VERSION "created by canmatrix"

NS_ :

BS_:

BU_: HEP IMU_MMP2 MAP DMS VIC GWS MGW ADAS FVC CR_RL CR_RR CR_FL CR_FR FR_FC AVAP

BO_ 603 MRR_0x25B: 2 ADAS
 SG_ ADAS_Fwd_Safety_Func : 7|16@0+ (1,0) [0|65535] ""  GWS

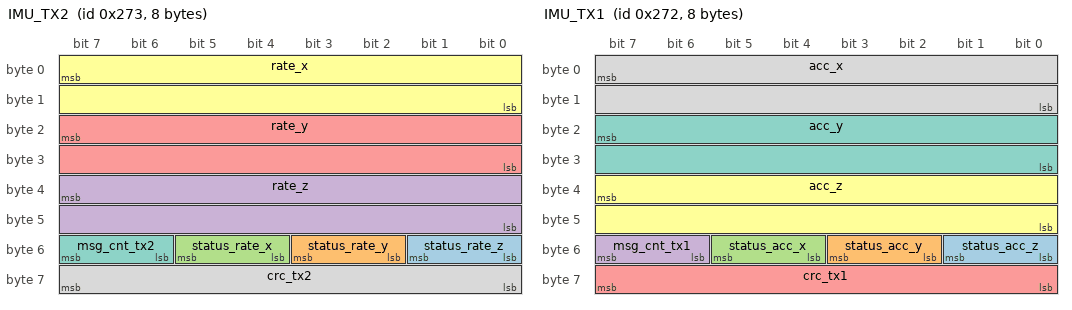
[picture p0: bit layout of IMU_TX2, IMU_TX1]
BO_ 627 IMU_TX2: 8 IMU_MMP2
 SG_ status_rate_z : 49|2@0+ (1,0) [0|3] ""  ADAS
 SG_ status_rate_y : 51|2@0+ (1,0) [0|3] ""  ADAS
 SG_ status_rate_x : 53|2@0+ (1,0) [0|3] ""  ADAS
 SG_ rate_z : 39|16@0- (0.01,0) [-327.68|327.68] "°/s"  ADAS
 SG_ rate_y : 23|16@0- (0.01,0) [-327.68|327.68] "°/s"  ADAS
 SG_ rate_x : 7|16@0- (0.01,0) [-327.68|327.68] "°/s"  ADAS
 SG_ msg_cnt_tx2 : 55|2@0+ (1,0) [0|3] ""  ADAS
 SG_ crc_tx2 : 63|8@0+ (1,0) [0|255] ""  ADAS

BO_ 626 IMU_TX1: 8 IMU_MMP2
 SG_ status_acc_z : 49|2@0+ (1,0) [0|3] ""  ADAS
 SG_ status_acc_y : 51|2@0+ (1,0) [0|3] ""  ADAS
 SG_ status_acc_x : 53|2@0+ (1,0) [0|3] ""  ADAS
 SG_ msg_cnt_tx1 : 55|2@0+ (1,0) [0|3] ""  ADAS
 SG_ crc_tx1 : 63|8@0+ (1,0) [0|255] ""  ADAS
 SG_ acc_z : 39|16@0- (0.0002,0) [-6.5536|6.5536] "g"  ADAS
 SG_ acc_y : 23|16@0- (0.0002,0) [-6.5536|6.5536] "g"  ADAS
 SG_ acc_x : 7|16@0- (0.0002,0) [-6.5536|6.5534] "g"  ADAS

BO_ 272 ADASLong_Mux: 8 HEP
 SG_ ADASLONG_Mux_MsgTyp : 7|3@0+ (1,0) [0|7] ""  ADAS

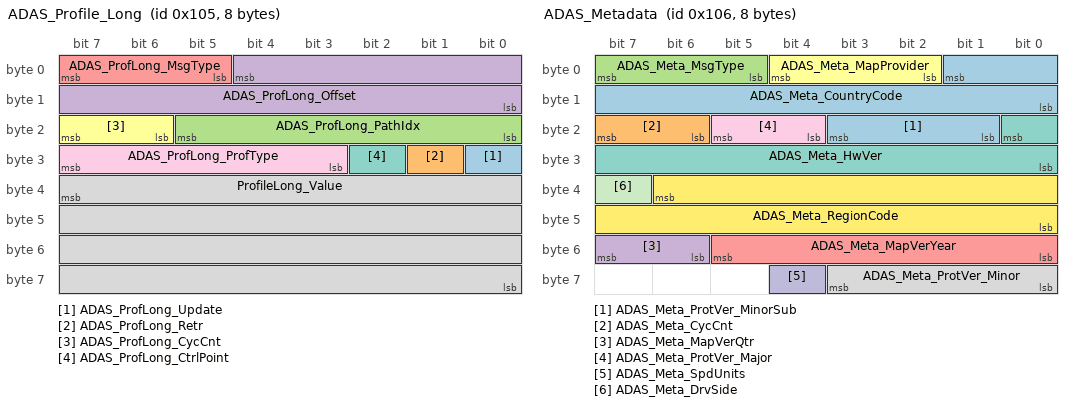
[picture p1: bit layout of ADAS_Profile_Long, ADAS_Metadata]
BO_ 261 ADAS_Profile_Long: 8 HEP
 SG_ ADAS_ProfLong_Update : 24|1@0+ (1,0) [0|0] ""  ADAS
 SG_ ADAS_ProfLong_Retr : 25|1@0+ (1,0) [0|1] ""  ADAS
 SG_ ADAS_ProfLong_PathIdx : 21|6@0+ (1,0) [8|63] ""  ADAS
 SG_ ADAS_ProfLong_Offset : 4|13@0+ (1,0) [0|8190] "m"  ADAS
 SG_ ADAS_ProfLong_MsgType : 7|3@0+ (1,0) [0|7] ""  ADAS
 SG_ ADAS_ProfLong_CycCnt : 23|2@0+ (1,0) [0|3] ""  ADAS
 SG_ ADAS_ProfLong_CtrlPoint : 26|1@0+ (1,0) [0|1] ""  ADAS
 SG_ ProfileLong_Value : 39|32@0+ (1,0) [0|0] ""  ADAS
 SG_ ADAS_ProfLong_ProfType : 31|5@0+ (1,0) [0|31] ""  ADAS

BO_ 262 ADAS_Metadata: 8 HEP
 SG_ ADAS_Meta_ProtVer_MinorSub : 19|3@0+ (1,0) [0|7] ""  ADAS
 SG_ ADAS_Meta_CycCnt : 23|2@0+ (1,0) [0|3] ""  ADAS
 SG_ ADAS_Meta_MsgType : 7|3@0+ (1,0) [0|7] ""  ADAS
 SG_ ADAS_Meta_MapVerQtr : 55|2@0+ (1,1) [1|4] "Qtr"  ADAS
 SG_ ADAS_Meta_MapVerYear : 53|6@0+ (1,2000) [2000|2063] "Year"  ADAS
 SG_ ADAS_Meta_MapProvider : 4|3@0+ (1,0) [0|7] ""  ADAS
 SG_ ADAS_Meta_HwVer : 16|9@0+ (1,0) [0|511] ""  ADAS
 SG_ ADAS_Meta_ProtVer_Minor : 59|4@0+ (1,0) [0|15] ""  ADAS
 SG_ ADAS_Meta_ProtVer_Major : 21|2@0+ (1,0) [0|3] ""  ADAS
 SG_ ADAS_Meta_SpdUnits : 60|1@0+ (1,0) [0|1] ""  ADAS
 SG_ ADAS_Meta_DrvSide : 39|1@0+ (1,0) [0|1] ""  ADAS
 SG_ ADAS_Meta_RegionCode : 38|15@0+ (1,0) [0|32767] ""  ADAS
 SG_ ADAS_Meta_CountryCode : 1|10@0+ (1,0) [0|1023] ""  ADAS

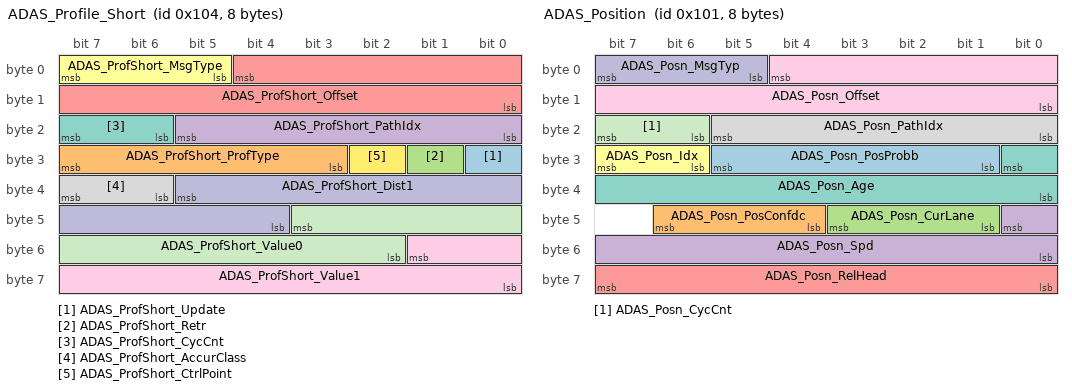
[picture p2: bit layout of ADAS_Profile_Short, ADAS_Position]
BO_ 260 ADAS_Profile_Short: 8 HEP
 SG_ ADAS_ProfShort_Update : 24|1@0+ (1,0) [0|0] ""  ADAS
 SG_ ADAS_ProfShort_ProfType : 31|5@0+ (1,0) [0|31] ""  ADAS
 SG_ ADAS_ProfShort_Retr : 25|1@0+ (1,0) [0|1] ""  ADAS
 SG_ ADAS_ProfShort_PathIdx : 21|6@0+ (1,0) [8|63] ""  ADAS
 SG_ ADAS_ProfShort_Offset : 4|13@0+ (1,0) [0|8190] "m"  ADAS
 SG_ ADAS_ProfShort_MsgType : 7|3@0+ (1,0) [0|7] ""  ADAS
 SG_ ADAS_ProfShort_CycCnt : 23|2@0+ (1,0) [0|3] ""  ADAS
 SG_ ADAS_ProfShort_AccurClass : 39|2@0+ (1,0) [0|3] ""  ADAS
 SG_ ADAS_ProfShort_Value1 : 49|10@0+ (1,0) [0|1023] ""  ADAS
 SG_ ADAS_ProfShort_Dist1 : 37|10@0+ (1,0) [0|1022] "m"  ADAS
 SG_ ADAS_ProfShort_Value0 : 43|10@0+ (1,0) [0|1023] ""  ADAS
 SG_ ADAS_ProfShort_CtrlPoint : 26|1@0+ (1,0) [0|1] ""  ADAS

BO_ 259 ADAS_Stub: 8 HEP
 SG_ ADAS_Stub_PartOfCalcRoute : 47|2@0+ (1,0) [0|3] ""  ADAS
 SG_ ADAS_Stub_FuncRoadClass : 34|3@0+ (1,0) [0|6] ""  ADAS
 SG_ ADAS_Stub_LastStub : 63|1@0+ (1,0) [0|1] ""  ADAS
 SG_ ADAS_Stub_Update : 24|1@0+ (1,0) [0|1] ""  ADAS
 SG_ ADAS_Stub_SubPathIdx : 31|6@0+ (1,0) [8|63] ""  ADAS
 SG_ ADAS_Stub_Retr : 25|1@0+ (1,0) [0|1] ""  ADAS
 SG_ ADAS_Stub_PathIdx : 21|6@0+ (1,0) [8|63] ""  ADAS
 SG_ ADAS_Stub_Offset : 4|13@0+ (1,0) [0|8190] "m"  ADAS
 SG_ ADAS_Stub_NumOfLaneOppDir : 60|2@0+ (1,0) [0|3] ""  ADAS
 SG_ ADAS_Stub_NumOfLaneDrvDir : 58|3@0+ (1,0) [0|7] ""  ADAS
 SG_ ADAS_Stub_MsgType : 7|3@0+ (1,0) [0|7] ""  ADAS
 SG_ ADAS_Stub_FormOfWay : 43|4@0+ (1,0) [0|14] ""  ADAS
 SG_ ADAS_Stub_CycCnt : 23|2@0+ (1,0) [0|3] ""  ADAS
 SG_ ADAS_Stub_RtOfWay : 62|2@0+ (1,0) [0|3] ""  ADAS
 SG_ ADAS_Stub_CmplxInsct : 45|2@0+ (1,0) [0|3] ""  ADAS
 SG_ ADAS_Stub_RelProbb : 39|5@0+ (3.333,0) [0|100] "%"  ADAS
 SG_ ADAS_Stub_TurnAngl : 55|8@0+ (1.417,0) [0|358] "deg"  ADAS

BO_ 258 ADAS_Segment: 8 HEP
 SG_ ADAS_Seg_PartOfCalcRoute : 47|2@0+ (1,0) [0|3] ""  ADAS
 SG_ ADAS_Seg_RelProbb : 39|5@0+ (3.333,0) [0|100] "%"  ADAS
 SG_ ADAS_Seg_Offset : 4|13@0+ (1,0) [0|8190] "m"  ADAS
 SG_ ADAS_Seg_Retr : 25|1@0+ (1,0) [0|1] ""  ADAS
 SG_ ADAS_Seg_PathIdx : 21|6@0+ (1,0) [8|63] ""  ADAS
 SG_ ADAS_Seg_MsgType : 7|3@0+ (1,0) [0|7] ""  ADAS
 SG_ ADAS_Seg_FormOfWay : 43|4@0+ (1,0) [0|14] ""  ADAS
 SG_ ADAS_Seg_CycCnt : 23|2@0+ (1,0) [0|3] ""  ADAS
 SG_ ADAS_Seg_CmplxInsct : 45|2@0+ (1,0) [0|3] ""  ADAS
 SG_ ADAS_Seg_BuildUpArea : 27|2@0+ (1,0) [0|3] ""  ADAS
 SG_ ADAS_Seg_DividedRoad : 62|2@0+ (1,0) [0|3] ""  ADAS
 SG_ ADAS_Seg_Bridge : 29|2@0+ (1,0) [0|3] ""  ADAS
 SG_ ADAS_Seg_Tunnel : 31|2@0+ (1,0) [0|3] ""  ADAS
 SG_ ADAS_Seg_NumOfLaneOppDir : 60|2@0+ (1,0) [0|3] ""  ADAS
 SG_ ADAS_Seg_NumOfLaneDrvDir : 58|3@0+ (1,0) [0|7] ""  ADAS
 SG_ ADAS_Seg_EffSpdLmtType : 50|3@0+ (1,0) [0|7] ""  ADAS
 SG_ ADAS_Seg_EffSpdLmt : 55|5@0+ (1,0) [0|0] "(k)mp/h"  ADAS
 SG_ ADAS_Seg_FuncRoadClass : 34|3@0+ (1,0) [0|6] ""  ADAS
 SG_ ADAS_Seg_Update : 24|1@0+ (1,0) [0|1] ""  ADAS

BO_ 257 ADAS_Position: 8 HEP
 SG_ ADAS_Posn_PosProbb : 29|5@0+ (3.333,0) [0|100] "%"  ADAS
 SG_ ADAS_Posn_PosConfdc : 46|3@0+ (1,0) [0|7] ""  ADAS
 SG_ ADAS_Posn_CurLane : 43|3@0+ (1,0) [0|7] ""  ADAS
 SG_ ADAS_Posn_Spd : 40|9@0+ (0.2,-12.8) [-12.8|89.2] "m/s"  ADAS
 SG_ ADAS_Posn_RelHead : 63|8@0+ (1.417,0) [0|358] "deg"  ADAS
 SG_ ADAS_Posn_Idx : 31|2@0+ (1,0) [0|3] ""  ADAS
 SG_ ADAS_Posn_Age : 24|9@0+ (5,0) [0|2545] "ms"  ADAS
 SG_ ADAS_Posn_PathIdx : 21|6@0+ (1,0) [8|63] ""  ADAS
 SG_ ADAS_Posn_Offset : 4|13@0+ (1,0) [0|8190] "m"  ADAS
 SG_ ADAS_Posn_MsgTyp : 7|3@0+ (1,0) [0|7] ""  ADAS
 SG_ ADAS_Posn_CycCnt : 23|2@0+ (1,0) [0|3] ""  ADAS

BO_ 1283 HIL_VP_TCC: 8 HEP
 SG_ HIL_Latitude_Cval_TCC : 0|32@1+ (1E-007,-210) [-210|211.1081215] "?"  ADAS
 SG_ HIL_Longitude_Cval_TCC : 32|32@1+ (1E-007,-210) [-210|211.1081215] "?"  ADAS

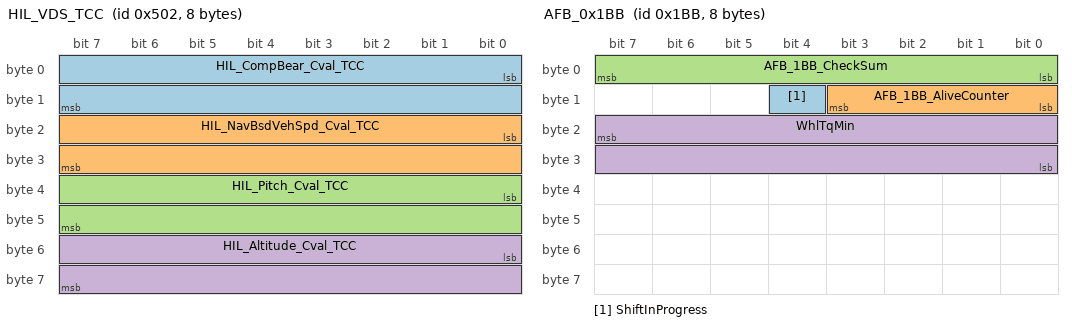
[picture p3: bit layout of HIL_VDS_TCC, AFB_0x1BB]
BO_ 1282 HIL_VDS_TCC: 8 HEP
 SG_ HIL_CompBear_Cval_TCC : 0|16@1+ (0.0078125,0) [0|501.9921875] "?"  ADAS
 SG_ HIL_NavBsdVehSpd_Cval_TCC : 16|16@1+ (0.00390625,0) [0|250.99609375] "km/h"  ADAS
 SG_ HIL_Pitch_Cval_TCC : 32|16@1+ (0.0078125,-200) [-200|301.9921875] "?"  ADAS
 SG_ HIL_Altitude_Cval_TCC : 48|16@1+ (0.125,-2500) [-2500|5531.875] "m"  ADAS

BO_ 443 AFB_0x1BB: 8 MGW
 SG_ ShiftInProgress : 12|1@0+ (1,0) [0|1] ""  ADAS
 SG_ AFB_1BB_AliveCounter : 11|4@0+ (1,0) [0|14] ""  ADAS
 SG_ AFB_1BB_CheckSum : 7|8@0+ (1,0) [0|255] ""  ADAS
 SG_ WhlTqMin : 23|16@0+ (1,-32768) [-32768|32767] "Nm"  ADAS

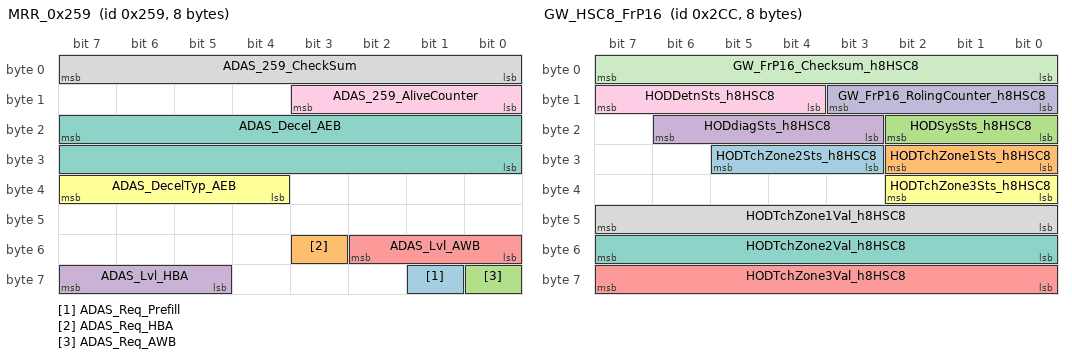
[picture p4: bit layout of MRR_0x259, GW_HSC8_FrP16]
BO_ 601 MRR_0x259: 8 ADAS
 SG_ ADAS_Req_Prefill : 57|1@0+ (1,0) [0|1] ""  MGW
 SG_ ADAS_Req_HBA : 51|1@0+ (1,0) [0|1] ""  MGW
 SG_ ADAS_Req_AWB : 56|1@0+ (1,0) [0|1] ""  MGW
 SG_ ADAS_Lvl_HBA : 63|3@0+ (1,0) [0|7] ""  MGW
 SG_ ADAS_Lvl_AWB : 50|3@0+ (1,0) [0|7] ""  MGW
 SG_ ADAS_DecelTyp_AEB : 39|4@0+ (1,0) [0|15] ""  MGW
 SG_ ADAS_Decel_AEB : 23|16@0+ (0.0004882,-16) [-16|15.994187] "m/s²"  MGW
 SG_ ADAS_259_CheckSum : 7|8@0+ (1,0) [0|255] ""  MGW
 SG_ ADAS_259_AliveCounter : 11|4@0+ (1,0) [0|15] ""  MGW

BO_ 716 GW_HSC8_FrP16: 8 MGW
 SG_ HODTchZone2Sts_h8HSC8 : 27|3@1+ (1,0) [0|7] ""  ADAS
 SG_ HODTchZone1Sts_h8HSC8 : 24|3@1+ (1,0) [0|7] ""  ADAS
 SG_ HODSysSts_h8HSC8 : 16|3@1+ (1,0) [0|7] ""  ADAS
 SG_ HODdiagSts_h8HSC8 : 19|4@1+ (1,0) [0|15] ""  ADAS
 SG_ HODTchZone3Val_h8HSC8 : 56|8@1+ (1,0) [0|255] ""  ADAS
 SG_ HODTchZone3Sts_h8HSC8 : 32|3@1+ (1,0) [0|7] ""  ADAS
 SG_ HODTchZone2Val_h8HSC8 : 48|8@1+ (1,0) [0|255] ""  ADAS
 SG_ HODTchZone1Val_h8HSC8 : 40|8@1+ (1,0) [0|255] ""  ADAS
 SG_ HODDetnSts_h8HSC8 : 12|4@1+ (1,0) [0|15] ""  ADAS
 SG_ GW_FrP16_RolingCounter_h8HSC8 : 8|4@1+ (1,0) [0|15] ""  ADAS
 SG_ GW_FrP16_Checksum_h8HSC8 : 0|8@1+ (1,0) [0|255] ""  ADAS

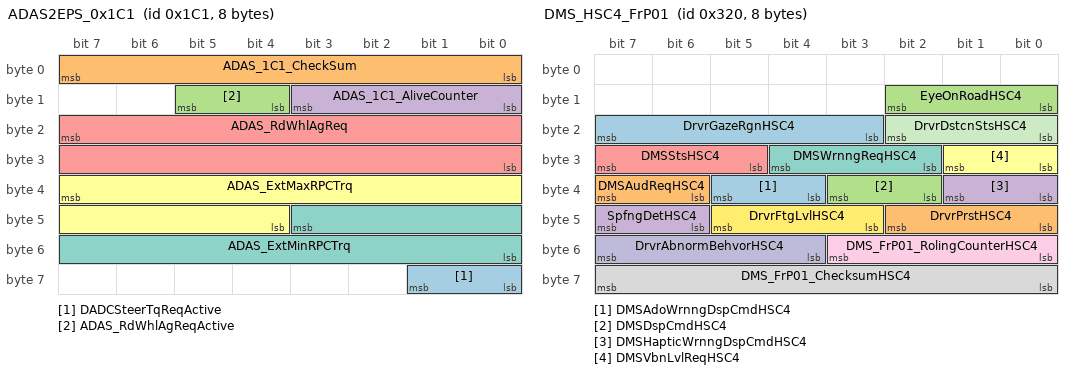
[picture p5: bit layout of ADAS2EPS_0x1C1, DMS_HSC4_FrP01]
BO_ 449 ADAS2EPS_0x1C1: 8 ADAS
 SG_ DADCSteerTqReqActive : 57|2@0+ (1,0) [0|3] ""  MGW
 SG_ ADAS_1C1_CheckSum : 7|8@0+ (1,0) [0|255] ""  MGW
 SG_ ADAS_RdWhlAgReqActive : 13|2@0+ (1,0) [0|3] ""  MGW
 SG_ ADAS_1C1_AliveCounter : 11|4@0+ (1,0) [0|15] ""  MGW
 SG_ ADAS_RdWhlAgReq : 23|16@0+ (0.005,-45) [-45|45] "degree"  MGW
 SG_ ADAS_ExtMaxRPCTrq : 39|12@0+ (0.02,-20.48) [-20.48|20.46] "Nm"  MGW
 SG_ ADAS_ExtMinRPCTrq : 43|12@0+ (0.02,-20.48) [-20.48|20.46] "Nm"  MGW

BO_ 1216 HDM_GF: 32 MAP
 SG_ GF_map_position_accuracy : 200|12@1+ (1,0) [0|4095] "cm"  ADAS
 SG_ GF_map_position_deviation : 188|12@1+ (1,0) [0|4095] "cm"  ADAS
 SG_ GF_CRC : 0|16@1+ (1,0) [0|65535] ""  ADAS
 SG_ GF_AliveCtr : 16|8@1+ (1,0) [0|255] ""  ADAS
 SG_ GF_Currentlane_Index : 176|8@1+ (1,0) [0|255] ""  ADAS
 SG_ GF_NumberOfLanes : 184|4@1+ (1,0) [0|15] ""  ADAS
 SG_ GF_Region_outOfODD_offset : 24|10@1+ (1,0) [0|1023] "m"  ADAS
 SG_ GF_Country_outOfODD_offset : 34|10@1+ (1,0) [0|1023] "m"  ADAS
 SG_ GF_LaneTrans_outOfODD_offset : 44|10@1+ (1,0) [0|1023] "m"  ADAS
 SG_ GF_Curvature_outOfODD_offset : 54|10@1+ (1,0) [0|1023] "m"  ADAS
 SG_ GF_LaneType_outOfODD_offset : 64|10@1+ (1,0) [0|1023] "m"  ADAS
 SG_ GF_RoadSlope_outOfODD_offset : 74|10@1+ (1,0) [0|1023] "m"  ADAS
 SG_ GF_LaneWidth_outOfODD_offset : 84|10@1+ (1,0) [0|1023] "m"  ADAS
 SG_ GF_FormOfWay_outOfODD_offset : 94|10@1+ (1,0) [0|1023] "m"  ADAS
 SG_ GF_MapExpired : 224|1@1+ (1,0) [0|1] "boolean"  ADAS
 SG_ GF_BlackListedSegment_offset : 114|10@1+ (1,0) [0|1023] "m"  ADAS
 SG_ GF_Intersection_offset : 104|10@1+ (1,0) [0|1023] "m"  ADAS
 SG_ GF_SideWind_offset : 124|10@1+ (1,0) [0|1023] "m"  ADAS
 SG_ GF_ActiveSpeedLimit : 168|8@1+ (1,0) [0|255] "km/h"  ADAS
 SG_ GF_TollGate_offset : 134|10@1+ (1,0) [0|1023] "m"  ADAS
 SG_ GF_TrafficLight_offset : 144|10@1+ (1,0) [0|1023] "m"  ADAS
 SG_ GF_Tunnel_Offset : 154|10@1+ (1,0) [0|1023] "m"  ADAS
 SG_ GF_MapStatus : 212|10@1+ (1,0) [0|1023] ""  ADAS

BO_ 1217 HDM_Curv: 64 MAP
 SG_ Cv_CRC : 0|16@1+ (1,0) [0|65535] ""  ADAS
 SG_ Cv_AliveCtr : 16|8@1+ (1,0) [0|255] ""  ADAS
 SG_ Cv_Value_Seg00 : 32|10@1+ (0.0001,0) [0|0.1] "1/m"  ADAS
 SG_ Cv_Value_Seg01 : 42|10@1+ (0.0001,0) [0|0.1] "1/m"  ADAS
 SG_ Cv_Value_Seg02 : 52|10@1+ (0.0001,0) [0|0.1] "1/m"  ADAS
 SG_ Cv_Value_Seg03 : 62|10@1+ (0.0001,0) [0|0.1] "1/m"  ADAS
 SG_ Cv_Value_Seg04 : 72|10@1+ (0.0001,0) [0|0.1] "1/m"  ADAS
 SG_ Cv_Value_Seg05 : 82|10@1+ (0.0001,0) [0|0.1] "1/m"  ADAS
 SG_ Cv_Value_Seg06 : 92|10@1+ (0.0001,0) [0|0.1] "1/m"  ADAS
 SG_ Cv_Value_Seg07 : 102|10@1+ (0.0001,0) [0|0.1] "1/m"  ADAS
 SG_ Cv_Value_Seg08 : 112|10@1+ (0.0001,0) [0|0.1] "1/m"  ADAS
 SG_ Cv_Value_Seg09 : 122|10@1+ (0.0001,0) [0|0.1] "1/m"  ADAS
 SG_ Cv_Value_Seg10 : 132|10@1+ (0.0001,0) [0|0.1] "1/m"  ADAS
 SG_ Cv_Value_Seg11 : 142|10@1+ (0.0001,0) [0|0.1] "1/m"  ADAS
 SG_ Cv_Value_Seg12 : 152|10@1+ (0.0001,0) [0|0.1] "1/m"  ADAS
 SG_ Cv_Value_Seg13 : 162|10@1+ (0.0001,0) [0|0.1] "1/m"  ADAS
 SG_ Cv_Value_Seg14 : 172|10@1+ (0.0001,0) [0|0.1] "1/m"  ADAS
 SG_ Cv_Value_Seg15 : 182|10@1+ (0.0001,0) [0|0.1] "1/m"  ADAS
 SG_ Cv_Value_Seg16 : 192|10@1+ (0.0001,0) [0|0.1] "1/m"  ADAS
 SG_ Cv_Value_Seg17 : 202|10@1+ (0.0001,0) [0|0.1] "1/m"  ADAS
 SG_ Cv_Value_Seg18 : 212|10@1+ (0.0001,0) [0|0.1] "1/m"  ADAS
 SG_ Cv_Value_Seg19 : 222|10@1+ (0.0001,0) [0|0.1] "1/m"  ADAS
 SG_ Cv_Offset_Seg00 : 232|10@1+ (1,0) [0|1023] "m"  ADAS
 SG_ Cv_Offset_Seg01 : 242|10@1+ (1,0) [0|1023] "m"  ADAS
 SG_ Cv_Offset_Seg02 : 252|10@1+ (1,0) [0|1023] "m"  ADAS
 SG_ Cv_Offset_Seg03 : 262|10@1+ (1,0) [0|1023] "m"  ADAS
 SG_ Cv_Offset_Seg04 : 272|10@1+ (1,0) [0|1023] "m"  ADAS
 SG_ Cv_Offset_Seg05 : 282|10@1+ (1,0) [0|1023] "m"  ADAS
 SG_ Cv_Offset_Seg06 : 292|10@1+ (1,0) [0|1023] "m"  ADAS
 SG_ Cv_Offset_Seg07 : 302|10@1+ (1,0) [0|1023] "m"  ADAS
 SG_ Cv_Offset_Seg08 : 312|10@1+ (1,0) [0|1023] "m"  ADAS
 SG_ Cv_Offset_Seg09 : 322|10@1+ (1,0) [0|1023] "m"  ADAS
 SG_ Cv_Offset_Seg10 : 332|10@1+ (1,0) [0|1023] "m"  ADAS
 SG_ Cv_Offset_Seg11 : 342|10@1+ (1,0) [0|1023] "m"  ADAS
 SG_ Cv_Offset_Seg12 : 352|10@1+ (1,0) [0|1023] "m"  ADAS
 SG_ Cv_Offset_Seg13 : 362|10@1+ (1,0) [0|1023] "m"  ADAS
 SG_ Cv_Offset_Seg14 : 372|10@1+ (1,0) [0|1023] "m"  ADAS
 SG_ Cv_Offset_Seg15 : 382|10@1+ (1,0) [0|1023] "m"  ADAS
 SG_ Cv_Offset_Seg16 : 392|10@1+ (1,0) [0|1023] "m"  ADAS
 SG_ Cv_Offset_Seg17 : 402|10@1+ (1,0) [0|1023] "m"  ADAS
 SG_ Cv_Offset_Seg18 : 412|10@1+ (1,0) [0|1023] "m"  ADAS
 SG_ Cv_Offset_Seg19 : 422|10@1+ (1,0) [0|1023] "m"  ADAS

BO_ 1220 HDM_Central_Line_M: 24 MAP
 SG_ centerline_m_CRC : 0|16@1+ (1,0) [0|65535] ""  ADAS
 SG_ centerline_m_AliveCtr : 16|8@1+ (1,0) [0|255] ""  ADAS
 SG_ centerline_m_BlockCtr : 24|4@1+ (1,0) [0|15] ""  ADAS
 SG_ CenterPoint_dx_m01 : 28|10@1+ (0.05,-50) [-50|0] "m"  ADAS
 SG_ CenterPoint_dy_m01 : 38|12@1+ (0.05,-102.4) [-102.4|102.35] "m"  ADAS
 SG_ CenterPoint_dx_m02 : 50|10@1+ (0.05,-50) [-50|0] "m"  ADAS
 SG_ CenterPoint_dy_m02 : 60|12@1+ (0.05,-102.4) [-102.4|102.35] "m"  ADAS
 SG_ CenterPoint_dx_m03 : 72|10@1+ (0.05,-50) [-50|0] "m"  ADAS
 SG_ CenterPoint_dy_m03 : 82|12@1+ (0.05,-102.4) [-102.4|102.35] "m"  ADAS
 SG_ CenterPoint_dx_m04 : 94|10@1+ (0.05,-50) [-50|0] "m"  ADAS
 SG_ CenterPoint_dy_m04 : 104|12@1+ (0.05,-102.4) [-102.4|102.35] "m"  ADAS
 SG_ MAP_TimeSync : 116|48@1+ (1,0) [0|39636172800000] "ms"  ADAS

BO_ 1218 HDM_Centerline_1: 64 MAP
 SG_ centerline_1_CRC : 0|16@1+ (1,0) [0|65535] ""  ADAS
 SG_ centerline_1_AliveCtr : 16|8@1+ (1,0) [0|255] ""  ADAS
 SG_ CenterPoint_dx_00 : 24|12@1+ (0.05,0) [0|204.75] "m"  ADAS
 SG_ CenterPoint_dy_00 : 36|12@1+ (0.05,-102.4) [-102.4|102.35] "m"  ADAS
 SG_ CenterPoint_dx_01 : 48|12@1+ (0.05,0) [0|204.75] "m"  ADAS
 SG_ CenterPoint_dy_01 : 60|12@1+ (0.05,-102.4) [-102.4|102.35] "m"  ADAS
 SG_ CenterPoint_dx_02 : 72|12@1+ (0.05,0) [0|204.75] "m"  ADAS
 SG_ CenterPoint_dy_02 : 84|12@1+ (0.05,-102.4) [-102.4|102.35] "m"  ADAS
 SG_ CenterPoint_dx_03 : 96|12@1+ (0.05,0) [0|204.75] "m"  ADAS
 SG_ CenterPoint_dy_03 : 108|12@1+ (0.05,-102.4) [-102.4|102.35] "m"  ADAS
 SG_ CenterPoint_dx_04 : 120|12@1+ (0.05,0) [0|204.75] "m"  ADAS
 SG_ CenterPoint_dy_04 : 132|12@1+ (0.05,-102.4) [-102.4|102.35] "m"  ADAS
 SG_ CenterPoint_dx_05 : 144|12@1+ (0.05,0) [0|204.75] "m"  ADAS
 SG_ CenterPoint_dy_05 : 156|12@1+ (0.05,-102.4) [-102.4|102.35] "m"  ADAS
 SG_ CenterPoint_dx_06 : 168|12@1+ (0.05,0) [0|204.75] "m"  ADAS
 SG_ CenterPoint_dy_06 : 180|12@1+ (0.05,-102.4) [-102.4|102.35] "m"  ADAS
 SG_ CenterPoint_dx_07 : 192|12@1+ (0.05,0) [0|204.75] "m"  ADAS
 SG_ CenterPoint_dy_07 : 204|12@1+ (0.05,-102.4) [-102.4|102.35] "m"  ADAS
 SG_ CenterPoint_dx_08 : 216|12@1+ (0.05,0) [0|204.75] "m"  ADAS
 SG_ CenterPoint_dy_08 : 228|12@1+ (0.05,-102.4) [-102.4|102.35] "m"  ADAS
 SG_ CenterPoint_dx_09 : 240|12@1+ (0.05,0) [0|204.75] "m"  ADAS
 SG_ CenterPoint_dy_09 : 252|12@1+ (0.05,-102.4) [-102.4|102.35] "m"  ADAS
 SG_ CenterPoint_dx_10 : 264|12@1+ (0.05,0) [0|204.75] "m"  ADAS
 SG_ CenterPoint_dy_10 : 276|12@1+ (0.05,-102.4) [-102.4|102.35] "m"  ADAS
 SG_ CenterPoint_dx_11 : 288|12@1+ (0.05,0) [0|204.75] "m"  ADAS
 SG_ CenterPoint_dy_11 : 300|12@1+ (0.05,-102.4) [-102.4|102.35] "m"  ADAS
 SG_ CenterPoint_dx_12 : 312|12@1+ (0.05,0) [0|204.75] "m"  ADAS
 SG_ CenterPoint_dy_12 : 324|12@1+ (0.05,-102.4) [-102.4|102.35] "m"  ADAS
 SG_ CenterPoint_dx_13 : 336|12@1+ (0.05,0) [0|204.75] "m"  ADAS
 SG_ CenterPoint_dy_13 : 348|12@1+ (0.05,-102.4) [-102.4|102.35] "m"  ADAS
 SG_ CenterPoint_dx_14 : 360|12@1+ (0.05,0) [0|204.75] "m"  ADAS
 SG_ CenterPoint_dy_14 : 372|12@1+ (0.05,-102.4) [-102.4|102.35] "m"  ADAS
 SG_ CenterPoint_dx_15 : 384|12@1+ (0.05,0) [0|204.75] "m"  ADAS
 SG_ CenterPoint_dy_15 : 396|12@1+ (0.05,-102.4) [-102.4|102.35] "m"  ADAS
 SG_ CenterPoint_dx_16 : 408|12@1+ (0.05,0) [0|204.75] "m"  ADAS
 SG_ CenterPoint_dy_16 : 420|12@1+ (0.05,-102.4) [-102.4|102.35] "m"  ADAS
 SG_ CenterPoint_dx_17 : 432|12@1+ (0.05,0) [0|204.75] "m"  ADAS
 SG_ CenterPoint_dy_17 : 444|12@1+ (0.05,-102.4) [-102.4|102.35] "m"  ADAS
 SG_ CenterPoint_dx_18 : 456|12@1+ (0.05,0) [0|204.75] "m"  ADAS
 SG_ CenterPoint_dy_18 : 468|12@1+ (0.05,-102.4) [-102.4|102.35] "m"  ADAS
 SG_ CenterPoint_dx_19 : 480|12@1+ (0.05,0) [0|204.75] "m"  ADAS
 SG_ CenterPoint_dy_19 : 492|12@1+ (0.05,-102.4) [-102.4|102.35] "m"  ADAS
 SG_ centerline_1_BlockCtr : 504|4@1+ (1,0) [0|15] ""  ADAS

BO_ 1219 HDM_Centerline_2: 64 MAP
 SG_ centerline_2_CRC : 0|16@1+ (1,0) [0|65535] ""  ADAS
 SG_ centerline_2_AliveCtr : 16|8@1+ (1,0) [0|255] ""  ADAS
 SG_ CenterPoint_dx_20 : 24|12@1+ (0.05,0) [0|204.75] "m"  ADAS
 SG_ CenterPoint_dy_20 : 36|12@1+ (0.05,-102.4) [-102.4|102.35] "m"  ADAS
 SG_ CenterPoint_dx_21 : 48|12@1+ (0.05,0) [0|204.75] "m"  ADAS
 SG_ CenterPoint_dy_21 : 60|12@1+ (0.05,-102.4) [-102.4|102.35] "m"  ADAS
 SG_ CenterPoint_dx_22 : 72|12@1+ (0.05,0) [0|204.75] "m"  ADAS
 SG_ CenterPoint_dy_22 : 84|12@1+ (0.05,-102.4) [-102.4|102.35] "m"  ADAS
 SG_ CenterPoint_dx_23 : 96|12@1+ (0.05,0) [0|204.75] "m"  ADAS
 SG_ CenterPoint_dy_23 : 108|12@1+ (0.05,-102.4) [-102.4|102.35] "m"  ADAS
 SG_ CenterPoint_dx_24 : 120|12@1+ (0.05,0) [0|204.75] "m"  ADAS
 SG_ CenterPoint_dy_24 : 132|12@1+ (0.05,-102.4) [-102.4|102.35] "m"  ADAS
 SG_ CenterPoint_dx_25 : 144|12@1+ (0.05,0) [0|204.75] "m"  ADAS
 SG_ CenterPoint_dy_25 : 156|12@1+ (0.05,-102.4) [-102.4|102.35] "m"  ADAS
 SG_ CenterPoint_dx_26 : 168|12@1+ (0.05,0) [0|204.75] "m"  ADAS
 SG_ CenterPoint_dy_26 : 180|12@1+ (0.05,-102.4) [-102.4|102.35] "m"  ADAS
 SG_ CenterPoint_dx_27 : 192|12@1+ (0.05,0) [0|204.75] "m"  ADAS
 SG_ CenterPoint_dy_27 : 204|12@1+ (0.05,-102.4) [-102.4|102.35] "m"  ADAS
 SG_ CenterPoint_dx_28 : 216|12@1+ (0.05,0) [0|204.75] "m"  ADAS
 SG_ CenterPoint_dy_28 : 228|12@1+ (0.05,-102.4) [-102.4|102.35] "m"  ADAS
 SG_ CenterPoint_dx_29 : 240|12@1+ (0.05,0) [0|204.75] "m"  ADAS
 SG_ CenterPoint_dy_29 : 252|12@1+ (0.05,-102.4) [-102.4|102.35] "m"  ADAS
 SG_ CenterPoint_dx_30 : 264|12@1+ (0.05,0) [0|204.75] "m"  ADAS
 SG_ CenterPoint_dy_30 : 276|12@1+ (0.05,-102.4) [-102.4|102.35] "m"  ADAS
 SG_ CenterPoint_dx_31 : 288|12@1+ (0.05,0) [0|204.75] "m"  ADAS
 SG_ CenterPoint_dy_31 : 300|12@1+ (0.05,-102.4) [-102.4|102.35] "m"  ADAS
 SG_ CenterPoint_dx_32 : 312|12@1+ (0.05,0) [0|204.75] "m"  ADAS
 SG_ CenterPoint_dy_32 : 324|12@1+ (0.05,-102.4) [-102.4|102.35] "m"  ADAS
 SG_ CenterPoint_dx_33 : 336|12@1+ (0.05,0) [0|204.75] "m"  ADAS
 SG_ CenterPoint_dy_33 : 348|12@1+ (0.05,-102.4) [-102.4|102.35] "m"  ADAS
 SG_ CenterPoint_dx_34 : 360|12@1+ (0.05,0) [0|204.75] "m"  ADAS
 SG_ CenterPoint_dy_34 : 372|12@1+ (0.05,-102.4) [-102.4|102.35] "m"  ADAS
 SG_ centerline_LaneWidth : 384|9@1+ (1,0) [0|511] "cm"  ADAS
 SG_ localization_lat_StdDev : 393|12@1+ (0.01,0) [0|40.95] "m"  ADAS
 SG_ localization_long_StdDev : 405|12@1+ (0.01,0) [0|40.95] "m"  ADAS
 SG_ localization_heading_StdDev : 417|11@1+ (0.1,0) [0|204.7] "degree"  ADAS
 SG_ map_position_deviation : 428|12@1+ (1,0) [0|4095] "cm"  ADAS
 SG_ map_position_accuracy : 440|12@1+ (1,0) [0|4095] "cm"  ADAS
 SG_ Timestamp : 452|20@1+ (0.00065536,0) [0|687.194112] "s"  ADAS
 SG_ centerline_2_BlockCtr : 472|4@1+ (1,0) [0|15] ""  ADAS

BO_ 1221 HDM_Central_Line_HighR: 64 MAP
 SG_ centerline_HR_CRC : 0|16@1+ (1,0) [0|65535] ""  ADAS
 SG_ centerline_HR_AliveCtr : 16|8@1+ (1,0) [0|255] ""  ADAS
 SG_ centerline_HR_BlockCtr : 24|4@1+ (1,0) [0|15] ""  ADAS
 SG_ CenterPoint_dx_m01_HighR : 28|6@1+ (0.001,0) [0|0.049] "m"  ADAS
 SG_ CenterPoint_dy_m01_HighR : 34|6@1+ (0.001,0) [0|0.049] "m"  ADAS
 SG_ CenterPoint_dy_m02_HighR : 40|6@1+ (0.001,0) [0|0.049] "m"  ADAS
 SG_ CenterPoint_dx_m02_HighR : 46|6@1+ (0.001,0) [0|0.049] "m"  ADAS
 SG_ CenterPoint_dy_m03_HighR : 52|6@1+ (0.001,0) [0|0.049] "m"  ADAS
 SG_ CenterPoint_dx_m03_HighR : 58|6@1+ (0.001,0) [0|0.049] "m"  ADAS
 SG_ CenterPoint_dy_m04_HighR : 64|6@1+ (0.001,0) [0|0.049] "m"  ADAS
 SG_ CenterPoint_dx_m04_HighR : 70|6@1+ (0.001,0) [0|0.049] "m"  ADAS
 SG_ CenterPoint_dy_00_HighR : 76|6@1+ (0.001,0) [0|0.049] "m"  ADAS
 SG_ CenterPoint_dx_00_HighR : 82|6@1+ (0.001,0) [0|0.049] "m"  ADAS
 SG_ CenterPoint_dy_01_HighR : 88|6@1+ (0.001,0) [0|0.049] "m"  ADAS
 SG_ CenterPoint_dx_01_HighR : 94|6@1+ (0.001,0) [0|0.049] "m"  ADAS
 SG_ CenterPoint_dy_02_HighR : 100|6@1+ (0.001,0) [0|0.049] "m"  ADAS
 SG_ CenterPoint_dx_02_HighR : 106|6@1+ (0.001,0) [0|0.049] "m"  ADAS
 SG_ CenterPoint_dy_03_HighR : 112|6@1+ (0.001,0) [0|0.049] "m"  ADAS
 SG_ CenterPoint_dx_03_HighR : 118|6@1+ (0.001,0) [0|0.049] "m"  ADAS
 SG_ CenterPoint_dy_04_HighR : 124|6@1+ (0.001,0) [0|0.049] "m"  ADAS
 SG_ CenterPoint_dx_04_HighR : 130|6@1+ (0.001,0) [0|0.049] "m"  ADAS
 SG_ CenterPoint_dy_05_HighR : 136|6@1+ (0.001,0) [0|0.049] "m"  ADAS
 SG_ CenterPoint_dx_05_HighR : 142|6@1+ (0.001,0) [0|0.049] "m"  ADAS
 SG_ CenterPoint_dy_06_HighR : 148|6@1+ (0.001,0) [0|0.049] "m"  ADAS
 SG_ CenterPoint_dx_06_HighR : 154|6@1+ (0.001,0) [0|0.049] "m"  ADAS
 SG_ CenterPoint_dy_07_HighR : 160|6@1+ (0.001,0) [0|0.049] "m"  ADAS
 SG_ CenterPoint_dx_07_HighR : 166|6@1+ (0.001,0) [0|0.049] "m"  ADAS
 SG_ CenterPoint_dy_08_HighR : 172|6@1+ (0.001,0) [0|0.049] "m"  ADAS
 SG_ CenterPoint_dx_08_HighR : 178|6@1+ (0.001,0) [0|0.049] "m"  ADAS
 SG_ CenterPoint_dy_09_HighR : 184|6@1+ (0.001,0) [0|0.049] "m"  ADAS
 SG_ CenterPoint_dx_09_HighR : 190|6@1+ (0.001,0) [0|0.049] "m"  ADAS
 SG_ CenterPoint_dy_10_HighR : 196|6@1+ (0.001,0) [0|0.049] "m"  ADAS
 SG_ CenterPoint_dx_10_HighR : 202|6@1+ (0.001,0) [0|0.049] "m"  ADAS
 SG_ CenterPoint_dy_11_HighR : 208|6@1+ (0.001,0) [0|0.049] "m"  ADAS
 SG_ CenterPoint_dx_11_HighR : 214|6@1+ (0.001,0) [0|0.049] "m"  ADAS
 SG_ CenterPoint_dy_12_HighR : 220|6@1+ (0.001,0) [0|0.049] "m"  ADAS
 SG_ CenterPoint_dx_12_HighR : 226|6@1+ (0.001,0) [0|0.049] "m"  ADAS
 SG_ CenterPoint_dy_13_HighR : 232|6@1+ (0.001,0) [0|0.049] "m"  ADAS
 SG_ CenterPoint_dx_13_HighR : 238|6@1+ (0.001,0) [0|0.049] "m"  ADAS
 SG_ CenterPoint_dy_14_HighR : 244|6@1+ (0.001,0) [0|0.049] "m"  ADAS
 SG_ CenterPoint_dx_14_HighR : 250|6@1+ (0.001,0) [0|0.049] "m"  ADAS
 SG_ CenterPoint_dy_15_HighR : 256|6@1+ (0.001,0) [0|0.049] "m"  ADAS
 SG_ CenterPoint_dx_15_HighR : 262|6@1+ (0.001,0) [0|0.049] "m"  ADAS
 SG_ CenterPoint_dy_16_HighR : 268|6@1+ (0.001,0) [0|0.049] "m"  ADAS
 SG_ CenterPoint_dx_16_HighR : 274|6@1+ (0.001,0) [0|0.049] "m"  ADAS
 SG_ CenterPoint_dy_17_HighR : 280|6@1+ (0.001,0) [0|0.049] "m"  ADAS
 SG_ CenterPoint_dx_17_HighR : 286|6@1+ (0.001,0) [0|0.049] "m"  ADAS
 SG_ CenterPoint_dy_18_HighR : 292|6@1+ (0.001,0) [0|0.049] "m"  ADAS
 SG_ CenterPoint_dx_18_HighR : 298|6@1+ (0.001,0) [0|0.049] "m"  ADAS
 SG_ CenterPoint_dy_19_HighR : 304|6@1+ (0.001,0) [0|0.049] "m"  ADAS
 SG_ CenterPoint_dx_19_HighR : 310|6@1+ (0.001,0) [0|0.049] "m"  ADAS
 SG_ CenterPoint_dy_20_HighR : 316|6@1+ (0.001,0) [0|0.049] "m"  ADAS
 SG_ CenterPoint_dx_20_HighR : 322|6@1+ (0.001,0) [0|0.049] "m"  ADAS
 SG_ CenterPoint_dy_21_HighR : 328|6@1+ (0.001,0) [0|0.049] "m"  ADAS
 SG_ CenterPoint_dx_21_HighR : 334|6@1+ (0.001,0) [0|0.049] "m"  ADAS
 SG_ CenterPoint_dy_22_HighR : 340|6@1+ (0.001,0) [0|0.049] "m"  ADAS
 SG_ CenterPoint_dx_22_HighR : 346|6@1+ (0.001,0) [0|0.049] "m"  ADAS
 SG_ CenterPoint_dy_23_HighR : 352|6@1+ (0.001,0) [0|0.049] "m"  ADAS
 SG_ CenterPoint_dx_23_HighR : 358|6@1+ (0.001,0) [0|0.049] "m"  ADAS
 SG_ CenterPoint_dy_24_HighR : 364|6@1+ (0.001,0) [0|0.049] "m"  ADAS
 SG_ CenterPoint_dx_24_HighR : 370|6@1+ (0.001,0) [0|0.049] "m"  ADAS
 SG_ CenterPoint_dy_25_HighR : 376|6@1+ (0.001,0) [0|0.049] "m"  ADAS
 SG_ CenterPoint_dx_25_HighR : 382|6@1+ (0.001,0) [0|0.049] "m"  ADAS
 SG_ CenterPoint_dy_26_HighR : 388|6@1+ (0.001,0) [0|0.049] "m"  ADAS
 SG_ CenterPoint_dx_26_HighR : 394|6@1+ (0.001,0) [0|0.049] "m"  ADAS
 SG_ CenterPoint_dy_27_HighR : 400|6@1+ (0.001,0) [0|0.049] "m"  ADAS
 SG_ CenterPoint_dx_27_HighR : 406|6@1+ (0.001,0) [0|0.049] "m"  ADAS
 SG_ CenterPoint_dy_28_HighR : 412|6@1+ (0.001,0) [0|0.049] "m"  ADAS
 SG_ CenterPoint_dx_28_HighR : 418|6@1+ (0.001,0) [0|0.049] "m"  ADAS
 SG_ CenterPoint_dy_29_HighR : 424|6@1+ (0.001,0) [0|0.049] "m"  ADAS
 SG_ CenterPoint_dx_29_HighR : 430|6@1+ (0.001,0) [0|0.049] "m"  ADAS
 SG_ CenterPoint_dy_30_HighR : 436|6@1+ (0.001,0) [0|0.049] "m"  ADAS
 SG_ CenterPoint_dx_30_HighR : 442|6@1+ (0.001,0) [0|0.049] "m"  ADAS
 SG_ CenterPoint_dy_31_HighR : 448|6@1+ (0.001,0) [0|0.049] "m"  ADAS
 SG_ CenterPoint_dx_31_HighR : 454|6@1+ (0.001,0) [0|0.049] "m"  ADAS
 SG_ CenterPoint_dy_32_HighR : 460|6@1+ (0.001,0) [0|0.049] "m"  ADAS
 SG_ CenterPoint_dx_32_HighR : 466|6@1+ (0.001,0) [0|0.049] "m"  ADAS
 SG_ CenterPoint_dy_33_HighR : 472|6@1+ (0.001,0) [0|0.049] "m"  ADAS
 SG_ CenterPoint_dx_33_HighR : 478|6@1+ (0.001,0) [0|0.049] "m"  ADAS
 SG_ CenterPoint_dy_34_HighR : 484|6@1+ (0.001,0) [0|0.049] "m"  ADAS
 SG_ CenterPoint_dx_34_HighR : 490|6@1+ (0.001,0) [0|0.049] "m"  ADAS

BO_ 1226 EHR_ReferenceLine1_0x4CA: 64 MAP
 SG_ ReferenceLine1_CRC : 0|16@1+ (1,0) [0|65535] ""  ADAS
 SG_ ReferenceLine1_AliveCtr : 16|8@1+ (1,0) [0|255] ""  ADAS
 SG_ ReferenceLine1_TimeStamp : 24|20@1+ (0.00065536,0) [0|687.194] "s"  ADAS
 SG_ ReferenceLine_point_N : 44|6@1+ (1,0) [0|63] ""  ADAS
 SG_ ReferenceLine_dx_00 : 50|12@1+ (0.05,0) [0|204.75] "m"  ADAS
 SG_ ReferenceLine_dy_00 : 62|12@1+ (0.05,-102.4) [-102.4|102.35] "m"  ADAS
 SG_ ReferenceLine_dx_01 : 74|12@1+ (0.05,0) [0|204.75] "m"  ADAS
 SG_ ReferenceLine_dy_01 : 86|12@1+ (0.05,-102.4) [-102.4|102.35] "m"  ADAS
 SG_ ReferenceLine_dx_02 : 98|12@1+ (0.05,0) [0|204.75] "m"  ADAS
 SG_ ReferenceLine_dy_02 : 110|12@1+ (0.05,-102.4) [-102.4|102.35] "m"  ADAS
 SG_ ReferenceLine_dx_03 : 122|12@1+ (0.05,0) [0|204.75] "m"  ADAS
 SG_ ReferenceLine_dy_03 : 134|12@1+ (0.05,-102.4) [-102.4|102.35] "m"  ADAS
 SG_ ReferenceLine_dx_04 : 146|12@1+ (0.05,0) [0|204.75] "m"  ADAS
 SG_ ReferenceLine_dy_04 : 158|12@1+ (0.05,-102.4) [-102.4|102.35] "m"  ADAS
 SG_ ReferenceLine_dx_05 : 170|12@1+ (0.05,0) [0|204.75] "m"  ADAS
 SG_ ReferenceLine_dy_05 : 182|12@1+ (0.05,-102.4) [-102.4|102.35] "m"  ADAS
 SG_ ReferenceLine_dx_06 : 194|12@1+ (0.05,0) [0|204.75] "m"  ADAS
 SG_ ReferenceLine_dy_06 : 206|12@1+ (0.05,-102.4) [-102.4|102.35] "m"  ADAS
 SG_ ReferenceLine_dx_07 : 218|12@1+ (0.05,0) [0|204.75] "m"  ADAS
 SG_ ReferenceLine_dy_07 : 230|12@1+ (0.05,-102.4) [-102.4|102.35] "m"  ADAS
 SG_ ReferenceLine_dx_08 : 242|12@1+ (0.05,0) [0|204.75] "m"  ADAS
 SG_ ReferenceLine_dy_08 : 254|12@1+ (0.05,-102.4) [-102.4|102.35] "m"  ADAS
 SG_ ReferenceLine_dx_09 : 266|12@1+ (0.05,0) [0|204.75] "m"  ADAS
 SG_ ReferenceLine_dy_09 : 278|12@1+ (0.05,-102.4) [-102.4|102.35] "m"  ADAS
 SG_ ReferenceLine_dx_10 : 290|12@1+ (0.05,0) [0|204.75] "m"  ADAS
 SG_ ReferenceLine_dy_10 : 302|12@1+ (0.05,-102.4) [-102.4|102.35] "m"  ADAS
 SG_ ReferenceLine_dx_11 : 314|12@1+ (0.05,0) [0|204.75] "m"  ADAS
 SG_ ReferenceLine_dy_11 : 326|12@1+ (0.05,-102.4) [-102.4|102.35] "m"  ADAS
 SG_ ReferenceLine_dx_12 : 338|12@1+ (0.05,0) [0|204.75] "m"  ADAS
 SG_ ReferenceLine_dy_12 : 350|12@1+ (0.05,-102.4) [-102.4|102.35] "m"  ADAS
 SG_ ReferenceLine_dx_13 : 362|12@1+ (0.05,0) [0|204.75] "m"  ADAS
 SG_ ReferenceLine_dy_13 : 374|12@1+ (0.05,-102.4) [-102.4|102.35] "m"  ADAS
 SG_ ReferenceLine_dx_14 : 386|12@1+ (0.05,0) [0|204.75] "m"  ADAS
 SG_ ReferenceLine_dy_14 : 398|12@1+ (0.05,-102.4) [-102.4|102.35] "m"  ADAS
 SG_ ReferenceLine_dx_15 : 410|12@1+ (0.05,0) [0|204.75] "m"  ADAS
 SG_ ReferenceLine_dy_15 : 422|12@1+ (0.05,-102.4) [-102.4|102.35] "m"  ADAS
 SG_ ReferenceLine_dx_16 : 434|12@1+ (0.05,0) [0|204.75] "m"  ADAS
 SG_ ReferenceLine_dy_16 : 446|12@1+ (0.05,-102.4) [-102.4|102.35] "m"  ADAS
 SG_ ReferenceLine_dx_17 : 458|12@1+ (0.05,0) [0|204.75] "m"  ADAS
 SG_ ReferenceLine_dy_17 : 470|12@1+ (0.05,-102.4) [-102.4|102.35] "m"  ADAS
 SG_ ReferenceLine_dx_18 : 482|12@1+ (0.05,0) [0|204.75] "m"  ADAS
 SG_ ReferenceLine_dy_18 : 494|12@1+ (0.05,-102.4) [-102.4|102.35] "m"  ADAS

BO_ 1227 EHR_ReferenceLine2_0x4CB: 64 MAP
 SG_ ReferenceLine2_CRC : 0|16@1+ (1,0) [0|65535] ""  ADAS
 SG_ ReferenceLine2_AliveCtr : 16|8@1+ (1,0) [0|255] ""  ADAS
 SG_ ReferenceLine2_TimeStamp : 24|20@1+ (0.00065536,0) [0|687.194] "s"  ADAS
 SG_ ReferenceLine_dx_19 : 44|12@1+ (0.05,0) [0|204.75] "m"  ADAS
 SG_ ReferenceLine_dy_19 : 56|12@1+ (0.05,-102.4) [-102.4|102.35] "m"  ADAS
 SG_ ReferenceLine_dx_20 : 68|12@1+ (0.05,0) [0|204.75] "m"  ADAS
 SG_ ReferenceLine_dy_20 : 80|12@1+ (0.05,-102.4) [-102.4|102.35] "m"  ADAS
 SG_ ReferenceLine_dx_21 : 92|12@1+ (0.05,0) [0|204.75] "m"  ADAS
 SG_ ReferenceLine_dy_21 : 104|12@1+ (0.05,-102.4) [-102.4|102.35] "m"  ADAS
 SG_ ReferenceLine_dx_22 : 116|12@1+ (0.05,0) [0|204.75] "m"  ADAS
 SG_ ReferenceLine_dy_22 : 128|12@1+ (0.05,-102.4) [-102.4|102.35] "m"  ADAS
 SG_ ReferenceLine_dx_23 : 140|12@1+ (0.05,0) [0|204.75] "m"  ADAS
 SG_ ReferenceLine_dy_23 : 152|12@1+ (0.05,-102.4) [-102.4|102.35] "m"  ADAS
 SG_ ReferenceLine_dx_24 : 164|12@1+ (0.05,0) [0|204.75] "m"  ADAS
 SG_ ReferenceLine_dy_24 : 176|12@1+ (0.05,-102.4) [-102.4|102.35] "m"  ADAS
 SG_ ReferenceLine_dx_25 : 188|12@1+ (0.05,0) [0|204.75] "m"  ADAS
 SG_ ReferenceLine_dy_25 : 200|12@1+ (0.05,-102.4) [-102.4|102.35] "m"  ADAS
 SG_ ReferenceLine_dx_26 : 212|12@1+ (0.05,0) [0|204.75] "m"  ADAS
 SG_ ReferenceLine_dy_26 : 224|12@1+ (0.05,-102.4) [-102.4|102.35] "m"  ADAS
 SG_ ReferenceLine_dx_27 : 236|12@1+ (0.05,0) [0|204.75] "m"  ADAS
 SG_ ReferenceLine_dy_27 : 248|12@1+ (0.05,-102.4) [-102.4|102.35] "m"  ADAS
 SG_ ReferenceLine_dx_28 : 260|12@1+ (0.05,0) [0|204.75] "m"  ADAS
 SG_ ReferenceLine_dy_28 : 272|12@1+ (0.05,-102.4) [-102.4|102.35] "m"  ADAS
 SG_ ReferenceLine_dx_29 : 284|12@1+ (0.05,0) [0|204.75] "m"  ADAS
 SG_ ReferenceLine_dy_29 : 296|12@1+ (0.05,-102.4) [-102.4|102.35] "m"  ADAS
 SG_ ReferenceLine_dx_30 : 308|12@1+ (0.05,0) [0|204.75] "m"  ADAS
 SG_ ReferenceLine_dy_30 : 320|12@1+ (0.05,-102.4) [-102.4|102.35] "m"  ADAS
 SG_ ReferenceLine_dx_31 : 332|12@1+ (0.05,0) [0|204.75] "m"  ADAS
 SG_ ReferenceLine_dy_31 : 344|12@1+ (0.05,-102.4) [-102.4|102.35] "m"  ADAS
 SG_ ReferenceLine_dx_32 : 356|12@1+ (0.05,0) [0|204.75] "m"  ADAS
 SG_ ReferenceLine_dy_32 : 368|12@1+ (0.05,-102.4) [-102.4|102.35] "m"  ADAS
 SG_ ReferenceLine_dx_33 : 380|12@1+ (0.05,0) [0|204.75] "m"  ADAS
 SG_ ReferenceLine_dy_33 : 392|12@1+ (0.05,-102.4) [-102.4|102.35] "m"  ADAS
 SG_ ReferenceLine_dx_34 : 404|12@1+ (0.05,0) [0|204.75] "m"  ADAS
 SG_ ReferenceLine_dy_34 : 416|12@1+ (0.05,-102.4) [-102.4|102.35] "m"  ADAS

BO_ 1228 EHR_Ego_Lane_Info1_0x4CC: 48 MAP
 SG_ Ego_Lane_Info1_CRC : 0|16@1+ (1,0) [0|65535] ""  ADAS
 SG_ Ego_Lane_Info1_AliveCtr : 16|8@1+ (1,0) [0|255] ""  ADAS
 SG_ Ego_Lane_Info1_TimeStamp : 24|20@1+ (0.00065536,0) [0|687.194112] "s"  ADAS
 SG_ Ego_Lane_Map_Status : 44|2@1+ (1,0) [0|1] ""  ADAS
 SG_ Ego_Lane_CurrentSpeedLimit : 46|5@1+ (5,0) [0|130] "km/h"  ADAS
 SG_ Ego_Lane_CurrentSpeedLimit_Type : 51|2@1+ (1,0) [0|3] ""  ADAS
 SG_ Ego_Lane_NextSpeedLimit_Value_1 : 53|5@1+ (5,0) [0|130] "km/h"  ADAS
 SG_ Ego_Lane_NextSpeedLimit_Loc_1 : 58|12@1+ (1,0) [0|4000] "m"  ADAS
 SG_ Ego_Lane_NextSpeedLimit_Type_1 : 70|2@1+ (1,0) [0|3] ""  ADAS
 SG_ Ego_Lane_NextSpeedLimit_Value_2 : 72|5@1+ (5,0) [0|130] "km/h"  ADAS
 SG_ Ego_Lane_NextSpeedLimit_Loc_2 : 77|12@1+ (1,0) [0|4000] "m"  ADAS
 SG_ Ego_Lane_NextSpeedLimit_Type_2 : 89|2@1+ (1,0) [0|3] ""  ADAS
 SG_ Ego_Lane_NextSpeedLimit_Value_3 : 91|5@1+ (5,0) [0|130] "km/h"  ADAS
 SG_ Ego_Lane_NextSpeedLimit_Loc_3 : 96|12@1+ (1,0) [0|4000] "m"  ADAS
 SG_ Ego_Lane_NextSpeedLimit_Type_3 : 108|2@1+ (1,0) [0|3] ""  ADAS
 SG_ Ego_Lane_NextSpeedLimit_Value_4 : 110|5@1+ (5,0) [0|130] "km/h"  ADAS
 SG_ Ego_Lane_NextSpeedLimit_Loc_4 : 115|12@1+ (1,0) [0|4000] "m"  ADAS
 SG_ Ego_Lane_NextSpeedLimit_Type_4 : 127|2@1+ (1,0) [0|3] ""  ADAS
 SG_ Ego_Lane_NextTopoLocation_1 : 129|11@1+ (1,0) [0|2000] "m"  ADAS
 SG_ Ego_Lane_NextTopoType_1 : 140|3@1+ (1,0) [0|6] ""  ADAS
 SG_ Ego_Lane_NextTopoSide_1 : 143|1@1+ (1,0) [0|1] ""  ADAS
 SG_ Ego_Lane_NextTopoLocation_2 : 144|11@1+ (1,0) [0|2000] "m"  ADAS
 SG_ Ego_Lane_NextTopoType_2 : 155|3@1+ (1,0) [0|6] ""  ADAS
 SG_ Ego_Lane_NextTopoSide_2 : 158|1@1+ (1,0) [0|1] ""  ADAS
 SG_ Ego_Lane_NextTopoLocation_3 : 159|11@1+ (1,0) [0|2000] "m"  ADAS
 SG_ Ego_Lane_NextTopoType_3 : 170|3@1+ (1,0) [0|6] ""  ADAS
 SG_ Ego_Lane_NextTopoSide_3 : 173|1@1+ (1,0) [0|1] ""  ADAS
 SG_ Ego_Lane_NextTopoLocation_4 : 174|11@1+ (1,0) [0|2000] "m"  ADAS
 SG_ Ego_Lane_NextTopoType_4 : 185|3@1+ (1,0) [0|6] ""  ADAS
 SG_ Ego_Lane_NextTopoSide_4 : 188|1@1+ (1,0) [0|1] ""  ADAS
 SG_ Ego_Lane_CurrBoundary_Type_R : 189|5@1+ (1,0) [0|19] ""  ADAS
 SG_ Ego_Lane_NextBoundary_Loc_R_1 : 194|11@1+ (1,0) [0|2000] "m"  ADAS
 SG_ Ego_Lane_NextBoundary_Type_R_1 : 205|5@1+ (1,0) [0|19] ""  ADAS
 SG_ Ego_Lane_NextBoundary_Loc_R_2 : 210|11@1+ (1,0) [0|2000] "m"  ADAS
 SG_ Ego_Lane_NextBoundary_Type_R_2 : 221|5@1+ (1,0) [0|19] ""  ADAS
 SG_ Ego_Lane_NextBoundary_Loc_R_3 : 226|11@1+ (1,0) [0|2000] "m"  ADAS
 SG_ Ego_Lane_NextBoundary_Type_R_3 : 237|5@1+ (1,0) [0|19] ""  ADAS
 SG_ Ego_Lane_NextBoundary_Loc_R_4 : 242|11@1+ (1,0) [0|2000] "m"  ADAS
 SG_ Ego_Lane_NextBoundary_Type_R_4 : 253|5@1+ (1,0) [0|19] ""  ADAS
 SG_ Ego_Lane_CurrBoundary_Type_L : 258|5@1+ (1,0) [0|19] ""  ADAS
 SG_ Ego_Lane_NextBoundary_Loc_L_1 : 263|11@1+ (1,0) [0|2000] "m"  ADAS
 SG_ Ego_Lane_NextBoundary_Type_L_1 : 274|5@1+ (1,0) [0|19] ""  ADAS
 SG_ Ego_Lane_NextBoundary_Loc_L_2 : 279|11@1+ (1,0) [0|2000] "m"  ADAS
 SG_ Ego_Lane_NextBoundary_Type_L_2 : 290|5@1+ (1,0) [0|19] ""  ADAS
 SG_ Ego_Lane_NextBoundary_Loc_L_3 : 295|11@1+ (1,0) [0|2000] "m"  ADAS
 SG_ Ego_Lane_NextBoundary_Type_L_3 : 306|5@1+ (1,0) [0|19] ""  ADAS
 SG_ Ego_Lane_NextBoundary_Loc_L_4 : 311|11@1+ (1,0) [0|2000] "m"  ADAS
 SG_ Ego_Lane_NextBoundary_Type_L_4 : 322|5@1+ (1,0) [0|19] ""  ADAS

BO_ 1229 EHR_Ego_Lane_Info2_0x4CD: 64 MAP
 SG_ Ego_Lane_Info2_CRC : 0|16@1+ (1,0) [0|65535] ""  ADAS
 SG_ Ego_Lane_Info2_AliveCtr : 16|8@1+ (1,0) [0|255] ""  ADAS
 SG_ Ego_Lane_Info2_TimeStamp : 24|20@1+ (0.00065536,0) [0|687.194112] "s"  ADAS
 SG_ Ego_Lane_SpeedProfile_Near_N : 44|5@1+ (1,0) [0|31] ""  ADAS
 SG_ Ego_Lane_SpeedProfile_Near_00 : 49|7@1+ (2,0) [0|200] "km/h"  ADAS
 SG_ Ego_Lane_SpeedProfile_Near_01 : 56|7@1+ (2,0) [0|200] "km/h"  ADAS
 SG_ Ego_Lane_SpeedProfile_Near_02 : 63|7@1+ (2,0) [0|200] "km/h"  ADAS
 SG_ Ego_Lane_SpeedProfile_Near_03 : 70|7@1+ (2,0) [0|200] "km/h"  ADAS
 SG_ Ego_Lane_SpeedProfile_Near_04 : 77|7@1+ (2,0) [0|200] "km/h"  ADAS
 SG_ Ego_Lane_SpeedProfile_Near_05 : 84|7@1+ (2,0) [0|200] "km/h"  ADAS
 SG_ Ego_Lane_SpeedProfile_Near_06 : 91|7@1+ (2,0) [0|200] "km/h"  ADAS
 SG_ Ego_Lane_SpeedProfile_Near_07 : 98|7@1+ (2,0) [0|200] "km/h"  ADAS
 SG_ Ego_Lane_SpeedProfile_Near_08 : 105|7@1+ (2,0) [0|200] "km/h"  ADAS
 SG_ Ego_Lane_SpeedProfile_Near_09 : 112|7@1+ (2,0) [0|200] "km/h"  ADAS
 SG_ Ego_Lane_SpeedProfile_Near_10 : 119|7@1+ (2,0) [0|200] "km/h"  ADAS
 SG_ Ego_Lane_SpeedProfile_Near_11 : 126|7@1+ (2,0) [0|200] "km/h"  ADAS
 SG_ Ego_Lane_SpeedProfile_Near_12 : 133|7@1+ (2,0) [0|200] "km/h"  ADAS
 SG_ Ego_Lane_SpeedProfile_Near_13 : 140|7@1+ (2,0) [0|200] "km/h"  ADAS
 SG_ Ego_Lane_SpeedProfile_Near_14 : 147|7@1+ (2,0) [0|200] "km/h"  ADAS
 SG_ Ego_Lane_SpeedProfile_Near_15 : 154|7@1+ (2,0) [0|200] "km/h"  ADAS
 SG_ Ego_Lane_SpeedProfile_Near_16 : 161|7@1+ (2,0) [0|200] "km/h"  ADAS
 SG_ Ego_Lane_SpeedProfile_Near_17 : 168|7@1+ (2,0) [0|200] "km/h"  ADAS
 SG_ Ego_Lane_SpeedProfile_Near_18 : 175|7@1+ (2,0) [0|200] "km/h"  ADAS
 SG_ Ego_Lane_SpeedProfile_Near_19 : 182|7@1+ (2,0) [0|200] "km/h"  ADAS
 SG_ Ego_Lane_SpeedProfile_Near_20 : 189|7@1+ (2,0) [0|200] "km/h"  ADAS
 SG_ Ego_Lane_SpeedProfile_Near_21 : 196|7@1+ (2,0) [0|200] "km/h"  ADAS
 SG_ Ego_Lane_SpeedProfile_Near_22 : 203|7@1+ (2,0) [0|200] "km/h"  ADAS
 SG_ Ego_Lane_SpeedProfile_Far_N : 210|5@1+ (1,0) [0|31] ""  ADAS
 SG_ Ego_Lane_SpeedProfile_Far_00 : 215|7@1+ (2,0) [0|200] "km/h"  ADAS
 SG_ Ego_Lane_SpeedProfile_Far_01 : 222|7@1+ (2,0) [0|200] "km/h"  ADAS
 SG_ Ego_Lane_SpeedProfile_Far_02 : 229|7@1+ (2,0) [0|200] "km/h"  ADAS
 SG_ Ego_Lane_SpeedProfile_Far_03 : 236|7@1+ (2,0) [0|200] "km/h"  ADAS
 SG_ Ego_Lane_SpeedProfile_Far_04 : 243|7@1+ (2,0) [0|200] "km/h"  ADAS
 SG_ Ego_Lane_SpeedProfile_Far_05 : 250|7@1+ (2,0) [0|200] "km/h"  ADAS
 SG_ Ego_Lane_SpeedProfile_Far_06 : 257|7@1+ (2,0) [0|200] "km/h"  ADAS
 SG_ Ego_Lane_SpeedProfile_Far_07 : 264|7@1+ (2,0) [0|200] "km/h"  ADAS
 SG_ Ego_Lane_SpeedProfile_Far_08 : 271|7@1+ (2,0) [0|200] "km/h"  ADAS
 SG_ Ego_Lane_SpeedProfile_Far_09 : 278|7@1+ (2,0) [0|200] "km/h"  ADAS
 SG_ Ego_Lane_SpeedProfile_Far_10 : 285|7@1+ (2,0) [0|200] "km/h"  ADAS
 SG_ Ego_Lane_SpeedProfile_Far_11 : 292|7@1+ (2,0) [0|200] "km/h"  ADAS
 SG_ Ego_Lane_SpeedProfile_Far_12 : 299|7@1+ (2,0) [0|200] "km/h"  ADAS
 SG_ Ego_Lane_SpeedProfile_Far_13 : 306|7@1+ (2,0) [0|200] "km/h"  ADAS
 SG_ Ego_Lane_SpeedProfile_Far_14 : 313|7@1+ (2,0) [0|200] "km/h"  ADAS
 SG_ Ego_Lane_SpeedProfile_Far_15 : 320|7@1+ (2,0) [0|200] "km/h"  ADAS
 SG_ Ego_Lane_SpeedProfile_Far_16 : 327|7@1+ (2,0) [0|200] "km/h"  ADAS
 SG_ Ego_Lane_NextHotspot_Type_1 : 334|3@1+ (1,0) [0|3] ""  ADAS
 SG_ Ego_Lane_NextHotspot_Loc_1 : 337|11@1+ (1,0) [0|2000] "m"  ADAS
 SG_ Ego_Lane_NextHotspot_Length_1 : 348|8@1+ (10,0) [0|2000] "m"  ADAS
 SG_ Ego_Lane_NextHotspot_Int_1 : 356|6@1+ (0.015873,0) [0|1] ""  ADAS
 SG_ Ego_Lane_NextHotspot_Prob_1 : 362|8@1+ (0.00392157,0) [0|1] ""  ADAS
 SG_ Ego_Lane_NextHotspot_Side_1 : 370|1@1+ (1,0) [0|1] ""  ADAS
 SG_ Ego_Lane_NextHotspot_Type_2 : 371|3@1+ (1,0) [0|3] ""  ADAS
 SG_ Ego_Lane_NextHotspot_Loc_2 : 374|11@1+ (1,0) [0|2000] "m"  ADAS
 SG_ Ego_Lane_NextHotspot_Length_2 : 385|8@1+ (10,0) [0|2000] "m"  ADAS
 SG_ Ego_Lane_NextHotspot_Int_2 : 393|6@1+ (0.015873,0) [0|1] ""  ADAS
 SG_ Ego_Lane_NextHotspot_Prob_2 : 399|8@1+ (0.00392157,0) [0|1] ""  ADAS
 SG_ Ego_Lane_NextHotspot_Side_2 : 407|1@1+ (1,0) [0|1] ""  ADAS
 SG_ Ego_Lane_NextHotspot_Type_3 : 408|3@1+ (1,0) [0|3] ""  ADAS
 SG_ Ego_Lane_NextHotspot_Loc_3 : 411|11@1+ (1,0) [0|2000] "m"  ADAS
 SG_ Ego_Lane_NextHotspot_Length_3 : 422|8@1+ (10,0) [0|2000] "m"  ADAS
 SG_ Ego_Lane_NextHotspot_Int_3 : 430|6@1+ (0.015873,0) [0|1] ""  ADAS
 SG_ Ego_Lane_NextHotspot_Prob_3 : 436|8@1+ (0.00392157,0) [0|1] ""  ADAS
 SG_ Ego_Lane_NextHotspot_Side_3 : 444|1@1+ (1,0) [0|1] ""  ADAS
 SG_ Ego_Lane_NextHotspot_Type_4 : 445|3@1+ (1,0) [0|3] ""  ADAS
 SG_ Ego_Lane_NextHotspot_Loc_4 : 448|11@1+ (1,0) [0|2000] "m"  ADAS
 SG_ Ego_Lane_NextHotspot_Length_4 : 459|8@1+ (10,0) [0|2000] "m"  ADAS
 SG_ Ego_Lane_NextHotspot_Int_4 : 467|6@1+ (0.015873,0) [0|1] ""  ADAS
 SG_ Ego_Lane_NextHotspot_Prob_4 : 473|8@1+ (0.00392157,0) [0|1] ""  ADAS
 SG_ Ego_Lane_NextHotspot_Side_4 : 481|1@1+ (1,0) [0|1] ""  ADAS

BO_ 1230 EHR_Left_Lane_info_0x4CE: 48 MAP
 SG_ Left_Lane_Info_CRC : 0|16@1+ (1,0) [0|65535] ""  ADAS
 SG_ Left_Lane_Info_AliveCtr : 16|8@1+ (1,0) [0|255] ""  ADAS
 SG_ Left_Lane_Info_TimeStamp : 24|20@1+ (0.00065536,0) [0|687.194112] "s"  ADAS
 SG_ Left_Lane_Exists : 44|1@1+ (1,0) [0|1] ""  ADAS
 SG_ Left_Lane_isOvertakeLane : 45|1@1+ (1,0) [0|1] ""  ADAS
 SG_ Left_Lane_Start_dx : 46|12@1+ (1,0) [0|4000] ""  ADAS
 SG_ Left_CurrentSpeedLimit : 58|5@1+ (5,0) [0|130] "km/h"  ADAS
 SG_ Left_CurrentSpeedLimit_Type : 63|2@1+ (1,0) [0|3] ""  ADAS
 SG_ Left_NextSpeedLimit_Value_1 : 65|5@1+ (5,0) [0|130] "km/h"  ADAS
 SG_ Left_NextSpeedLimit_Location_1 : 70|12@1+ (1,0) [0|4000] "m"  ADAS
 SG_ Left_NextSpeedLimit_Type_1 : 82|2@1+ (1,0) [0|3] ""  ADAS
 SG_ Left_NextSpeedLimit_Value_2 : 84|5@1+ (5,0) [0|130] "km/h"  ADAS
 SG_ Left_NextSpeedLimit_Location_2 : 89|12@1+ (1,0) [0|4000] "m"  ADAS
 SG_ Left_NextSpeedLimit_Type_2 : 101|2@1+ (1,0) [0|3] ""  ADAS
 SG_ Left_NextSpeedLimit_Value_3 : 103|5@1+ (5,0) [0|130] "km/h"  ADAS
 SG_ Left_NextSpeedLimit_Location_3 : 108|12@1+ (1,0) [0|4000] "m"  ADAS
 SG_ Left_NextSpeedLimit_Type_3 : 120|2@1+ (1,0) [0|3] ""  ADAS
 SG_ Left_NextSpeedLimit_Value_4 : 122|5@1+ (5,0) [0|130] "km/h"  ADAS
 SG_ Left_NextSpeedLimit_Location_4 : 127|12@1+ (1,0) [0|4000] "m"  ADAS
 SG_ Left_NextSpeedLimit_Type_4 : 139|2@1+ (1,0) [0|3] ""  ADAS
 SG_ Left_SpeedProfile_Far_N : 141|5@1+ (1,0) [0|31] ""  ADAS
 SG_ Left_SpeedProfile_Far_00 : 146|7@1+ (2,0) [0|200] "km/h"  ADAS
 SG_ Left_SpeedProfile_Far_01 : 153|7@1+ (2,0) [0|200] "km/h"  ADAS
 SG_ Left_SpeedProfile_Far_02 : 160|7@1+ (2,0) [0|200] "km/h"  ADAS
 SG_ Left_SpeedProfile_Far_03 : 167|7@1+ (2,0) [0|200] "km/h"  ADAS
 SG_ Left_SpeedProfile_Far_04 : 174|7@1+ (2,0) [0|200] "km/h"  ADAS
 SG_ Left_SpeedProfile_Far_05 : 181|7@1+ (2,0) [0|200] "km/h"  ADAS
 SG_ Left_SpeedProfile_Far_06 : 188|7@1+ (2,0) [0|200] "km/h"  ADAS
 SG_ Left_SpeedProfile_Far_07 : 195|7@1+ (2,0) [0|200] "km/h"  ADAS
 SG_ Left_SpeedProfile_Far_08 : 202|7@1+ (2,0) [0|200] "km/h"  ADAS
 SG_ Left_SpeedProfile_Far_09 : 209|7@1+ (2,0) [0|200] "km/h"  ADAS
 SG_ Left_SpeedProfile_Far_10 : 216|7@1+ (2,0) [0|200] "km/h"  ADAS
 SG_ Left_SpeedProfile_Far_11 : 223|7@1+ (2,0) [0|200] "km/h"  ADAS
 SG_ Left_SpeedProfile_Far_12 : 230|7@1+ (2,0) [0|200] "km/h"  ADAS
 SG_ Left_SpeedProfile_Far_13 : 237|7@1+ (2,0) [0|200] "km/h"  ADAS
 SG_ Left_SpeedProfile_Far_14 : 244|7@1+ (2,0) [0|200] "km/h"  ADAS
 SG_ Left_SpeedProfile_Far_15 : 251|7@1+ (2,0) [0|200] "km/h"  ADAS
 SG_ Left_SpeedProfile_Far_16 : 258|7@1+ (2,0) [0|200] "km/h"  ADAS
 SG_ Left_NextTopo_Loc_1 : 265|11@1+ (1,0) [0|2000] "m"  ADAS
 SG_ Left_NextTopo_Type_1 : 276|3@1+ (1,0) [0|6] ""  ADAS
 SG_ Left_NextTopo_Side_1 : 279|1@1+ (1,0) [0|1] ""  ADAS
 SG_ Left_NextTopo_Loc_2 : 280|11@1+ (1,0) [0|2000] "m"  ADAS
 SG_ Left_NextTopo_Type_2 : 291|3@1+ (1,0) [0|6] ""  ADAS
 SG_ Left_NextTopo_Side_2 : 294|1@1+ (1,0) [0|1] ""  ADAS
 SG_ Left_NextTopo_Loc_3 : 295|11@1+ (1,0) [0|2000] "m"  ADAS
 SG_ Left_NextTopo_Type_3 : 306|3@1+ (1,0) [0|6] ""  ADAS
 SG_ Left_NextTopo_Side_3 : 309|1@1+ (1,0) [0|1] ""  ADAS
 SG_ Left_NextTopo_Loc_4 : 310|11@1+ (1,0) [0|2000] "m"  ADAS
 SG_ Left_NextTopo_Type_4 : 321|3@1+ (1,0) [0|6] ""  ADAS
 SG_ Left_NextTopo_Side_4 : 324|1@1+ (1,0) [0|1] ""  ADAS

BO_ 1231 EHR_Right_Lane_info_0x4CF: 48 MAP
 SG_ Right_Lane_Info_CRC : 0|16@1+ (1,0) [0|65535] ""  ADAS
 SG_ Right_Lane_Info_AliveCtr : 16|8@1+ (1,0) [0|255] ""  ADAS
 SG_ Right_Lane_Info_TimeStamp : 24|20@1+ (0.00065536,0) [0|687.194112] "s"  ADAS
 SG_ Right_Lane_Exists : 44|1@1+ (1,0) [0|1] ""  ADAS
 SG_ Right_Lane_isOvertakeLane : 45|1@1+ (1,0) [0|1] ""  ADAS
 SG_ Right_Lane_Start_dx : 46|12@1+ (1,0) [0|4000] ""  ADAS
 SG_ Right_CurrentSpeedLimit : 58|5@1+ (5,0) [0|130] "km/h"  ADAS
 SG_ Right_CurrentSpeedLimit_Type : 63|2@1+ (1,0) [0|3] ""  ADAS
 SG_ Right_NextSpeedLimit_Value_1 : 65|5@1+ (5,0) [0|130] "km/h"  ADAS
 SG_ Right_NextSpeedLimit_Location_1 : 70|12@1+ (1,0) [0|4000] "m"  ADAS
 SG_ Right_NextSpeedLimit_Type_1 : 82|2@1+ (1,0) [0|1] ""  ADAS
 SG_ Right_NextSpeedLimit_Value_2 : 84|5@1+ (5,0) [0|130] "km/h"  ADAS
 SG_ Right_NextSpeedLimit_Location_2 : 89|12@1+ (1,0) [0|4000] "m"  ADAS
 SG_ Right_NextSpeedLimit_Type_2 : 101|2@1+ (1,0) [0|3] ""  ADAS
 SG_ Right_NextSpeedLimit_Value_3 : 103|5@1+ (5,0) [0|130] "km/h"  ADAS
 SG_ Right_NextSpeedLimit_Location_3 : 108|12@1+ (1,0) [0|4000] "m"  ADAS
 SG_ Right_NextSpeedLimit_Type_3 : 120|2@1+ (1,0) [0|3] ""  ADAS
 SG_ Right_NextSpeedLimit_Value_4 : 122|5@1+ (5,0) [0|130] "km/h"  ADAS
 SG_ Right_NextSpeedLimit_Location_4 : 127|12@1+ (1,0) [0|4000] "m"  ADAS
 SG_ Right_NextSpeedLimit_Type_4 : 139|2@1+ (1,0) [0|3] ""  ADAS
 SG_ Right_SpeedProfile_Far_N : 141|5@1+ (1,0) [0|31] ""  ADAS
 SG_ Right_SpeedProfile_Far_00 : 146|7@1+ (2,0) [0|200] "km/h"  ADAS
 SG_ Right_SpeedProfile_Far_01 : 153|7@1+ (2,0) [0|200] "km/h"  ADAS
 SG_ Right_SpeedProfile_Far_02 : 160|7@1+ (2,0) [0|200] "km/h"  ADAS
 SG_ Right_SpeedProfile_Far_03 : 167|7@1+ (2,0) [0|200] "km/h"  ADAS
 SG_ Right_SpeedProfile_Far_04 : 174|7@1+ (2,0) [0|200] "km/h"  ADAS
 SG_ Right_SpeedProfile_Far_05 : 181|7@1+ (2,0) [0|200] "km/h"  ADAS
 SG_ Right_SpeedProfile_Far_06 : 188|7@1+ (2,0) [0|200] "km/h"  ADAS
 SG_ Right_SpeedProfile_Far_07 : 195|7@1+ (2,0) [0|200] "km/h"  ADAS
 SG_ Right_SpeedProfile_Far_08 : 202|7@1+ (2,0) [0|200] "km/h"  ADAS
 SG_ Right_SpeedProfile_Far_09 : 209|7@1+ (2,0) [0|200] "km/h"  ADAS
 SG_ Right_SpeedProfile_Far_10 : 216|7@1+ (2,0) [0|200] "km/h"  ADAS
 SG_ Right_SpeedProfile_Far_11 : 223|7@1+ (2,0) [0|200] "km/h"  ADAS
 SG_ Right_SpeedProfile_Far_12 : 230|7@1+ (2,0) [0|200] "km/h"  ADAS
 SG_ Right_SpeedProfile_Far_13 : 237|7@1+ (2,0) [0|200] "km/h"  ADAS
 SG_ Right_SpeedProfile_Far_14 : 244|7@1+ (2,0) [0|200] "km/h"  ADAS
 SG_ Right_SpeedProfile_Far_15 : 251|7@1+ (2,0) [0|200] "km/h"  ADAS
 SG_ Right_SpeedProfile_Far_16 : 258|7@1+ (2,0) [0|200] "km/h"  ADAS
 SG_ Right_NextTopo_Loc_1 : 265|11@1+ (1,0) [0|2000] "m"  ADAS
 SG_ Right_NextTopo_Type_1 : 276|3@1+ (1,0) [0|6] ""  ADAS
 SG_ Right_NextTopo_Side_1 : 279|1@1+ (1,0) [0|1] ""  ADAS
 SG_ Right_NextTopo_Loc_2 : 280|11@1+ (1,0) [0|2000] "m"  ADAS
 SG_ Right_NextTopo_Type_2 : 291|3@1+ (1,0) [0|6] ""  ADAS
 SG_ Right_NextTopo_Side_2 : 294|1@1+ (1,0) [0|1] ""  ADAS
 SG_ Right_NextTopo_Loc_3 : 295|11@1+ (1,0) [0|2000] "m"  ADAS
 SG_ Right_NextTopo_Type_3 : 306|3@1+ (1,0) [0|6] ""  ADAS
 SG_ Right_NextTopo_Side_3 : 309|1@1+ (1,0) [0|1] ""  ADAS
 SG_ Right_NextTopo_Loc_4 : 310|11@1+ (1,0) [0|2000] "m"  ADAS
 SG_ Right_NextTopo_Type_4 : 321|3@1+ (1,0) [0|6] ""  ADAS
 SG_ Right_NextTopo_Side_4 : 324|1@1+ (1,0) [0|1] ""  ADAS

BO_ 800 DMS_HSC4_FrP01: 8 DMS
 SG_ DMSAdoWrnngDspCmdHSC4 : 37|2@0+ (1,0) [0|3] ""  ADAS
 SG_ DMSAudReqHSC4 : 39|2@0+ (1,0) [0|3] ""  ADAS
 SG_ DMSDspCmdHSC4 : 35|2@0+ (1,0) [0|3] ""  ADAS
 SG_ DMSHapticWrnngDspCmdHSC4 : 33|2@0+ (1,0) [0|3] ""  ADAS
 SG_ DMSStsHSC4 : 31|3@0+ (1,0) [0|7] ""  ADAS
 SG_ DMSVbnLvlReqHSC4 : 25|2@0+ (1,0) [0|3] ""  ADAS
 SG_ DMSWrnngReqHSC4 : 28|3@0+ (1,0) [0|7] ""  ADAS
 SG_ DMS_FrP01_ChecksumHSC4 : 63|8@0+ (1,0) [0|255] ""  ADAS
 SG_ DMS_FrP01_RolingCounterHSC4 : 51|4@0+ (1,0) [0|15] "count value"  ADAS
 SG_ DrvrAbnormBehvorHSC4 : 55|4@0+ (1,0) [0|15] ""  ADAS
 SG_ DrvrDstcnStsHSC4 : 18|3@0+ (1,0) [0|7] ""  ADAS
 SG_ DrvrFtgLvlHSC4 : 45|3@0+ (1,0) [0|7] ""  ADAS
 SG_ DrvrGazeRgnHSC4 : 23|5@0+ (1,0) [0|31] ""  ADAS
 SG_ DrvrPrstHSC4 : 42|3@0+ (1,0) [0|7] ""  ADAS
 SG_ EyeOnRoadHSC4 : 10|3@0+ (1,0) [0|7] ""  ADAS
 SG_ SpfngDetHSC4 : 47|2@0+ (1,0) [0|3] ""  ADAS

BO_ 453 EPS2ADAS_0x1C5: 12 MGW
 SG_ ADAS_1C5_CheckSum : 7|8@0+ (1,0) [0|255] ""  ADAS
 SG_ ADAS_1C5_AliveCounter : 11|4@0+ (1,0) [0|15] ""  ADAS
 SG_ EPS_ActRoadWheelAngValue : 23|16@0+ (0.005,-45) [-45|45] "degree"  ADAS
 SG_ EPS_ActRPCTrq : 39|11@0+ (0.02,-20.48) [-20.48|20.46] "Nm"  ADAS
 SG_ EPS_LatDrvLvl12SrvAvl : 44|2@0+ (1,0) [0|3] ""  ADAS
 SG_ EPS_IntRPCMaxTrq : 42|11@0+ (0.02,-20.48) [-20.48|20.46] "Nm"  ADAS
 SG_ EPS_IntRPCMinTrq : 63|11@0+ (0.02,-20.48) [-20.48|20.46] "Nm"  ADAS
 SG_ EPS_LatMCHptcWrnSrvAvl : 68|2@0+ (1,0) [0|3] ""  ADAS
 SG_ EPS_ActRoadWheelAngState : 66|2@0+ (1,0) [0|3] ""  ADAS
 SG_ EPS_LatMCRoadWheelAngActive : 64|1@0+ (1,0) [0|1] ""  ADAS

BO_ 1210 ADAS_0x4BA_HMI: 64 ADAS
 SG_ DisplayedLaneMarking4Y : 432|8@1- (0.06,0) [-7.68|7.62] "m"  VIC,MGW
 SG_ DisplayedLaneMarking3Y : 424|8@1- (0.06,0) [-7.68|7.62] "m"  VIC,MGW
 SG_ DisplayedLaneMarking2Y : 416|8@1- (0.06,0) [-7.68|7.62] "m"  VIC,MGW
 SG_ DisplayedLaneMarking1Y : 408|8@1- (0.06,0) [-7.68|7.62] "m"  VIC,MGW
 SG_ DisplayedLaneMarking4Type : 406|2@1+ (1,0) [0|3] ""  VIC,MGW
 SG_ DisplayedLaneMarking3Type : 404|2@1+ (1,0) [0|3] ""  VIC,MGW
 SG_ DisplayedLaneMarking2Type : 402|2@1+ (1,0) [0|3] ""  VIC,MGW
 SG_ DisplayedLaneMarking1Type : 400|2@1+ (1,0) [0|3] ""  VIC,MGW
 SG_ DisplayedLaneMarking4Color : 395|3@1+ (1,0) [0|7] ""  VIC,MGW
 SG_ DisplayedLaneMarking3Color : 392|3@1+ (1,0) [0|7] ""  VIC,MGW
 SG_ DisplayedLaneMarking2Color : 387|3@1+ (1,0) [0|7] ""  VIC,MGW
 SG_ DisplayedLaneMarking1Color : 384|3@1+ (1,0) [0|7] ""  VIC,MGW
 SG_ Number02 : 368|16@1+ (1,0) [0|0] ""  VIC,MGW
 SG_ Number01 : 352|16@1+ (1,0) [0|0] ""  VIC,MGW
 SG_ Indicator16 : 351|1@1+ (1,0) [0|1] ""  VIC,MGW
 SG_ Indicator15 : 350|1@1+ (1,0) [0|1] ""  VIC,MGW
 SG_ Indicator14 : 349|1@1+ (1,0) [0|1] ""  VIC,MGW
 SG_ Indicator13 : 348|1@1+ (1,0) [0|1] ""  VIC,MGW
 SG_ Indicator12 : 347|1@1+ (1,0) [0|1] ""  VIC,MGW
 SG_ Indicator11 : 346|1@1+ (1,0) [0|1] ""  VIC,MGW
 SG_ Indicator10 : 345|1@1+ (1,0) [0|1] ""  VIC,MGW
 SG_ Indicator09 : 344|1@1+ (1,0) [0|1] ""  VIC,MGW
 SG_ Indicator08 : 343|1@1+ (1,0) [0|1] ""  VIC,MGW
 SG_ Indicator07 : 342|1@1+ (1,0) [0|1] ""  VIC,MGW
 SG_ Indicator06 : 341|1@1+ (1,0) [0|1] ""  VIC,MGW
 SG_ Indicator05 : 340|1@1+ (1,0) [0|1] ""  VIC,MGW
 SG_ Indicator04 : 339|1@1+ (1,0) [0|1] ""  VIC,MGW
 SG_ Indicator03 : 338|1@1+ (1,0) [0|1] ""  VIC,MGW
 SG_ Indicator02 : 337|1@1+ (1,0) [0|1] ""  VIC,MGW
 SG_ Indicator01 : 336|1@1+ (1,0) [0|1] ""  VIC,MGW
 SG_ ACC_ICON_LADI : 334|2@1+ (1,0) [0|3] ""  VIC,MGW
 SG_ ADAS_4BA_CheckSum : 0|16@1+ (1,0) [0|65535] ""  VIC,MGW
 SG_ EgoDistanceToRightLaneMarking : 112|7@1- (0.06,0) [-3.84|3.78] "m"  MGW
 SG_ CurvatureInformation : 120|8@1- (25,0) [-3200|3175] "m"  VIC,MGW
 SG_ TrafficSignSpeedLimit : 128|5@1+ (5,0) [0|150] "kph"  VIC,MGW
 SG_ SensorConeRearLeft : 140|2@1+ (1,0) [0|3] ""  VIC,MGW
 SG_ SensorConeRearRight : 142|2@1+ (1,0) [0|3] ""  VIC,MGW
 SG_ SensorConeFrontLeft : 136|2@1+ (1,0) [0|3] ""  VIC,MGW
 SG_ SensorConeFrontRight : 138|2@1+ (1,0) [0|3] ""  VIC,MGW
 SG_ SensorConeFrontCenter : 133|2@1+ (1,0) [0|3] ""  VIC,MGW
 SG_ NeighboringVehicle1VehicleType : 163|3@1+ (1,0) [0|7] ""  VIC,MGW
 SG_ NeighboringVehicle1X : 144|8@1+ (1.2,-50.4) [-50.4|255.6] "m"  VIC,MGW
 SG_ NeighboringVehicle1Y : 152|8@1- (0.06,0) [-7.68|7.62] "m"  VIC,MGW
 SG_ NeighboringVehicle1AugmentedData : 160|3@1+ (1,0) [0|7] ""  VIC,MGW
 SG_ NeighboringVehicle2VehicleType : 187|3@1+ (1,0) [0|7] ""  VIC,MGW
 SG_ NeighboringVehicle2X : 168|8@1+ (1.2,-50.4) [-50.4|255.6] "m"  VIC,MGW
 SG_ NeighboringVehicle2Y : 176|8@1- (0.06,0) [-7.68|7.62] "m"  VIC,MGW
 SG_ ADAS_4BA_AliveCounter : 16|8@1+ (1,0) [0|255] ""  VIC,MGW
 SG_ NeighboringVehicle2AugmentedData : 184|3@1+ (1,0) [0|7] ""  VIC,MGW
 SG_ NeighboringVehicle3VehicleType : 211|3@1+ (1,0) [0|7] ""  VIC,MGW
 SG_ NeighboringVehicle3X : 192|8@1+ (1.2,-50.4) [-50.4|255.6] "m"  VIC,MGW
 SG_ NeighboringVehicle3Y : 200|8@1- (0.06,0) [-7.68|7.62] "m"  VIC,MGW
 SG_ NeighboringVehicle3AugmentedData : 208|3@1+ (1,0) [0|7] ""  VIC,MGW
 SG_ NeighboringVehicle4VehicleType : 235|3@1+ (1,0) [0|7] ""  VIC,MGW
 SG_ NeighboringVehicle4X : 216|8@1+ (1.2,-50.4) [-50.4|255.6] "m"  VIC,MGW
 SG_ NeighboringVehicle4Y : 224|8@1- (0.06,0) [-7.68|7.62] "m"  VIC,MGW
 SG_ NeighboringVehicle4AugmentedData : 232|3@1+ (1,0) [0|7] ""  VIC,MGW
 SG_ NeighboringVehicle5VehicleType : 259|3@1+ (1,0) [0|7] ""  VIC,MGW
 SG_ NeighboringVehicle5X : 240|8@1+ (1.2,-50.4) [-50|250] "m"  VIC,MGW
 SG_ NeighboringVehicle5Y : 248|8@1- (0.06,0) [-7.68|7.62] "m"  VIC,MGW
 SG_ NeighboringVehicle5AugmentedData : 256|3@1+ (1,0) [0|7] ""  VIC,MGW
 SG_ NeighboringVehicle6VehicleType : 283|3@1+ (1,0) [0|7] ""  VIC,MGW
 SG_ NeighboringVehicle6X : 264|8@1+ (1.2,-50.4) [-50|250] "m"  VIC,MGW
 SG_ LedHadState : 24|4@1+ (1,0) [0|15] ""  VIC,MGW
 SG_ NeighboringVehicle6Y : 272|8@1- (0.06,0) [-7.68|7.62] "m"  VIC,MGW
 SG_ NeighboringVehicle6AugmentedData : 280|3@1+ (1,0) [0|7] ""  VIC,MGW
 SG_ NeighboringVehicle7VehicleType : 307|3@1+ (1,0) [0|7] ""  VIC,MGW
 SG_ NeighboringVehicle7X : 288|8@1+ (1.2,-50.4) [-50|250] "m"  VIC,MGW
 SG_ NeighboringVehicle7Y : 296|8@1- (0.06,0) [-7.68|7.62] "m"  VIC,MGW
 SG_ NeighboringVehicle7AugmentedData : 304|3@1+ (1,0) [0|7] ""  VIC,MGW
 SG_ NeighboringVehicle8VehicleType : 331|3@1+ (1,0) [0|7] ""  VIC,MGW
 SG_ HwaHfStatus : 28|3@1+ (1,0) [0|7] ""  VIC,MGW
 SG_ NeighboringVehicle8X : 312|8@1+ (1.2,-50.4) [-50.4|255.6] "m"  VIC,MGW
 SG_ NeighboringVehicle8Y : 320|8@1- (0.06,0) [-7.68|7.62] "m"  VIC,MGW
 SG_ NeighboringVehicle8AugmentedData : 328|3@1+ (1,0) [0|7] ""  VIC,MGW
 SG_ HwaHonStatus : 32|3@1+ (1,0) [0|7] ""  VIC,MGW
 SG_ HwaAccStatus : 35|3@1+ (1,0) [0|7] ""  VIC,MGW
 SG_ SetSpeed : 40|8@1+ (1,0) [0|255] "kph"  VIC,MGW
 SG_ SetSpeedColor : 48|3@1+ (1,0) [0|7] ""  VIC,MGW
 SG_ DisplayedEgoSpeed : 56|8@1+ (1,0) [0|255] "kph"  VIC,MGW
 SG_ DisplayedEgoSpeedColor : 64|3@1+ (1,0) [0|7] ""  VIC,MGW
 SG_ DisplayedLaneMarkingLeftType : 67|2@1+ (1,0) [0|3] ""  MGW
 SG_ DisplayedLaneMarkingLeftColor : 69|3@1+ (1,0) [0|7] ""  MGW
 SG_ DisplayedLaneMarkingRightType : 72|2@1+ (1,0) [0|3] ""  MGW
 SG_ DisplayedLaneMarkingRightColor : 74|3@1+ (1,0) [0|7] ""  MGW
 SG_ TimeGapSetValue : 77|3@1+ (1,0) [0|7] ""  VIC,MGW
 SG_ TimeGapColor : 80|3@1+ (1,0) [0|7] ""  VIC,MGW
 SG_ EgoLaneChange : 83|3@1+ (1,0) [0|7] ""  VIC,MGW
 SG_ DisplayedTextMessageId : 88|8@1+ (1,0) [0|255] ""  VIC,MGW
 SG_ PopupTextMessage : 86|2@1+ (1,0) [0|3] ""  VIC,MGW
 SG_ AudioNotificationId : 51|4@1+ (1,0) [0|15] ""  VIC,MGW
 SG_ AuxiliarySymbol : 96|6@1+ (1,0) [0|63] ""  VIC,MGW
 SG_ EgoLaneAssignment : 102|2@1+ (1,0) [0|3] ""  VIC,MGW
 SG_ EgoDistanceToLeftLaneMarking : 104|7@1- (0.06,0) [-3.84|3.78] "m"  MGW

BO_TX_BU_ 272 : HEP,MGW;
BO_TX_BU_ 261 : HEP,MGW;
BO_TX_BU_ 262 : HEP,MGW;
BO_TX_BU_ 260 : HEP,MGW;
BO_TX_BU_ 259 : HEP,MGW;
BO_TX_BU_ 258 : HEP,MGW;
BO_TX_BU_ 257 : HEP,MGW;
BO_TX_BU_ 1283 : HEP,MGW;
BO_TX_BU_ 1282 : HEP,MGW;

CM_ "dbc based on BJEV ADAS-CANFD (BJEV_N60AB(EP2)_ADASBUS_V2.2_ODS)";
CM_ BU_ HEP "HEP box: road informaiton for e.g. predictive ACC
only for Golf architecture, for Defender HEP is on EH-CAN over MGW";
CM_ BU_ IMU_MMP2 "Additional reference inertial sensor Bosch MMP2";
CM_ BU_ MAP "map data from MAP PC for HF";
CM_ BU_ DMS "Driver Monitoring Sensor
only for Golf architecture, for Defender DMS is on HMI-CANFD over MGW";
CM_ BU_ VIC "Visualization Computer
only for Golf architecture, for Defender VIC is on HMI-CANFD over MGW";
CM_ BU_ GWS "Gateway Safety (AEB)";
CM_ BU_ MGW "Mapping Gateway between vehicle and ADAS layer";
CM_ BU_ ADAS "DASy";
CM_ BU_ FVC "Front Video Camera - MPC3";
CM_ BU_ CR_RL "Corner Radar - Rear Left";
CM_ BU_ CR_RR "Corner Radar - Rear Right";
CM_ BU_ CR_FL "Corner Radar - Front Left";
CM_ BU_ CR_FR "Corner Radar - Front Right";
CM_ BU_ FR_FC "Front Radar - Front Center";
CM_ BU_ AVAP "Automated Parking - not used in OD";
CM_ SG_ 603 ADAS_Fwd_Safety_Func "ADAS_Fwd_Safety_Func";
CM_ BO_ 627 "Inertial sensor Bosch MMP2, additional reference
Rates 3 DOF";
CM_ BO_ 626 "Inertial sensor Bosch MMP2, additional reference
Accelerations 3 DOF";
CM_ SG_ 626 acc_z "vertical acceleration from MMP2";
CM_ SG_ 626 acc_y "lateral acceleration from MMP2";
CM_ SG_ 626 acc_x "longitudinal acceleration from MMP2";
CM_ BO_ 272 "Fully multiplexed long ADASIS horizon (values to be interpreted depending on MsgTyp)";
CM_ SG_ 272 ADASLONG_Mux_MsgTyp "Used for multiplexed ADASIS messages or for verification purposes. See value descriptions for details";
CM_ SG_ 261 ADAS_ProfLong_Retr "If true, this message was sent already at least once before";
CM_ SG_ 261 ADAS_ProfLong_PathIdx "Index of current path: If this number differs from one specified in previous PROFILE message, vehicle left the original path
Indices 0-7 have special meaning: see value descriptions for details";
CM_ SG_ 261 ADAS_ProfLong_Offset "Offset of position of the first profile spot from start position modulo 8191. Offset 8191 is invalid.";
CM_ SG_ 261 ADAS_ProfLong_MsgType "Used for multiplexed ADASIS messages or for verification purposes. See value descriptions for details";
CM_ SG_ 261 ADAS_ProfLong_CycCnt "Cyclic counter of this message type: reconstructor can use this value to detect missing messages";
CM_ SG_ 261 ADAS_ProfLong_CtrlPoint "If true, values in this message specifies additional control points required for certain interpolation types;
if false, actual profile values are specified";
CM_ SG_ 261 ProfileLong_Value "Profile value at Offset";
CM_ SG_ 261 ADAS_ProfLong_ProfType "Type of the Profile. See value descriptions for details";
CM_ SG_ 262 ADAS_Meta_ProtVer_MinorSub "Contains Sub-Minor protocol version";
CM_ SG_ 262 ADAS_Meta_CycCnt "Cyclic counter of this message type: reconstructor can use this value to detect missing messages";
CM_ SG_ 262 ADAS_Meta_MsgType "Used for multiplexed ADASIS messages or for verification purposes. See value descriptions for details";
CM_ SG_ 262 ADAS_Meta_MapVerQtr "Content of this field is Year quarter of release of map of current area.
For example, Q4/2007 map will be
MAP VERSION (Y) = 7
MAP VERSION (Q) = 3
Value of this field could vary between messages if map uses data with different release dates";
CM_ SG_ 262 ADAS_Meta_MapVerYear "Content of this field is Year of release of map of current area. For 2007, this field will contain value 7.
Value of this field could vary between messages if map uses data with different release dates";
CM_ SG_ 262 ADAS_Meta_MapProvider "Map Provider of current area (map tile, region, country, etc)";
CM_ SG_ 262 ADAS_Meta_HwVer "This field is ADAS Horizon Provider specific.";
CM_ SG_ 262 ADAS_Meta_ProtVer_Minor "Contains Minor protocol version;
For instance, for protocol version 0.15 Major Protocol Version will be 0 and Minor Protocol Version 15.";
CM_ SG_ 262 ADAS_Meta_ProtVer_Major "Contains Minor protocol version;
For instance, for protocol version 0.15 Major Protocol Version will be 0 and Minor Protocol Version 15.";
CM_ SG_ 262 ADAS_Meta_SpdUnits "Specifies whether miles or kilometers are used as units (speed limits, etc.)";
CM_ SG_ 262 ADAS_Meta_DrvSide "Specifies the driving side of the road";
CM_ SG_ 262 ADAS_Meta_RegionCode "For a given Country Code, specifies region of a country.
0 stands for unknown, all other values are system specific.";
CM_ SG_ 262 ADAS_Meta_CountryCode "ISO 3166-1 country code";
CM_ SG_ 260 ADAS_ProfShort_ProfType "Type of the Profile. See value descriptions for details";
CM_ SG_ 260 ADAS_ProfShort_Retr "If true, this message was sent already at least once before";
CM_ SG_ 260 ADAS_ProfShort_PathIdx "Index of current path: If this number differs from one specified in previous PROFILE message, vehicle left the original path
Indices 0-7 have special meaning: see value descriptions for details";
CM_ SG_ 260 ADAS_ProfShort_Offset "Offset of position of the first profile spot from start position modulo 8191. Offset 8191 is invalid.";
CM_ SG_ 260 ADAS_ProfShort_MsgType "Used for multiplexed ADASIS messages or for verification purposes. See value descriptions for details";
CM_ SG_ 260 ADAS_ProfShort_CycCnt "Cyclic counter of this message type: reconstructor can use this value to detect missing messages";
CM_ SG_ 260 ADAS_ProfShort_Value1 "Profile value at Offset+Distance1, if Distance1 > 0";
CM_ SG_ 260 ADAS_ProfShort_Dist1 "Distance from first profile spot to the second one.
If 0, no other profile values are defined in this message.";
CM_ SG_ 260 ADAS_ProfShort_Value0 "Profile value at Offset";
CM_ SG_ 260 ADAS_ProfShort_CtrlPoint "If true, values in this message specifies additional control points required for certain interpolation types;
if false, actual profile values are specified";
CM_ SG_ 259 ADAS_Stub_PartOfCalcRoute "Whether segment is part of calculated route";
CM_ SG_ 259 ADAS_Stub_FuncRoadClass "Functional class of the segment";
CM_ SG_ 259 ADAS_Stub_LastStub "Indicates that this STUB message is the last one that refers to given path and offset; if false more STUB messages for this offset will be sent.";
CM_ SG_ 259 ADAS_Stub_Update "Value true indicates that this message contains updated information of already transmitted STUB.";
CM_ SG_ 259 ADAS_Stub_SubPathIdx "This is Index of new path.";
CM_ SG_ 259 ADAS_Stub_Retr "If true, this message was sent already at least once before";
CM_ SG_ 259 ADAS_Stub_PathIdx "This is Index of parent path.";
CM_ SG_ 259 ADAS_Stub_Offset "Offset of position of the first profile spot from start position modulo 8191. Offset 8191 is invalid.";
CM_ SG_ 259 ADAS_Stub_NumOfLaneOppDir "Number of lanes in opposite direction. 0 denotes one-direction road, 1 for one lane only; 2 indicates 2 or more lanes.
Value 3 means unknown.";
CM_ SG_ 259 ADAS_Stub_NumOfLaneDrvDir "Number of lanes in driving direction: also implies driving direction. 0 denotes driving in wrong direction, 1-5 are verbatim values, and 6 indicate 6 or more lanes.
Value 7 means unknown.";
CM_ SG_ 259 ADAS_Stub_MsgType "Used for multiplexed ADASIS messages or for verification purposes. See value descriptions for details";
CM_ SG_ 259 ADAS_Stub_FormOfWay "Describes the form of way of the stub. See value descriptions for details";
CM_ SG_ 259 ADAS_Stub_CycCnt "Cyclic counter of this message type: reconstructor can use this value to detect missing messages";
CM_ SG_ 259 ADAS_Stub_RtOfWay "Whether this stub has the right of way. See value descriptions for details";
CM_ SG_ 259 ADAS_Stub_CmplxInsct "Describes whether stub is part of a complex intersection";
CM_ SG_ 259 ADAS_Stub_RelProbb "Relative probability of the path on the crossing: continuation of the path at an intersection can be calculated as 100 – sum (probability of all stubs)
Value 0 indicates that turn is not allowed.
Value 30 is not allowed.
Value 31 means unknown";
CM_ SG_ 259 ADAS_Stub_TurnAngl "Turn angle of the stub
0 = straight
90 = right turn
180 = U-turn
270 = left turn
etc";
CM_ SG_ 258 ADAS_Seg_PartOfCalcRoute "Whether segment is part of calculated route";
CM_ SG_ 258 ADAS_Seg_RelProbb "Relative probability of the path on the crossing: continuation of the path at an intersection can be calculated as 100 – sum (probability of all stubs)
Value 0 indicates that turn is not allowed.
Value 30 is not allowed.
Value 31 means unknown";
CM_ SG_ 258 ADAS_Seg_Offset "Offset of position of the first profile spot from start position modulo 8191. Offset 8191 is invalid.";
CM_ SG_ 258 ADAS_Seg_Retr "If true, this message was sent already at least once before";
CM_ SG_ 258 ADAS_Seg_PathIdx "Index of current path: If this number differs from one specified in previous SEGMENT message, vehicle left the original path
Indices 0-7 have special meaning: see value descriptions for details";
CM_ SG_ 258 ADAS_Seg_MsgType "Used for multiplexed ADASIS messages or for verification purposes. See value descriptions for details";
CM_ SG_ 258 ADAS_Seg_FormOfWay "Describes the form of way of the segment. See value descriptions for details";
CM_ SG_ 258 ADAS_Seg_CycCnt "Cyclic counter of this message type: reconstructor can use this value to detect missing messages";
CM_ SG_ 258 ADAS_Seg_CmplxInsct "Whether segment is part of a complex intersection";
CM_ SG_ 258 ADAS_Seg_BuildUpArea "Whether segment is part of a build-up area (driving in city)";
CM_ SG_ 258 ADAS_Seg_DividedRoad "Whether segment is part of a divided road";
CM_ SG_ 258 ADAS_Seg_Bridge "Whether segment is part of a bridge";
CM_ SG_ 258 ADAS_Seg_Tunnel "Whether segment is part of a tunnel";
CM_ SG_ 258 ADAS_Seg_NumOfLaneOppDir "Number of lanes in opposite direction. 0 denotes one-direction road, 1 for one lane only; 2 indicates 2 or more lanes.
Value 3 means unknown.";
CM_ SG_ 258 ADAS_Seg_NumOfLaneDrvDir "Number of lanes in driving direction: also implies driving direction. 0 denotes driving in wrong direction, 1-5 are verbatim values, and 6 indicate 6 or more lanes.
Value 7 means unknown.";
CM_ SG_ 258 ADAS_Seg_EffSpdLmtType "Describes what kind of Speed Limit is in effect. See value descriptions for details";
CM_ SG_ 258 ADAS_Seg_EffSpdLmt "Current Speed Limit: May be implicit (for instance, in cities), or explicit.
Current time of day, day of week and weather conditions are taken in account by Horizon Provider in determining effective speed limit.";
CM_ SG_ 258 ADAS_Seg_FuncRoadClass "Functional class of the segment";
CM_ SG_ 258 ADAS_Seg_Update "Value true indicates that this message contains updated information of already transmitted SEGMENT";
CM_ SG_ 257 ADAS_Posn_PosProbb "Probability of this position candidate";
CM_ SG_ 257 ADAS_Posn_PosConfdc "Position confidence: this field contain Av2HP implementation specific values. Use 0 for highest confidence, 6 for lowest confidence, 7 means SNA.";
CM_ SG_ 257 ADAS_Posn_CurLane "Current lane; for details, see value descriptions for current Lane values";
CM_ SG_ 257 ADAS_Posn_Spd "Speed of the vehicle projected to the path";
CM_ SG_ 257 ADAS_Posn_RelHead "Heading relative to path:
0 in path direction
1 .. 126: right from path direction
253 .. 128: left from link direction
127 in opposite direction
253 unknown";
CM_ SG_ 257 ADAS_Posn_Idx "If Av2HP supports positioning alternatives, contains index of this Position Candidate. Candidate 0 is always most probable position candidate,
candidate 1 second etc. If Av2HP does not support positioning alternatives, it will be always 0.";
CM_ SG_ 257 ADAS_Posn_Age "Time difference between the moment the message is sent and the moment the vehicle position is calculated by the positioning sub-system.  510 means older than 2545 ms, 511 means invalid.";
CM_ SG_ 257 ADAS_Posn_PathIdx "Index of current path: If this number differs from one specified in previous POSITION message, vehicle left the original path
Indices 0-7 have special meaning: see value descriptions for details";
CM_ SG_ 257 ADAS_Posn_Offset "Offset of current position from the current path's start point modulo 8191. Offset 8191 is invalid.";
CM_ SG_ 257 ADAS_Posn_MsgTyp "Used for multiplexed ADASIS messages or for verification purposes. See value descriptions for details";
CM_ SG_ 257 ADAS_Posn_CycCnt "Cyclic counter of this message type: reconstructor can use this value to detect missing messages";
CM_ BO_ 443 "AFB: Actuator Feedback";
CM_ SG_ 443 AFB_1BB_AliveCounter "AliveCounter AFB_1BB
overtaken from VCU_1BA_AliveCounter";
CM_ SG_ 443 AFB_1BB_CheckSum "CheckSum AFB_1BB
overtaken from VCU_1BA_CheckSum";
CM_ BO_ 601 "TBD if still in usage
Used to be send by Front Radar for the AEB feature (hosted on FR for BJEV).";
CM_ SG_ 601 ADAS_Req_Prefill "Prefill??";
CM_ SG_ 601 ADAS_Req_HBA "HBA??";
CM_ SG_ 601 ADAS_Req_AWB "AWB??";
CM_ SG_ 601 ADAS_Lvl_HBA "HBA??";
CM_ SG_ 601 ADAS_Lvl_AWB "AWB??";
CM_ SG_ 601 ADAS_DecelTyp_AEB "AEB?????";
CM_ SG_ 601 ADAS_Decel_AEB "AEB???";
CM_ SG_ 601 ADAS_259_CheckSum "CheckSum ADAS_259";
CM_ SG_ 601 ADAS_259_AliveCounter "AliveCounter ADAS_259";
CM_ SG_ 716 HODTchZone1Val_h8HSC8 "Hod Touch Zone 1 Value";
CM_ BO_ 449 "Lateral actuation request DASy to Steering";
CM_ SG_ 449 DADCSteerTqReqActive "DADC request flag for Hands-on/Hands-Free steering torque control to be enabled";
CM_ SG_ 449 ADAS_1C1_CheckSum "CheckSum ADAS_1C1";
CM_ SG_ 449 ADAS_RdWhlAgReqActive "DASy request flag for road wheel angle control to be enabled
(expected calibration setting from the Lateral Motion Controller)";
CM_ SG_ 449 ADAS_1C1_AliveCounter "AliveCounter ADAS_1C1 - AUTOSAR E2E Profile 1";
CM_ SG_ 449 ADAS_RdWhlAgReq "DASy send road wheel angle request to EPS";
CM_ SG_ 449 ADAS_ExtMaxRPCTrq "Maximum externally allowed RPC torque for Level 2 (TBT Level)";
CM_ SG_ 449 ADAS_ExtMinRPCTrq "Minimum externally allowed RPC torque for Level 2 (TBT Level)";
CM_ SG_ 1216 GF_map_position_accuracy "Standard deviation of the offset";
CM_ SG_ 1216 GF_map_position_deviation "Distance between map matched position and estimated position";
CM_ SG_ 1216 GF_CRC "CRC - Autosar E2E Profile 5";
CM_ SG_ 1216 GF_AliveCtr "Alive counter - Autosar E2E Profile 5";
CM_ SG_ 1216 GF_Currentlane_Index "Position-->currentlaneindex";
CM_ SG_ 1216 GF_NumberOfLanes "Position-->NumberOfLanePerDirection in current path";
CM_ SG_ 1216 GF_Region_outOfODD_offset "Offset to the nearest  upcoming out of ODD  region for the current path";
CM_ SG_ 1216 GF_Country_outOfODD_offset "Offset to the nearest  upcoming out of ODD  country for the current path";
CM_ SG_ 1216 GF_LaneTrans_outOfODD_offset "Offset to the nearest  upcoming out of ODD  lane transition for the current path";
CM_ SG_ 1216 GF_Curvature_outOfODD_offset "Offset to point in the lane at which the curve radius is below minViableRoadRadius";
CM_ SG_ 1216 GF_LaneType_outOfODD_offset "Offset to the nearest  upcoming  out of ODD lane type of the current path";
CM_ SG_ 1216 GF_RoadSlope_outOfODD_offset "Offset to point in the road at which the road slope is below minRoadSlope or above maxRoadSlope.";
CM_ SG_ 1216 GF_LaneWidth_outOfODD_offset "Offset to point in the lane at which the lane width is below the minLaneWidth threshold";
CM_ SG_ 1216 GF_FormOfWay_outOfODD_offset "Offset to the nearest  upcoming  out of ODD  form of way (road class) for the current path";
CM_ SG_ 1216 GF_MapExpired "True if the map data is older than maxMapAge. False otherwise.";
CM_ SG_ 1216 GF_BlackListedSegment_offset "Offset to the nearest  upcoming out black listed segment for the current path";
CM_ SG_ 1216 GF_Intersection_offset "Offset to the nearest  upcoming intersection for the current path";
CM_ SG_ 1216 GF_SideWind_offset "Offset to the nearest  upcoming side wind sign  for the current path";
CM_ SG_ 1216 GF_ActiveSpeedLimit "Current speed limit";
CM_ SG_ 1216 GF_TollGate_offset "Offset to the nearest  upcoming tollgate  for the current path";
CM_ SG_ 1216 GF_TrafficLight_offset "Offset to the nearest  upcoming traffic light  for the current path";
CM_ SG_ 1216 GF_Tunnel_Offset "Offset to the nearest  upcoming tunnel for the current path";
CM_ SG_ 1216 GF_MapStatus "This enumeration defines values for the Map Status. These values are not mutually exclusive and they are intended to be used as a bitmask obtained by an OR of all values.";
CM_ SG_ 1217 Cv_CRC "CRC - Autosar E2E Profile 5";
CM_ SG_ 1217 Cv_AliveCtr "Alive counter - Autosar E2E Profile 5";
CM_ SG_ 1217 Cv_Value_Seg00 "Absolute value of curvature at the segment";
CM_ SG_ 1217 Cv_Value_Seg01 "Absolute value of curvature at the segment";
CM_ SG_ 1217 Cv_Value_Seg02 "Absolute value of curvature at the segment";
CM_ SG_ 1217 Cv_Value_Seg03 "Absolute value of curvature at the segment";
CM_ SG_ 1217 Cv_Value_Seg04 "Absolute value of curvature at the segment";
CM_ SG_ 1217 Cv_Value_Seg05 "Absolute value of curvature at the segment";
CM_ SG_ 1217 Cv_Value_Seg06 "Absolute value of curvature at the segment";
CM_ SG_ 1217 Cv_Value_Seg07 "Absolute value of curvature at the segment";
CM_ SG_ 1217 Cv_Value_Seg08 "Absolute value of curvature at the segment";
CM_ SG_ 1217 Cv_Value_Seg09 "Absolute value of curvature at the segment";
CM_ SG_ 1217 Cv_Value_Seg10 "Absolute value of curvature at the segment";
CM_ SG_ 1217 Cv_Value_Seg11 "Absolute value of curvature at the segment";
CM_ SG_ 1217 Cv_Value_Seg12 "Absolute value of curvature at the segment";
CM_ SG_ 1217 Cv_Value_Seg13 "Absolute value of curvature at the segment";
CM_ SG_ 1217 Cv_Value_Seg14 "Absolute value of curvature at the segment";
CM_ SG_ 1217 Cv_Value_Seg15 "Absolute value of curvature at the segment";
CM_ SG_ 1217 Cv_Value_Seg16 "Absolute value of curvature at the segment";
CM_ SG_ 1217 Cv_Value_Seg17 "Absolute value of curvature at the segment";
CM_ SG_ 1217 Cv_Value_Seg18 "Absolute value of curvature at the segment";
CM_ SG_ 1217 Cv_Value_Seg19 "Absolute value of curvature at the segment";
CM_ SG_ 1217 Cv_Offset_Seg00 "Offset of the curvature value at the segment";
CM_ SG_ 1217 Cv_Offset_Seg01 "Offset of the curvature value at the segment";
CM_ SG_ 1217 Cv_Offset_Seg02 "Offset of the curvature value at the segment";
CM_ SG_ 1217 Cv_Offset_Seg03 "Offset of the curvature value at the segment";
CM_ SG_ 1217 Cv_Offset_Seg04 "Offset of the curvature value at the segment";
CM_ SG_ 1217 Cv_Offset_Seg05 "Offset of the curvature value at the segment";
CM_ SG_ 1217 Cv_Offset_Seg06 "Offset of the curvature value at the segment";
CM_ SG_ 1217 Cv_Offset_Seg07 "Offset of the curvature value at the segment";
CM_ SG_ 1217 Cv_Offset_Seg08 "Offset of the curvature value at the segment";
CM_ SG_ 1217 Cv_Offset_Seg09 "Offset of the curvature value at the segment";
CM_ SG_ 1217 Cv_Offset_Seg10 "Offset of the curvature value at the segment";
CM_ SG_ 1217 Cv_Offset_Seg11 "Offset of the curvature value at the segment";
CM_ SG_ 1217 Cv_Offset_Seg12 "Offset of the curvature value at the segment";
CM_ SG_ 1217 Cv_Offset_Seg13 "Offset of the curvature value at the segment";
CM_ SG_ 1217 Cv_Offset_Seg14 "Offset of the curvature value at the segment";
CM_ SG_ 1217 Cv_Offset_Seg15 "Offset of the curvature value at the segment";
CM_ SG_ 1217 Cv_Offset_Seg16 "Offset of the curvature value at the segment";
CM_ SG_ 1217 Cv_Offset_Seg17 "Offset of the curvature value at the segment";
CM_ SG_ 1217 Cv_Offset_Seg18 "Offset of the curvature value at the segment";
CM_ SG_ 1217 Cv_Offset_Seg19 "Offset of the curvature value at the segment";
CM_ BO_ 1220 "central line from 0 to  -20m";
CM_ SG_ 1218 centerline_1_CRC "CRC - Autosar E2E Profile 5";
CM_ SG_ 1218 centerline_1_AliveCtr "Alive counter - Autosar E2E Profile 5";
CM_ SG_ 1218 CenterPoint_dx_00 "Longitudinal distance to the center line point. Invalid if CenterPoint_dx_XX = 0.0 AND CenterPoint_dy_XX = -102.4";
CM_ SG_ 1218 CenterPoint_dy_00 "Lateral distance to the center line point. Invalid if CenterPoint_dx_XX = 0.0 AND CenterPoint_dy_XX = -102.4";
CM_ SG_ 1218 CenterPoint_dx_01 "Longitudinal distance to the center line point. Invalid if CenterPoint_dx_XX = 0.0 AND CenterPoint_dy_XX = -102.4";
CM_ SG_ 1218 CenterPoint_dy_01 "Lateral distance to the center line point. Invalid if CenterPoint_dx_XX = 0.0 AND CenterPoint_dy_XX = -102.4";
CM_ SG_ 1218 CenterPoint_dx_02 "Longitudinal distance to the center line point. Invalid if CenterPoint_dx_XX = 0.0 AND CenterPoint_dy_XX = -102.4";
CM_ SG_ 1218 CenterPoint_dy_02 "Lateral distance to the center line point. Invalid if CenterPoint_dx_XX = 0.0 AND CenterPoint_dy_XX = -102.4";
CM_ SG_ 1218 CenterPoint_dx_03 "Longitudinal distance to the center line point. Invalid if CenterPoint_dx_XX = 0.0 AND CenterPoint_dy_XX = -102.4";
CM_ SG_ 1218 CenterPoint_dy_03 "Lateral distance to the center line point. Invalid if CenterPoint_dx_XX = 0.0 AND CenterPoint_dy_XX = -102.4";
CM_ SG_ 1218 CenterPoint_dx_04 "Longitudinal distance to the center line point. Invalid if CenterPoint_dx_XX = 0.0 AND CenterPoint_dy_XX = -102.4";
CM_ SG_ 1218 CenterPoint_dy_04 "Lateral distance to the center line point. Invalid if CenterPoint_dx_XX = 0.0 AND CenterPoint_dy_XX = -102.4";
CM_ SG_ 1218 CenterPoint_dx_05 "Longitudinal distance to the center line point. Invalid if CenterPoint_dx_XX = 0.0 AND CenterPoint_dy_XX = -102.4";
CM_ SG_ 1218 CenterPoint_dy_05 "Lateral distance to the center line point. Invalid if CenterPoint_dx_XX = 0.0 AND CenterPoint_dy_XX = -102.4";
CM_ SG_ 1218 CenterPoint_dx_06 "Longitudinal distance to the center line point. Invalid if CenterPoint_dx_XX = 0.0 AND CenterPoint_dy_XX = -102.4";
CM_ SG_ 1218 CenterPoint_dy_06 "Lateral distance to the center line point. Invalid if CenterPoint_dx_XX = 0.0 AND CenterPoint_dy_XX = -102.4";
CM_ SG_ 1218 CenterPoint_dx_07 "Longitudinal distance to the center line point. Invalid if CenterPoint_dx_XX = 0.0 AND CenterPoint_dy_XX = -102.4";
CM_ SG_ 1218 CenterPoint_dy_07 "Lateral distance to the center line point. Invalid if CenterPoint_dx_XX = 0.0 AND CenterPoint_dy_XX = -102.4";
CM_ SG_ 1218 CenterPoint_dx_08 "Longitudinal distance to the center line point. Invalid if CenterPoint_dx_XX = 0.0 AND CenterPoint_dy_XX = -102.4";
CM_ SG_ 1218 CenterPoint_dy_08 "Lateral distance to the center line point. Invalid if CenterPoint_dx_XX = 0.0 AND CenterPoint_dy_XX = -102.4";
CM_ SG_ 1218 CenterPoint_dx_09 "Longitudinal distance to the center line point. Invalid if CenterPoint_dx_XX = 0.0 AND CenterPoint_dy_XX = -102.4";
CM_ SG_ 1218 CenterPoint_dy_09 "Lateral distance to the center line point. Invalid if CenterPoint_dx_XX = 0.0 AND CenterPoint_dy_XX = -102.4";
CM_ SG_ 1218 CenterPoint_dx_10 "Longitudinal distance to the center line point. Invalid if CenterPoint_dx_XX = 0.0 AND CenterPoint_dy_XX = -102.4";
CM_ SG_ 1218 CenterPoint_dy_10 "Lateral distance to the center line point. Invalid if CenterPoint_dx_XX = 0.0 AND CenterPoint_dy_XX = -102.4";
CM_ SG_ 1218 CenterPoint_dx_11 "Longitudinal distance to the center line point. Invalid if CenterPoint_dx_XX = 0.0 AND CenterPoint_dy_XX = -102.4";
CM_ SG_ 1218 CenterPoint_dy_11 "Lateral distance to the center line point. Invalid if CenterPoint_dx_XX = 0.0 AND CenterPoint_dy_XX = -102.4";
CM_ SG_ 1218 CenterPoint_dx_12 "Longitudinal distance to the center line point. Invalid if CenterPoint_dx_XX = 0.0 AND CenterPoint_dy_XX = -102.4";
CM_ SG_ 1218 CenterPoint_dy_12 "Lateral distance to the center line point. Invalid if CenterPoint_dx_XX = 0.0 AND CenterPoint_dy_XX = -102.4";
CM_ SG_ 1218 CenterPoint_dx_13 "Longitudinal distance to the center line point. Invalid if CenterPoint_dx_XX = 0.0 AND CenterPoint_dy_XX = -102.4";
CM_ SG_ 1218 CenterPoint_dy_13 "Lateral distance to the center line point. Invalid if CenterPoint_dx_XX = 0.0 AND CenterPoint_dy_XX = -102.4";
CM_ SG_ 1218 CenterPoint_dx_14 "Longitudinal distance to the center line point. Invalid if CenterPoint_dx_XX = 0.0 AND CenterPoint_dy_XX = -102.4";
CM_ SG_ 1218 CenterPoint_dy_14 "Lateral distance to the center line point. Invalid if CenterPoint_dx_XX = 0.0 AND CenterPoint_dy_XX = -102.4";
CM_ SG_ 1218 CenterPoint_dx_15 "Longitudinal distance to the center line point. Invalid if CenterPoint_dx_XX = 0.0 AND CenterPoint_dy_XX = -102.4";
CM_ SG_ 1218 CenterPoint_dy_15 "Lateral distance to the center line point. Invalid if CenterPoint_dx_XX = 0.0 AND CenterPoint_dy_XX = -102.4";
CM_ SG_ 1218 CenterPoint_dx_16 "Longitudinal distance to the center line point. Invalid if CenterPoint_dx_XX = 0.0 AND CenterPoint_dy_XX = -102.4";
CM_ SG_ 1218 CenterPoint_dy_16 "Lateral distance to the center line point. Invalid if CenterPoint_dx_XX = 0.0 AND CenterPoint_dy_XX = -102.4";
CM_ SG_ 1218 CenterPoint_dx_17 "Longitudinal distance to the center line point. Invalid if CenterPoint_dx_XX = 0.0 AND CenterPoint_dy_XX = -102.4";
CM_ SG_ 1218 CenterPoint_dy_17 "Lateral distance to the center line point. Invalid if CenterPoint_dx_XX = 0.0 AND CenterPoint_dy_XX = -102.4";
CM_ SG_ 1218 CenterPoint_dx_18 "Longitudinal distance to the center line point. Invalid if CenterPoint_dx_XX = 0.0 AND CenterPoint_dy_XX = -102.4";
CM_ SG_ 1218 CenterPoint_dy_18 "Lateral distance to the center line point. Invalid if CenterPoint_dx_XX = 0.0 AND CenterPoint_dy_XX = -102.4";
CM_ SG_ 1218 CenterPoint_dx_19 "Longitudinal distance to the center line point. Invalid if CenterPoint_dx_XX = 0.0 AND CenterPoint_dy_XX = -102.4";
CM_ SG_ 1218 CenterPoint_dy_19 "Lateral distance to the center line point. Invalid if CenterPoint_dx_XX = 0.0 AND CenterPoint_dy_XX = -102.4";
CM_ SG_ 1219 CenterPoint_dx_20 "Longitudinal distance to the center line point. Invalid if CenterPoint_dx_XX = 0.0 AND CenterPoint_dy_XX = -102.4";
CM_ SG_ 1219 CenterPoint_dy_20 "Lateral distance to the center line point. Invalid if CenterPoint_dx_XX = 0.0 AND CenterPoint_dy_XX = -102.4";
CM_ SG_ 1219 CenterPoint_dx_21 "Longitudinal distance to the center line point. Invalid if CenterPoint_dx_XX = 0.0 AND CenterPoint_dy_XX = -102.4";
CM_ SG_ 1219 CenterPoint_dy_21 "Lateral distance to the center line point. Invalid if CenterPoint_dx_XX = 0.0 AND CenterPoint_dy_XX = -102.4";
CM_ SG_ 1219 CenterPoint_dx_22 "Longitudinal distance to the center line point. Invalid if CenterPoint_dx_XX = 0.0 AND CenterPoint_dy_XX = -102.4";
CM_ SG_ 1219 CenterPoint_dy_22 "Lateral distance to the center line point. Invalid if CenterPoint_dx_XX = 0.0 AND CenterPoint_dy_XX = -102.4";
CM_ SG_ 1219 CenterPoint_dx_23 "Longitudinal distance to the center line point. Invalid if CenterPoint_dx_XX = 0.0 AND CenterPoint_dy_XX = -102.4";
CM_ SG_ 1219 CenterPoint_dy_23 "Lateral distance to the center line point. Invalid if CenterPoint_dx_XX = 0.0 AND CenterPoint_dy_XX = -102.4";
CM_ SG_ 1219 CenterPoint_dx_24 "Longitudinal distance to the center line point. Invalid if CenterPoint_dx_XX = 0.0 AND CenterPoint_dy_XX = -102.4";
CM_ SG_ 1219 CenterPoint_dy_24 "Lateral distance to the center line point. Invalid if CenterPoint_dx_XX = 0.0 AND CenterPoint_dy_XX = -102.4";
CM_ SG_ 1219 CenterPoint_dx_25 "Longitudinal distance to the center line point. Invalid if CenterPoint_dx_XX = 0.0 AND CenterPoint_dy_XX = -102.4";
CM_ SG_ 1219 CenterPoint_dy_25 "Lateral distance to the center line point. Invalid if CenterPoint_dx_XX = 0.0 AND CenterPoint_dy_XX = -102.4";
CM_ SG_ 1219 CenterPoint_dx_26 "Longitudinal distance to the center line point. Invalid if CenterPoint_dx_XX = 0.0 AND CenterPoint_dy_XX = -102.4";
CM_ SG_ 1219 CenterPoint_dy_26 "Lateral distance to the center line point. Invalid if CenterPoint_dx_XX = 0.0 AND CenterPoint_dy_XX = -102.4";
CM_ SG_ 1219 CenterPoint_dx_27 "Longitudinal distance to the center line point. Invalid if CenterPoint_dx_XX = 0.0 AND CenterPoint_dy_XX = -102.4";
CM_ SG_ 1219 CenterPoint_dy_27 "Lateral distance to the center line point. Invalid if CenterPoint_dx_XX = 0.0 AND CenterPoint_dy_XX = -102.4";
CM_ SG_ 1219 CenterPoint_dx_28 "Longitudinal distance to the center line point. Invalid if CenterPoint_dx_XX = 0.0 AND CenterPoint_dy_XX = -102.4";
CM_ SG_ 1219 CenterPoint_dy_28 "Lateral distance to the center line point. Invalid if CenterPoint_dx_XX = 0.0 AND CenterPoint_dy_XX = -102.4";
CM_ SG_ 1219 CenterPoint_dx_29 "Longitudinal distance to the center line point. Invalid if CenterPoint_dx_XX = 0.0 AND CenterPoint_dy_XX = -102.4";
CM_ SG_ 1219 CenterPoint_dy_29 "Lateral distance to the center line point. Invalid if CenterPoint_dx_XX = 0.0 AND CenterPoint_dy_XX = -102.4";
CM_ SG_ 1219 CenterPoint_dx_30 "Longitudinal distance to the center line point. Invalid if CenterPoint_dx_XX = 0.0 AND CenterPoint_dy_XX = -102.4";
CM_ SG_ 1219 CenterPoint_dy_30 "Lateral distance to the center line point. Invalid if CenterPoint_dx_XX = 0.0 AND CenterPoint_dy_XX = -102.4";
CM_ SG_ 1219 CenterPoint_dx_31 "Longitudinal distance to the center line point. Invalid if CenterPoint_dx_XX = 0.0 AND CenterPoint_dy_XX = -102.4";
CM_ SG_ 1219 CenterPoint_dy_31 "Lateral distance to the center line point. Invalid if CenterPoint_dx_XX = 0.0 AND CenterPoint_dy_XX = -102.4";
CM_ SG_ 1219 CenterPoint_dx_32 "Longitudinal distance to the center line point. Invalid if CenterPoint_dx_XX = 0.0 AND CenterPoint_dy_XX = -102.4";
CM_ SG_ 1219 CenterPoint_dy_32 "Lateral distance to the center line point. Invalid if CenterPoint_dx_XX = 0.0 AND CenterPoint_dy_XX = -102.4";
CM_ SG_ 1219 CenterPoint_dx_33 "Longitudinal distance to the center line point. Invalid if CenterPoint_dx_XX = 0.0 AND CenterPoint_dy_XX = -102.4";
CM_ SG_ 1219 CenterPoint_dy_33 "Lateral distance to the center line point. Invalid if CenterPoint_dx_XX = 0.0 AND CenterPoint_dy_XX = -102.4";
CM_ SG_ 1219 CenterPoint_dx_34 "Longitudinal distance to the center line point. Invalid if CenterPoint_dx_XX = 0.0 AND CenterPoint_dy_XX = -102.4";
CM_ SG_ 1219 CenterPoint_dy_34 "Lateral distance to the center line point. Invalid if CenterPoint_dx_XX = 0.0 AND CenterPoint_dy_XX = -102.4";
CM_ SG_ 1219 centerline_LaneWidth "current lane width";
CM_ SG_ 1219 localization_lat_StdDev "Localizer standard deviation lateral wrt ego vehicle coordinates";
CM_ SG_ 1219 localization_long_StdDev "Localizer standard deviation longitudinal wrt ego vehicle coordinates";
CM_ SG_ 1219 localization_heading_StdDev "Localizer standard deviation in heading";
CM_ SG_ 1219 map_position_deviation "Distance between map matched position and estimated position";
CM_ SG_ 1219 map_position_accuracy "Standard deviation of the offset";
CM_ SG_ 1219 Timestamp "Map data timestamp for synchronization";
CM_ BO_ 1221 "central line with high resolution up to 0.001m";
CM_ SG_ 1226 ReferenceLine1_CRC "CRC - Autosar E2E Profile 5";
CM_ SG_ 1226 ReferenceLine1_AliveCtr "Alive counter - Autosar E2E Profile 5";
CM_ SG_ 1226 ReferenceLine1_TimeStamp "Map data timestamp for synchronization";
CM_ SG_ 1226 ReferenceLine_point_N "Number of valid elements in the reference line";
CM_ SG_ 1226 ReferenceLine_dx_00 "Longitudinal distance to the reference line point";
CM_ SG_ 1226 ReferenceLine_dy_00 "Lateral distance to the reference line point";
CM_ SG_ 1227 ReferenceLine2_CRC "CRC - Autosar E2E Profile 5";
CM_ SG_ 1227 ReferenceLine2_AliveCtr "Alive counter - Autosar E2E Profile 5";
CM_ SG_ 1227 ReferenceLine2_TimeStamp "Map data timestamp for synchronization";
CM_ SG_ 1227 ReferenceLine_dx_20 "Longitudinal distance to the reference line point";
CM_ SG_ 1227 ReferenceLine_dy_20 "Lateral distance to the reference line point";
CM_ SG_ 1228 Ego_Lane_Info1_CRC "CRC - Autosar E2E Profile 5";
CM_ SG_ 1228 Ego_Lane_Info1_AliveCtr "Alive counter - Autosar E2E Profile 5";
CM_ SG_ 1228 Ego_Lane_Info1_TimeStamp "Map data timestamp for synchronization";
CM_ SG_ 1228 Ego_Lane_Map_Status "Validity of RSD map";
CM_ SG_ 1228 Ego_Lane_CurrentSpeedLimit "Current speed limit on the Ego Lane
159 indicates an unknown speed";
CM_ SG_ 1228 Ego_Lane_CurrentSpeedLimit_Type "type of the speed limit";
CM_ SG_ 1228 Ego_Lane_NextSpeedLimit_Value_1 "Next speed limit on ego lane";
CM_ SG_ 1228 Ego_Lane_NextSpeedLimit_Loc_1 "Next speed limit location on ego lane";
CM_ SG_ 1228 Ego_Lane_NextTopoLocation_1 "Next location of topology change";
CM_ SG_ 1228 Ego_Lane_NextTopoType_1 "Next type of topology change";
CM_ SG_ 1228 Ego_Lane_NextTopoSide_1 "Side of the next topology change";
CM_ SG_ 1228 Ego_Lane_NextTopoSide_2 "Side of the next topology change";
CM_ SG_ 1228 Ego_Lane_NextTopoSide_3 "Side of the next topology change";
CM_ SG_ 1228 Ego_Lane_NextTopoSide_4 "Side of the next topology change";
CM_ SG_ 1228 Ego_Lane_CurrBoundary_Type_R "Type of the boundary";
CM_ SG_ 1228 Ego_Lane_NextBoundary_Loc_R_1 "location of the next lane boundary change";
CM_ SG_ 1228 Ego_Lane_NextBoundary_Type_R_1 "Type of the boundary";
CM_ SG_ 1228 Ego_Lane_NextBoundary_Loc_R_2 "location of the next lane boundary change";
CM_ SG_ 1228 Ego_Lane_NextBoundary_Type_R_2 "Type of the boundary";
CM_ SG_ 1228 Ego_Lane_NextBoundary_Loc_R_3 "location of the next lane boundary change";
CM_ SG_ 1228 Ego_Lane_NextBoundary_Type_R_3 "Type of the boundary";
CM_ SG_ 1228 Ego_Lane_NextBoundary_Loc_R_4 "location of the next lane boundary change";
CM_ SG_ 1228 Ego_Lane_NextBoundary_Type_R_4 "Type of the boundary";
CM_ SG_ 1228 Ego_Lane_CurrBoundary_Type_L "Type of the boundary";
CM_ SG_ 1228 Ego_Lane_NextBoundary_Loc_L_1 "location of the next lane boundary change";
CM_ SG_ 1228 Ego_Lane_NextBoundary_Type_L_1 "Type of the boundary";
CM_ SG_ 1228 Ego_Lane_NextBoundary_Loc_L_2 "location of the next lane boundary change";
CM_ SG_ 1228 Ego_Lane_NextBoundary_Type_L_2 "Type of the boundary";
CM_ SG_ 1228 Ego_Lane_NextBoundary_Loc_L_3 "location of the next lane boundary change";
CM_ SG_ 1228 Ego_Lane_NextBoundary_Type_L_3 "Type of the boundary";
CM_ SG_ 1228 Ego_Lane_NextBoundary_Loc_L_4 "location of the next lane boundary change";
CM_ SG_ 1228 Ego_Lane_NextBoundary_Type_L_4 "Type of the boundary";
CM_ SG_ 1229 Ego_Lane_Info2_CRC "CRC - Autosar E2E Profile 5";
CM_ SG_ 1229 Ego_Lane_Info2_AliveCtr "Alive counter - Autosar E2E Profile 5";
CM_ SG_ 1229 Ego_Lane_Info2_TimeStamp "Map data timestamp for synchronization";
CM_ SG_ 1229 Ego_Lane_SpeedProfile_Near_N "Number of valid elements in speed profile";
CM_ SG_ 1229 Ego_Lane_SpeedProfile_Near_00 "Speed Profile from vehicle crowd";
CM_ SG_ 1229 Ego_Lane_SpeedProfile_Far_N "Number of valid elements in speed profile";
CM_ SG_ 1229 Ego_Lane_NextHotspot_Int_1 "intensity of the hotspot";
CM_ SG_ 1229 Ego_Lane_NextHotspot_Prob_1 "probability of the hotspot";
CM_ SG_ 1229 Ego_Lane_NextHotspot_Side_1 "Side of the lane change";
CM_ SG_ 1229 Ego_Lane_NextHotspot_Int_2 "intensity of the hotspot";
CM_ SG_ 1229 Ego_Lane_NextHotspot_Prob_2 "probability of the hotspot";
CM_ SG_ 1229 Ego_Lane_NextHotspot_Side_2 "Side of the lane change";
CM_ SG_ 1229 Ego_Lane_NextHotspot_Int_3 "intensity of the hotspot";
CM_ SG_ 1229 Ego_Lane_NextHotspot_Prob_3 "probability of the hotspot";
CM_ SG_ 1229 Ego_Lane_NextHotspot_Side_3 "Side of the lane change";
CM_ SG_ 1229 Ego_Lane_NextHotspot_Int_4 "intensity of the hotspot";
CM_ SG_ 1229 Ego_Lane_NextHotspot_Prob_4 "probability of the hotspot";
CM_ SG_ 1229 Ego_Lane_NextHotspot_Side_4 "Side of the lane change";
CM_ SG_ 1230 Left_Lane_Info_CRC "CRC - Autosar E2E Profile 5";
CM_ SG_ 1230 Left_Lane_Info_AliveCtr "Alive counter - Autosar E2E Profile 5";
CM_ SG_ 1230 Left_Lane_Info_TimeStamp "Map data timestamp for synchronization";
CM_ SG_ 1230 Left_Lane_Exists "Indicates if the lane exists";
CM_ SG_ 1230 Left_Lane_isOvertakeLane "Indicates if the lane is the overtake lane";
CM_ SG_ 1230 Left_Lane_Start_dx "Indicates when this lane starts";
CM_ SG_ 1230 Left_CurrentSpeedLimit "Current speed limit on the Ego Lane
159 indicates an unknown speed";
CM_ SG_ 1230 Left_CurrentSpeedLimit_Type "type of the speed limit";
CM_ SG_ 1230 Left_NextSpeedLimit_Value_1 "Next speed limit on left lane";
CM_ SG_ 1230 Left_NextSpeedLimit_Location_1 "Next speed limit location on left lane";
CM_ SG_ 1230 Left_NextSpeedLimit_Type_1 "type of the next speed limit";
CM_ SG_ 1230 Left_SpeedProfile_Far_N "Number of valid elements in speed profile";
CM_ SG_ 1230 Left_NextTopo_Loc_1 "Next location of topology change";
CM_ SG_ 1230 Left_NextTopo_Type_1 "Next type of topology change";
CM_ SG_ 1230 Left_NextTopo_Side_1 "Side of the next topology change";
CM_ SG_ 1230 Left_NextTopo_Side_2 "Side of the next topology change";
CM_ SG_ 1230 Left_NextTopo_Loc_3 "Next location of topology change";
CM_ SG_ 1230 Left_NextTopo_Type_3 "Next type of topology change";
CM_ SG_ 1230 Left_NextTopo_Side_3 "Side of the next topology change";
CM_ SG_ 1230 Left_NextTopo_Loc_4 "Next location of topology change";
CM_ SG_ 1230 Left_NextTopo_Type_4 "Next type of topology change";
CM_ SG_ 1230 Left_NextTopo_Side_4 "Side of the next topology change";
CM_ SG_ 1231 Right_Lane_Info_CRC "CRC - Autosar E2E Profile 5";
CM_ SG_ 1231 Right_Lane_Info_AliveCtr "Alive counter - Autosar E2E Profile 5";
CM_ SG_ 1231 Right_Lane_Info_TimeStamp "Map data timestamp for synchronization";
CM_ SG_ 1231 Right_Lane_Exists "Indicates if the lane exists";
CM_ SG_ 1231 Right_Lane_isOvertakeLane "Indicates if the lane is the overtake lane";
CM_ SG_ 1231 Right_Lane_Start_dx "Indicates when this lane starts";
CM_ SG_ 1231 Right_CurrentSpeedLimit "Current speed limit on the Ego Lane
159 indicates an unknown speed";
CM_ SG_ 1231 Right_CurrentSpeedLimit_Type "type of the speed limit";
CM_ SG_ 1231 Right_NextSpeedLimit_Value_1 "Next speed limit on left lane";
CM_ SG_ 1231 Right_NextSpeedLimit_Location_1 "Next speed limit location on left lane";
CM_ SG_ 1231 Right_NextSpeedLimit_Type_1 "type of the next speed limit";
CM_ SG_ 1231 Right_SpeedProfile_Far_N "Number of valid elements in speed profile";
CM_ SG_ 1231 Right_NextTopo_Loc_1 "Next location of topology change";
CM_ SG_ 1231 Right_NextTopo_Type_1 "Next type of topology change";
CM_ SG_ 1231 Right_NextTopo_Side_1 "Side of the next topology change";
CM_ SG_ 1231 Right_NextTopo_Side_2 "Side of the next topology change";
CM_ SG_ 1231 Right_NextTopo_Loc_3 "Next location of topology change";
CM_ SG_ 1231 Right_NextTopo_Type_3 "Next type of topology change";
CM_ SG_ 1231 Right_NextTopo_Side_3 "Side of the next topology change";
CM_ SG_ 1231 Right_NextTopo_Side_4 "Side of the next topology change";
CM_ SG_ 453 ADAS_1C5_CheckSum "CheckSum ADAS_1C1 - DataID 0";
CM_ SG_ 453 ADAS_1C5_AliveCounter "AliveCounter ADAS_1C5 - AUTOSAR E2E Profile 1";
CM_ SG_ 453 EPS_ActRoadWheelAngValue "Actual Road Wheel Angle";
CM_ SG_ 453 EPS_ActRPCTrq "Actual RPC torque request (TBT level)";
CM_ SG_ 453 EPS_LatDrvLvl12SrvAvl "Lateral level 12 driving service availability";
CM_ SG_ 453 EPS_IntRPCMaxTrq "Maximum internally allowed RPC torque for Level 2 (safety limit)(TBT level)";
CM_ SG_ 453 EPS_IntRPCMinTrq "Minimum internally allowed RPC torque for Level 2 (safety limit)(TBT level)";
CM_ SG_ 453 EPS_LatMCHptcWrnSrvAvl "Describes the availability of the Haptic Warning Service, availability to respond to a haptic request";
CM_ SG_ 453 EPS_ActRoadWheelAngState "State of signal ActRoadWheelAngleValue";
CM_ SG_ 453 EPS_LatMCRoadWheelAngActive "Lateral Motion Control feedback signal for the Road Wheel Angle service activation";
CM_ SG_ 1210 DisplayedLaneMarking4Y "Provides the location of the lane 4 as a lateral distance from ego center";
CM_ SG_ 1210 DisplayedLaneMarking3Y "Provides the location of lane 3 as a lateral distance from ego center";
CM_ SG_ 1210 DisplayedLaneMarking2Y "Provides the location of lane 2 as a lateral distance from ego center";
CM_ SG_ 1210 DisplayedLaneMarking1Y "Provides the location of lane 1 as a lateral distance from ego center";
CM_ SG_ 1210 DisplayedLaneMarking4Type "Indicates the style of lane 4 marking";
CM_ SG_ 1210 DisplayedLaneMarking3Type "Indicates the style of lane 3 marking";
CM_ SG_ 1210 DisplayedLaneMarking2Type "Indicates the style of lane 2 marking";
CM_ SG_ 1210 DisplayedLaneMarking1Type "Indicates the style of lane 1 marking";
CM_ SG_ 1210 DisplayedLaneMarking4Color "Indicates the color of lane 4 marking";
CM_ SG_ 1210 DisplayedLaneMarking3Color "Indicates the color of lane 3 marking";
CM_ SG_ 1210 DisplayedLaneMarking2Color "Indicates the color of lane 1 marking";
CM_ SG_ 1210 DisplayedLaneMarking1Color "Indicates the color of lane1  marking";
CM_ SG_ 1210 Number02 "Representation of a displayed number";
CM_ SG_ 1210 Number01 "Representation of a displayed number";
CM_ SG_ 1210 Indicator16 "display indicator";
CM_ SG_ 1210 Indicator15 "display indicator";
CM_ SG_ 1210 Indicator14 "display indicator";
CM_ SG_ 1210 Indicator13 "display indicator";
CM_ SG_ 1210 Indicator12 "display indicator";
CM_ SG_ 1210 Indicator11 "display indicator";
CM_ SG_ 1210 Indicator10 "display indicator";
CM_ SG_ 1210 Indicator09 "display indicator";
CM_ SG_ 1210 Indicator08 "display indicator";
CM_ SG_ 1210 Indicator07 "display indicator";
CM_ SG_ 1210 Indicator06 "display indicator";
CM_ SG_ 1210 Indicator05 "display indicator";
CM_ SG_ 1210 Indicator04 "display indicator";
CM_ SG_ 1210 Indicator03 "display indicator";
CM_ SG_ 1210 Indicator02 "display indicator";
CM_ SG_ 1210 Indicator01 "display indicator";
CM_ SG_ 1210 ACC_ICON_LADI "Displays the LADI-Icon in the bottom row as an indicator for lateral-danger";
CM_ SG_ 1210 ADAS_4BA_CheckSum "CheckSum ADAS_4BA";
CM_ SG_ 1210 EgoDistanceToRightLaneMarking "Provides the lateral distance of ego center to right lane marking";
CM_ SG_ 1210 CurvatureInformation "Provides the curve radius in m";
CM_ SG_ 1210 TrafficSignSpeedLimit "Displays the legal speed limit according to traffic signs";
CM_ SG_ 1210 SensorConeRearLeft "Displays the sensing area of the rear left radar";
CM_ SG_ 1210 SensorConeRearRight "Displays the sensing area of the rear right radar";
CM_ SG_ 1210 SensorConeFrontLeft "Displays the sensing area of the front left radar";
CM_ SG_ 1210 SensorConeFrontRight "Displays the sensing area of the front right radar";
CM_ SG_ 1210 SensorConeFrontCenter "Displays the sensing area of the front center radar";
CM_ SG_ 1210 NeighboringVehicle1VehicleType "Provides the type of the neihboring vehicle no. 1";
CM_ SG_ 1210 NeighboringVehicle1X "Provides the location of the neighboring vehicle no.1 as a longitudinal distance from ego center";
CM_ SG_ 1210 NeighboringVehicle1Y "Provides the location of the neighboring vehicle no.1 as a lateral distance from ego center";
CM_ SG_ 1210 NeighboringVehicle1AugmentedData "Provides additional information of the surrounding vehicle no. 1";
CM_ SG_ 1210 NeighboringVehicle2VehicleType "Provides the type of the neihboring vehicle no. 2";
CM_ SG_ 1210 NeighboringVehicle2X "Provides the location of the neighboring vehicle no.2 as a longitudinal distance from ego center";
CM_ SG_ 1210 NeighboringVehicle2Y "Provides the location of the neighboring vehicle no.2 as a lateral distance from ego center";
CM_ SG_ 1210 ADAS_4BA_AliveCounter "AliveCounter ADAS_4BA";
CM_ SG_ 1210 NeighboringVehicle2AugmentedData "Provides additional information of the surrounding vehicle no. 2";
CM_ SG_ 1210 NeighboringVehicle3VehicleType "Provides the type of the neihboring vehicle no. 3";
CM_ SG_ 1210 NeighboringVehicle3X "Provides the location of the neighboring vehicle no.3 as a longitudinal distance from ego center";
CM_ SG_ 1210 NeighboringVehicle3Y "Provides the location of the neighboring vehicle no.3 as a lateral distance from ego center";
CM_ SG_ 1210 NeighboringVehicle3AugmentedData "Provides additional information of the surrounding vehicle no. 3";
CM_ SG_ 1210 NeighboringVehicle4VehicleType "Provides the type of the neihboring vehicle no. 4";
CM_ SG_ 1210 NeighboringVehicle4X "Provides the location of the neighboring vehicle no.4 as a longitudinal distance from ego center";
CM_ SG_ 1210 NeighboringVehicle4Y "Provides the location of the neighboring vehicle no.4 as a lateral distance from ego center";
CM_ SG_ 1210 NeighboringVehicle4AugmentedData "Provides additional information of the surrounding vehicle no. 4";
CM_ SG_ 1210 NeighboringVehicle5VehicleType "Provides the type of the neihboring vehicle no. 5";
CM_ SG_ 1210 NeighboringVehicle5X "Provides the location of the neighboring vehicle no.5 as a longitudinal distance from ego center";
CM_ SG_ 1210 NeighboringVehicle5Y "Provides the location of the neighboring vehicle no.5 as a lateral distance from ego center";
CM_ SG_ 1210 NeighboringVehicle5AugmentedData "Provides additional information of the surrounding vehicle no. 5";
CM_ SG_ 1210 NeighboringVehicle6VehicleType "Provides the type of the neihboring vehicle no. 6";
CM_ SG_ 1210 NeighboringVehicle6X "Provides the location of the neighboring vehicle no.6 as a longitudinal distance from ego center";
CM_ SG_ 1210 LedHadState "Displays the HWA-hf system state visually by using two LED-panels on the cockpit";
CM_ SG_ 1210 NeighboringVehicle6Y "Provides the location of the neighboring vehicle no.6 as a lateral distance from ego center";
CM_ SG_ 1210 NeighboringVehicle6AugmentedData "Provides additional information of the surrounding vehicle no. 6";
CM_ SG_ 1210 NeighboringVehicle7VehicleType "Provides the type of the neihboring vehicle no. 7";
CM_ SG_ 1210 NeighboringVehicle7X "Provides the location of the neighboring vehicle no.7 as a longitudinal distance from ego center";
CM_ SG_ 1210 NeighboringVehicle7Y "Provides the location of the neighboring vehicle no.7 as a lateral distance from ego center";
CM_ SG_ 1210 NeighboringVehicle7AugmentedData "Provides additional information of the surrounding vehicle no. 7";
CM_ SG_ 1210 NeighboringVehicle8VehicleType "Provides the type of the neihboring vehicle no. 8";
CM_ SG_ 1210 HwaHfStatus "Indicates status / availability of the hands free control";
CM_ SG_ 1210 NeighboringVehicle8X "Provides the location of the neighboring vehicle no.8 as a longitudinal distance from ego center";
CM_ SG_ 1210 NeighboringVehicle8Y "Provides the location of the neighboring vehicle no.8 as a lateral distance from ego center";
CM_ SG_ 1210 NeighboringVehicle8AugmentedData "Provides additional information of the surrounding vehicle no. 8";
CM_ SG_ 1210 HwaHonStatus "Indicates status / availability of the hands on control";
CM_ SG_ 1210 HwaAccStatus "Indicates status / availability of the ACC control";
CM_ SG_ 1210 SetSpeed "Indicates the set speed for hands free control";
CM_ SG_ 1210 SetSpeedColor "Sets the color of the set speed digits";
CM_ SG_ 1210 DisplayedEgoSpeed "Indicates the actual speed";
CM_ SG_ 1210 DisplayedEgoSpeedColor "Sets the color of the set speed digits";
CM_ SG_ 1210 DisplayedLaneMarkingLeftType "Indicates the style of left lane marking";
CM_ SG_ 1210 DisplayedLaneMarkingLeftColor "Indicates the color of left lane marking";
CM_ SG_ 1210 DisplayedLaneMarkingRightType "Indicates the style of right lane marking";
CM_ SG_ 1210 DisplayedLaneMarkingRightColor "Indicates the color of right lane marking";
CM_ SG_ 1210 TimeGapSetValue "Indicates the set value for the time gap by using visual bars and/or a range symbol in front of the ego vehicle";
CM_ SG_ 1210 TimeGapColor "Sets the color of the displayed time gap";
CM_ SG_ 1210 EgoLaneChange "Indicates when the ego vehicle plans or performs a lane change";
CM_ SG_ 1210 DisplayedTextMessageId "Displays visual text notfications on the cockpit";
CM_ SG_ 1210 PopupTextMessage "Displays the text notification of ADAS_hmiDisplayedTextMessageId in pop-up style";
CM_ SG_ 1210 AudioNotificationId "Plays back an auditory sound notification, e.g. warning sound or speech message";
CM_ SG_ 1210 AuxiliarySymbol "Displays additional symbols or animations, e.g. coffee cup (fatigue detection), collision warning, hands-on animation, etc.)";
CM_ SG_ 1210 EgoLaneAssignment "determines in which lane ego is driving";
CM_ SG_ 1210 EgoDistanceToLeftLaneMarking "Provides the lateral distance of ego center to left lane marking";
BA_DEF_ BO_  "CANFD_BRS" ENUM  "0","1";
BA_DEF_ BO_  "GenMsgCycleTime" INT 0 65535;
BA_DEF_ BO_  "GenMsgSendType" ENUM  "cyclic","Event","NoMsgSendType";
BA_DEF_ BO_  "VFrameFormat" ENUM  "StandardCAN","ExtendedCAN","reserved","reserved","reserved","reserved","reserved","reserved","reserved","reserved","reserved","reserved","reserved","reserved","StandardCAN_FD","ExtendedCAN_FD";
BA_DEF_ SG_  "GenSigStartValue" FLOAT 0 100000000000;
BA_DEF_  "BusType" STRING ;
BA_DEF_  "DBName" STRING ;
BA_DEF_DEF_  "CANFD_BRS" "1";
BA_DEF_DEF_  "GenMsgCycleTime" 0;
BA_DEF_DEF_  "GenMsgSendType" "";
BA_DEF_DEF_  "VFrameFormat" "";
BA_DEF_DEF_  "GenSigStartValue" 0;
BA_DEF_DEF_  "BusType" "";
BA_DEF_DEF_  "DBName" "ChooseYourNameHere";
BA_ "BusType" "CAN FD";
BA_ "DBName" "OneDriving_ADAS_Public_CANFD";
BA_ "GenMsgSendType" BO_ 603 0;
BA_ "GenMsgCycleTime" BO_ 603 20;
BA_ "VFrameFormat" BO_ 603 14;
BA_ "GenMsgSendType" BO_ 627 0;
BA_ "GenMsgCycleTime" BO_ 627 10;
BA_ "VFrameFormat" BO_ 627 14;
BA_ "GenMsgSendType" BO_ 626 0;
BA_ "GenMsgCycleTime" BO_ 626 10;
BA_ "VFrameFormat" BO_ 626 14;
BA_ "VFrameFormat" BO_ 272 0;
BA_ "GenMsgSendType" BO_ 272 0;
BA_ "VFrameFormat" BO_ 261 0;
BA_ "GenMsgSendType" BO_ 261 0;
BA_ "VFrameFormat" BO_ 262 0;
BA_ "GenMsgSendType" BO_ 262 0;
BA_ "VFrameFormat" BO_ 260 0;
BA_ "GenMsgSendType" BO_ 260 0;
BA_ "VFrameFormat" BO_ 259 0;
BA_ "GenMsgSendType" BO_ 259 0;
BA_ "VFrameFormat" BO_ 258 0;
BA_ "GenMsgSendType" BO_ 258 0;
BA_ "VFrameFormat" BO_ 257 0;
BA_ "GenMsgSendType" BO_ 257 0;
BA_ "VFrameFormat" BO_ 1283 0;
BA_ "GenMsgSendType" BO_ 1283 0;
BA_ "VFrameFormat" BO_ 1282 0;
BA_ "GenMsgSendType" BO_ 1282 0;
BA_ "GenMsgSendType" BO_ 443 0;
BA_ "GenMsgCycleTime" BO_ 443 10;
BA_ "VFrameFormat" BO_ 443 14;
BA_ "GenMsgSendType" BO_ 601 0;
BA_ "GenMsgCycleTime" BO_ 601 20;
BA_ "VFrameFormat" BO_ 601 14;
BA_ "GenMsgSendType" BO_ 716 0;
BA_ "GenMsgCycleTime" BO_ 716 50;
BA_ "VFrameFormat" BO_ 716 14;
BA_ "GenMsgSendType" BO_ 449 0;
BA_ "GenMsgCycleTime" BO_ 449 10;
BA_ "VFrameFormat" BO_ 449 14;
BA_ "GenMsgSendType" BO_ 1216 0;
BA_ "GenMsgCycleTime" BO_ 1216 100;
BA_ "VFrameFormat" BO_ 1216 14;
BA_ "GenMsgSendType" BO_ 1217 0;
BA_ "GenMsgCycleTime" BO_ 1217 100;
BA_ "VFrameFormat" BO_ 1217 14;
BA_ "GenMsgSendType" BO_ 1220 0;
BA_ "GenMsgCycleTime" BO_ 1220 100;
BA_ "VFrameFormat" BO_ 1220 14;
BA_ "GenMsgSendType" BO_ 1218 0;
BA_ "GenMsgCycleTime" BO_ 1218 100;
BA_ "VFrameFormat" BO_ 1218 14;
BA_ "GenMsgSendType" BO_ 1219 0;
BA_ "GenMsgCycleTime" BO_ 1219 100;
BA_ "VFrameFormat" BO_ 1219 14;
BA_ "GenMsgSendType" BO_ 1221 0;
BA_ "GenMsgCycleTime" BO_ 1221 100;
BA_ "VFrameFormat" BO_ 1221 14;
BA_ "GenMsgSendType" BO_ 1226 0;
BA_ "GenMsgCycleTime" BO_ 1226 100;
BA_ "VFrameFormat" BO_ 1226 14;
BA_ "GenMsgSendType" BO_ 1227 0;
BA_ "GenMsgCycleTime" BO_ 1227 100;
BA_ "VFrameFormat" BO_ 1227 14;
BA_ "GenMsgSendType" BO_ 1228 0;
BA_ "GenMsgCycleTime" BO_ 1228 100;
BA_ "VFrameFormat" BO_ 1228 14;
BA_ "GenMsgSendType" BO_ 1229 0;
BA_ "GenMsgCycleTime" BO_ 1229 100;
BA_ "VFrameFormat" BO_ 1229 14;
BA_ "GenMsgSendType" BO_ 1230 0;
BA_ "GenMsgCycleTime" BO_ 1230 100;
BA_ "VFrameFormat" BO_ 1230 14;
BA_ "GenMsgSendType" BO_ 1231 0;
BA_ "GenMsgCycleTime" BO_ 1231 100;
BA_ "VFrameFormat" BO_ 1231 14;
BA_ "GenMsgSendType" BO_ 800 0;
BA_ "GenMsgCycleTime" BO_ 800 50;
BA_ "VFrameFormat" BO_ 800 14;
BA_ "GenMsgSendType" BO_ 453 0;
BA_ "GenMsgCycleTime" BO_ 453 10;
BA_ "VFrameFormat" BO_ 453 14;
BA_ "GenMsgSendType" BO_ 1210 0;
BA_ "GenMsgCycleTime" BO_ 1210 50;
BA_ "VFrameFormat" BO_ 1210 14;
BA_ "GenSigStartValue" SG_ 443 WhlTqMin 32768;
BA_ "GenSigStartValue" SG_ 449 ADAS_RdWhlAgReq 9000;
BA_ "GenSigStartValue" SG_ 449 ADAS_ExtMaxRPCTrq 1024;
BA_ "GenSigStartValue" SG_ 449 ADAS_ExtMinRPCTrq 1024;
BA_ "GenSigStartValue" SG_ 1217 Cv_Offset_Seg00 1023;
BA_ "GenSigStartValue" SG_ 1217 Cv_Offset_Seg01 1023;
BA_ "GenSigStartValue" SG_ 1217 Cv_Offset_Seg02 1023;
BA_ "GenSigStartValue" SG_ 1217 Cv_Offset_Seg03 1023;
BA_ "GenSigStartValue" SG_ 1217 Cv_Offset_Seg04 1023;
BA_ "GenSigStartValue" SG_ 1217 Cv_Offset_Seg05 1023;
BA_ "GenSigStartValue" SG_ 1217 Cv_Offset_Seg06 1023;
BA_ "GenSigStartValue" SG_ 1217 Cv_Offset_Seg07 1023;
BA_ "GenSigStartValue" SG_ 1217 Cv_Offset_Seg08 1023;
BA_ "GenSigStartValue" SG_ 1217 Cv_Offset_Seg09 1023;
BA_ "GenSigStartValue" SG_ 1217 Cv_Offset_Seg10 1023;
BA_ "GenSigStartValue" SG_ 1217 Cv_Offset_Seg11 1023;
BA_ "GenSigStartValue" SG_ 1217 Cv_Offset_Seg12 1023;
BA_ "GenSigStartValue" SG_ 1217 Cv_Offset_Seg13 1023;
BA_ "GenSigStartValue" SG_ 1217 Cv_Offset_Seg14 1023;
BA_ "GenSigStartValue" SG_ 1217 Cv_Offset_Seg15 1023;
BA_ "GenSigStartValue" SG_ 1217 Cv_Offset_Seg16 1023;
BA_ "GenSigStartValue" SG_ 1217 Cv_Offset_Seg17 1023;
BA_ "GenSigStartValue" SG_ 1217 Cv_Offset_Seg18 1023;
BA_ "GenSigStartValue" SG_ 1217 Cv_Offset_Seg19 1023;
BA_ "GenSigStartValue" SG_ 1226 ReferenceLine_dy_00 2048;
BA_ "GenSigStartValue" SG_ 1226 ReferenceLine_dy_01 2048;
BA_ "GenSigStartValue" SG_ 1226 ReferenceLine_dy_02 2048;
BA_ "GenSigStartValue" SG_ 1226 ReferenceLine_dy_03 2048;
BA_ "GenSigStartValue" SG_ 1226 ReferenceLine_dy_04 2048;
BA_ "GenSigStartValue" SG_ 1226 ReferenceLine_dy_05 2048;
BA_ "GenSigStartValue" SG_ 1226 ReferenceLine_dy_06 2048;
BA_ "GenSigStartValue" SG_ 1226 ReferenceLine_dy_07 2048;
BA_ "GenSigStartValue" SG_ 1226 ReferenceLine_dy_08 2048;
BA_ "GenSigStartValue" SG_ 1226 ReferenceLine_dy_09 2048;
BA_ "GenSigStartValue" SG_ 1226 ReferenceLine_dy_10 2048;
BA_ "GenSigStartValue" SG_ 1226 ReferenceLine_dy_11 2048;
BA_ "GenSigStartValue" SG_ 1226 ReferenceLine_dy_12 2048;
BA_ "GenSigStartValue" SG_ 1226 ReferenceLine_dy_13 2048;
BA_ "GenSigStartValue" SG_ 1226 ReferenceLine_dy_14 2048;
BA_ "GenSigStartValue" SG_ 1226 ReferenceLine_dy_15 2048;
BA_ "GenSigStartValue" SG_ 1226 ReferenceLine_dy_16 2048;
BA_ "GenSigStartValue" SG_ 1226 ReferenceLine_dy_17 2048;
BA_ "GenSigStartValue" SG_ 1226 ReferenceLine_dy_18 2048;
BA_ "GenSigStartValue" SG_ 1227 ReferenceLine_dy_19 2048;
BA_ "GenSigStartValue" SG_ 1227 ReferenceLine_dy_20 2048;
BA_ "GenSigStartValue" SG_ 1227 ReferenceLine_dy_21 2048;
BA_ "GenSigStartValue" SG_ 1227 ReferenceLine_dy_22 2048;
BA_ "GenSigStartValue" SG_ 1227 ReferenceLine_dy_23 2048;
BA_ "GenSigStartValue" SG_ 1227 ReferenceLine_dy_24 2048;
BA_ "GenSigStartValue" SG_ 1227 ReferenceLine_dy_25 2048;
BA_ "GenSigStartValue" SG_ 1227 ReferenceLine_dy_26 2048;
BA_ "GenSigStartValue" SG_ 1227 ReferenceLine_dy_27 2048;
BA_ "GenSigStartValue" SG_ 1227 ReferenceLine_dy_28 2048;
BA_ "GenSigStartValue" SG_ 1227 ReferenceLine_dy_29 2048;
BA_ "GenSigStartValue" SG_ 1227 ReferenceLine_dy_30 2048;
BA_ "GenSigStartValue" SG_ 1227 ReferenceLine_dy_31 2048;
BA_ "GenSigStartValue" SG_ 1227 ReferenceLine_dy_32 2048;
BA_ "GenSigStartValue" SG_ 1227 ReferenceLine_dy_33 2048;
BA_ "GenSigStartValue" SG_ 1227 ReferenceLine_dy_34 2048;
BA_ "GenSigStartValue" SG_ 453 EPS_ActRoadWheelAngValue 9000;
BA_ "GenSigStartValue" SG_ 453 EPS_ActRPCTrq 1024;
BA_ "GenSigStartValue" SG_ 453 EPS_IntRPCMaxTrq 1024;
BA_ "GenSigStartValue" SG_ 453 EPS_IntRPCMinTrq 1024;
BA_ "GenSigStartValue" SG_ 1210 NeighboringVehicle1X 42;
BA_ "GenSigStartValue" SG_ 1210 NeighboringVehicle2X 42;
BA_ "GenSigStartValue" SG_ 1210 NeighboringVehicle3X 42;
BA_ "GenSigStartValue" SG_ 1210 NeighboringVehicle4X 42;
BA_ "GenSigStartValue" SG_ 1210 NeighboringVehicle5X 42;
BA_ "GenSigStartValue" SG_ 1210 NeighboringVehicle6X 42;
BA_ "GenSigStartValue" SG_ 1210 NeighboringVehicle7X 42;
BA_ "GenSigStartValue" SG_ 1210 NeighboringVehicle8X 42;
VAL_ 603 ADAS_Fwd_Safety_Func 0 "NoSafetyFunctionRequest" 1 "BrakeKeepHolding" 4097 "Cfm_BrakeKeepHolding" 4098 "Cfm_StartPrevention" 4100 "Cfm_AutomaticEvasiveSteering" 4104 "Cfm_EvasiveSteeringSupport" 4112 "Cfm_Prefill" 4128 "Cfm_PartialBrake" 4160 "Cfm_FullBrake" 4224 "Cfm_EmergencyBrakeAssist" 4608 "Cfm_WarnOptic" 5120 "Cfm_WarnAcoustic" 6144 "Cfm_WarnHaptic" 8193 "Tixl_BrakeKeepHolding" 8194 "Tixl_StartPrevention" 8196 "Tixl_AutomaticEvasiveSteering" 8200 "Tixl_EvasiveSteeringSupport" 8208 "Tixl_Prefill" 8224 "Tixl_PartialBrake" 8256 "Tixl_FullBrake" 8320 "Tixl_EmergencyBrakeAssist" 8704 "Tixl_WarnOptic" 9216 "Tixl_WarnAcoustic" 10240 "Tixl_WarnHaptic" 16385 "TiplTurn_BrakeKeepHolding" 16386 "TiplTurn_StartPrevention" 16388 "TiplTurn_AutomaticEvasiveSteerin" 16392 "TiplTurn_EvasiveSteeringSupport" 16400 "TiplTurn_Prefill" 16416 "TiplTurn_PartialBrake" 16448 "TiplTurn_FullBrake" 16512 "TiplTurn_EmergencyBrakeAssist" 16896 "TiplTurn_WarnOptic" 17408 "TiplTurn_WarnAcoustic" 18432 "TiplTurn_WarnHaptic" 32769 "TiplLong_BrakeKeepHolding" 32770 "TiplLong_StartPrevention" 32772 "TiplLong_AutomaticEvasiveSteerin" 32776 "TiplLong_EvasiveSteeringSupport" 32784 "TiplLong_Prefill" 32800 "TiplLong_PartialBrake" 32832 "TiplLong_FullBrake" 32896 "TiplLong_EmergencyBrakeAssist" 33024 "TiplLong_LatentInfo" 33280 "TiplLong_WarnOptic" 33792 "TiplLong_WarnAcoustic" 34816 "TiplLong_WarnHaptic" 65535 "Invalid" ;
VAL_ 627 status_rate_z 0 "Init" 1 "Sporadic_Error" 2 "Permanent_Error" 3 "Valid" ;
VAL_ 627 status_rate_y 0 "Init" 1 "Sporadic_Error" 2 "Permanent_Error" 3 "Valid" ;
VAL_ 627 status_rate_x 0 "Init" 1 "Sporadic_Error" 2 "Permanent_Error" 3 "Valid" ;
VAL_ 626 status_acc_z 0 "Init" 1 "Sporadic_Error" 2 "Permanent_Error" 3 "Valid" ;
VAL_ 626 status_acc_y 0 "Init" 1 "Sporadic_Error" 2 "Permanent_Error" 3 "Valid" ;
VAL_ 626 status_acc_x 0 "Init" 1 "Sporadic_Error" 2 "Permanent_Error" 3 "Valid" ;
VAL_ 272 ADASLONG_Mux_MsgTyp 0 "SNA" 1 "POSITION" 2 "SEGMENT" 3 "STUB" 4 "PROFILE_SHORT" 5 "PROFILE_LONG" 6 "META_DATA" 7 "RESERVED" ;
VAL_ 261 ADAS_ProfLong_Update 0 "false" 1 "true" ;
VAL_ 261 ADAS_ProfLong_Retr 0 "false" 1 "true" ;
VAL_ 261 ADAS_ProfLong_PathIdx 0 "Unknown" 1 "Position not in digitized Area" 2 "Position not on-road" 3 "System not calibrated" 4 "Current Segment Attributes" 5 "Stub only" 6 "This Path" 7 "Reserved" ;
VAL_ 261 ADAS_ProfLong_Offset 8191 "invalid" ;
VAL_ 261 ADAS_ProfLong_MsgType 0 "SNA" 1 "POSITION" 2 "SEGMENT" 3 "STUB" 4 "PROFILE_SHORT" 5 "PROFILE_LONG" 6 "META_DATA" 7 "RESERVED" ;
VAL_ 261 ADAS_ProfLong_CtrlPoint 0 "false" 1 "true" ;
VAL_ 261 ADAS_ProfLong_ProfType 0 "Invalid" 1 "Longitude" 2 "Latitude" 3 "Reserved3" 4 "Reserved4" 5 "Reserved5" 6 "Reserved6" 7 "Reserved7" 8 "Reserved8" 9 "Reserved9" 10 "Reserved10" 11 "Reserved11" 12 "Reserved12" 13 "Reserved13" 14 "Reserved14" 15 "Reserved15" 16 "System_Specific" 17 "System_Specific" 18 "System_Specific" 19 "System_Specific" 20 "System_Specific" 21 "System_Specific" 22 "System_Specific" 23 "System_Specific" 24 "System_Specific" 25 "System_Specific" 26 "System_Specific" 27 "System_Specific" 28 "System_Specific" 29 "System_Specific" 30 "System_Specific" 31 "System_Specific" ;
VAL_ 262 ADAS_Meta_MsgType 0 "SNA" 1 "POSITION" 2 "SEGMENT" 3 "STUB" 4 "PROFILE_SHORT" 5 "PROFILE_LONG" 6 "META_DATA" 7 "RESERVED" ;
VAL_ 262 ADAS_Meta_MapProvider 0 "Unknown" 1 "NAVTEQ" 2 "TeleAtlas" 3 "Zenrin" 4 "Reserverd" 5 "Reserverd" 6 "Reserverd" 7 "SNA" ;
VAL_ 262 ADAS_Meta_HwVer 0 "Unknown" ;
VAL_ 262 ADAS_Meta_SpdUnits 0 "kilometers/hour" 1 "Miles/hour" ;
VAL_ 262 ADAS_Meta_DrvSide 0 "Left-side driving" 1 "Right-side driving" ;
VAL_ 262 ADAS_Meta_RegionCode 0 "Unknown" 32767 "SNA" ;
VAL_ 262 ADAS_Meta_CountryCode 0 "UNKNOWN" 276 "DEU" ;
VAL_ 260 ADAS_ProfShort_Update 0 "false" 1 "true" ;
VAL_ 260 ADAS_ProfShort_ProfType 0 "Invalid" 1 "Curvature" 2 "Route_Numbers" 3 "Slope_step" 4 "Slope_linear" 5 "Road_Accessibility_Bitfield" 6 "Road_Condition_Bitfield" 7 "Var_Spd_Sign_Posn_Bitfield" 8 "Heading_Change" 9 "Reserved9" 10 "Reserved10" 11 "Reserved11" 12 "Reserved12" 13 "Reserved13" 14 "Reserved14" 15 "Reserved15" 16 "System_Specific" 17 "System_Specific" 18 "System_Specific" 19 "System_Specific" 20 "System_Specific" 21 "System_Specific" 22 "System_Specific" 23 "System_Specific" 24 "System_Specific" 25 "System_Specific" 26 "System_Specific" 27 "System_Specific" 28 "System_Specific" 29 "System_Specific" 30 "System_Specific" 31 "System_Specific" ;
VAL_ 260 ADAS_ProfShort_Retr 0 "false" 1 "true" ;
VAL_ 260 ADAS_ProfShort_PathIdx 0 "Unknown" 1 "Position not in digitized Area" 2 "Position not on-road" 3 "System not calibrated" 4 "Current Segment Attributes" 5 "Stub only" 6 "This Path" 7 "Reserved" ;
VAL_ 260 ADAS_ProfShort_Offset 8191 "invalid" ;
VAL_ 260 ADAS_ProfShort_MsgType 0 "SNA" 1 "POSITION" 2 "SEGMENT" 3 "STUB" 4 "PROFILE_SHORT" 5 "PROFILE_LONG" 6 "META_DATA" 7 "RESERVED" ;
VAL_ 260 ADAS_ProfShort_Dist1 0 "no other profile values are defi" ;
VAL_ 260 ADAS_ProfShort_CtrlPoint 0 "false" 1 "true" ;
VAL_ 259 ADAS_Stub_PartOfCalcRoute 0 "false" 1 "true" ;
VAL_ 259 ADAS_Stub_FuncRoadClass 0 "Unknown" 7 "SNA" ;
VAL_ 259 ADAS_Stub_LastStub 255 "Unknown" ;
VAL_ 259 ADAS_Stub_Update 0 "false" 1 "true" ;
VAL_ 259 ADAS_Stub_SubPathIdx 0 "Unknown" 1 "Position not in digitized Area" 2 "Position not on-road" 3 "System not calibrated" 4 "Current Segment Attributes" 5 "Stub only" 6 "This Path" 7 "Reserved" ;
VAL_ 259 ADAS_Stub_Retr 0 "false" 1 "true" ;
VAL_ 259 ADAS_Stub_PathIdx 0 "Unknown" 1 "Position not in digitized Area" 2 "Position not on-road" 3 "System not calibrated" 4 "Current Segment Attributes" 5 "Stub only" 6 "This Path" 7 "Reserved" ;
VAL_ 259 ADAS_Stub_Offset 8191 "invalid" ;
VAL_ 259 ADAS_Stub_NumOfLaneOppDir 0 "One direction road" 1 "One lane only" 2 "Two or more lanes" 3 "Unknown" ;
VAL_ 259 ADAS_Stub_NumOfLaneDrvDir 0 "Wrong direction" 6 "6 or more lanes" 7 "Unknown" ;
VAL_ 259 ADAS_Stub_MsgType 0 "SNA" 1 "POSITION" 2 "SEGMENT" 3 "STUB" 4 "PROFILE_SHORT" 5 "PROFILE_LONG" 6 "META_DATA" 7 "RESERVED" ;
VAL_ 259 ADAS_Stub_FormOfWay 0 "Unknown" 1 "Freeway without Slip Roads" 2 "Multiply Carriageway" 3 "Single Carriageway" 4 "Roundabout" 5 "Special Traffic Figure" 6 "Reserved6" 7 "Reserved7" 8 "Parallel Road" 9 "Slip Road on Freeway" 10 "Slip Road not on Freeway" 11 "Service or Frontage Road" 12 "Entrance to or Exit of Car Park" 13 "Entrance to or Exit to Service" 14 "Pedestrian Zone" 15 "SNA" ;
VAL_ 259 ADAS_Stub_RtOfWay 0 "Path has rt-of-way over sub-path" 1 "Sub-path has rt-of-way over path" 2 "Unknown" 3 "Invalid" ;
VAL_ 259 ADAS_Stub_CmplxInsct 0 "False" 1 "True" 2 "Unknown" 3 "Invalid" ;
VAL_ 259 ADAS_Stub_RelProbb 0 "Turn not allowed" 31 "Unknown" ;
VAL_ 259 ADAS_Stub_TurnAngl 0 "In path direction" 1 "1.417 deg right from path dir" 126 "178.583 deg right" 127 "Opposite direction" 128 "178.583 deg left" 253 "1.417 deg left from path dir" 254 "Unknown" 255 "SNA" ;
VAL_ 258 ADAS_Seg_PartOfCalcRoute 0 "False" 1 "True" 2 "Unknown" 3 "Invalid" ;
VAL_ 258 ADAS_Seg_RelProbb 0 "Turn not allowed" 31 "Unknown" ;
VAL_ 258 ADAS_Seg_Offset 8191 "invalid" ;
VAL_ 258 ADAS_Seg_Retr 0 "false" 1 "true" ;
VAL_ 258 ADAS_Seg_PathIdx 0 "Unknown" 1 "Position not in digitized Area" 2 "Position not on-road" 3 "System not calibrated" 4 "Current Segment Attributes" 5 "Stub only" 6 "This Path" 7 "Reserved" ;
VAL_ 258 ADAS_Seg_MsgType 0 "SNA" 1 "POSITION" 2 "SEGMENT" 3 "STUB" 4 "PROFILE_SHORT" 5 "PROFILE_LONG" 6 "META_DATA" 7 "RESERVED" ;
VAL_ 258 ADAS_Seg_FormOfWay 0 "Unknown" 1 "Freeway without Slip Roads" 2 "Multiply Carriageway" 3 "Single Carriageway" 4 "Roundabout" 5 "Special Traffic Figure" 6 "Reserved6" 7 "Reserved7" 8 "Parallel Road" 9 "Slip Road on Freeway" 10 "Slip Road not on Freeway" 11 "Service or Frontage Road" 12 "Entrance to or Exit of Car Park" 13 "Entrance to or Exit to Service" 14 "Pedestrian Zone" 15 "SNA" ;
VAL_ 258 ADAS_Seg_CmplxInsct 0 "False" 1 "True" 2 "Unknown" 3 "Invalid" ;
VAL_ 258 ADAS_Seg_BuildUpArea 0 "False" 1 "True" 2 "Unknown" 3 "Invalid" ;
VAL_ 258 ADAS_Seg_DividedRoad 0 "False" 1 "True" 2 "Unknown" 3 "Invalid" ;
VAL_ 258 ADAS_Seg_Bridge 0 "False" 1 "True" 2 "Unknown" 3 "Invalid" ;
VAL_ 258 ADAS_Seg_Tunnel 0 "False" 1 "True" 2 "Unknown" 3 "Invalid" ;
VAL_ 258 ADAS_Seg_NumOfLaneOppDir 0 "One direction road" 1 "One lane only" 2 "Two or more lanes" 3 "Unknown" ;
VAL_ 258 ADAS_Seg_NumOfLaneDrvDir 0 "Wrong direction" 6 "6 or more lanes" 7 "Unknown" ;
VAL_ 258 ADAS_Seg_EffSpdLmtType 0 "Implicit" 1 "Explicit_on_sign" 2 "Explicit_by_night" 3 "Explicit_by_day" 4 "Explicit_time_of_day" 5 "Explicit_rain" 6 "Explicit_snow" 7 "Unknown" ;
VAL_ 258 ADAS_Seg_EffSpdLmt 0 "Unknown" 1 "5 kmph or mph" 2 "7 kmph or mph" 3 "10 kmph or mph" 4 "15 kmph or mph" 5 "20 kmph or mph" 6 "25 kmph or mph" 7 "30 kmph or mph" 8 "35 kmph or mph" 9 "40 kmph or mph" 10 "45 kmph or mph" 11 "50 kmph or mph" 12 "55 kmph or mph" 13 "60 kmph or mph" 14 "65 kmph or mph" 15 "70 kmph or mph" 16 "75 kmph or mph" 17 "80 kmph or mph" 18 "85 kmph or mph" 19 "90 kmph or mph" 20 "95 kmph or mph" 21 "100 kmph or mph" 22 "105 kmph or mph" 23 "110 kmph or mph" 24 "115 kmph or mph" 25 "120 kmph or mph" 26 "130 kmph or mph" 27 "140 kmph or mph" 28 "150 kmph or mph" 29 "160 kmph or mph" 30 "Unlimited" 31 "SNA" ;
VAL_ 258 ADAS_Seg_FuncRoadClass 0 "Unknown" 7 "SNA" ;
VAL_ 258 ADAS_Seg_Update 0 "false" 1 "true" ;
VAL_ 257 ADAS_Posn_PosProbb 31 "Invalid" ;
VAL_ 257 ADAS_Posn_CurLane 0 "Unknown" 1 "Emergency lane" 2 "Single-lane road" 3 "Left-most lane" 4 "Right-most lane" 5 "Middle lane on 3+ lane road" 6 "Reserved" 7 "SNA" ;
VAL_ 257 ADAS_Posn_Spd 511 "UNKNOWN" ;
VAL_ 257 ADAS_Posn_RelHead 0 "In path direction" 1 "1.417 deg right from path dir" 126 "178.583 deg right" 127 "Opposite direction" 252 "178.583 deg left" 253 "1.417 deg left from path dir" 254 "Unknown" 255 "SNA" ;
VAL_ 257 ADAS_Posn_Age 510 "Older than 2545 ms" 511 "Invalid" ;
VAL_ 257 ADAS_Posn_PathIdx 0 "Unknown" 1 "Position not in digitized Area" 2 "Position not on-road" 3 "System not calibrated" 4 "Current Segment Attributes" 5 "Stub only" 6 "This Path" 7 "Reserved" ;
VAL_ 257 ADAS_Posn_Offset 8191 "invalid" ;
VAL_ 257 ADAS_Posn_MsgTyp 0 "SNA" 1 "POSITION" 2 "SEGMENT" 3 "STUB" 4 "PROFILE_SHORT" 5 "PROFILE_LONG" 6 "META_DATA" 7 "RESERVED" ;
VAL_ 443 ShiftInProgress 0 "no shift" 1 "shift in progress" ;
VAL_ 601 ADAS_Req_Prefill 0 "Not Active" 1 "Active" ;
VAL_ 601 ADAS_Req_HBA 0 "Not active" 1 "Active" ;
VAL_ 601 ADAS_Req_AWB 0 "Not Active" 1 "Active" ;
VAL_ 601 ADAS_Lvl_HBA 0 "Level 0" 1 "Level 1" 2 "Level 2" 3 "Level 3" 4 "Reserved" 5 "Reserved" 6 "Reserved" 7 "Reserved" ;
VAL_ 601 ADAS_Lvl_AWB 0 "No Request" 1 "Profile 1 - AEB low brk jerk" 2 "Profile 2 - AEB med. brk jerk" 3 "Profile 3 - AEB strong brk. jerk" 4 "Profile 4 - TOR lvl 1 HF" 5 "Profile 5 - TOR lvl 2 HF" 6 "Profile 6 -" 7 "Profile 7 -" ;
VAL_ 601 ADAS_DecelTyp_AEB 0 "Default" 1 "AEB" 2 "AEB~VRU" 3 "AEB~CYCLIST" 4 "EBA" 5 "FCTB" 6 "Reserved" 7 "Reserved" 8 "Reserved" 9 "Reserved" 10 "Reserved" 11 "Reserved" 12 "Reserved" 13 "Reserved" 14 "Reserved" 15 "Reserved" ;
VAL_ 716 HODTchZone2Sts_h8HSC8 0 "No hand detected" 1 "Hand detected" 2 "Reserved" 3 "Reserved" 4 "Reserved" 5 "Reserved" 6 "Reserved" 7 "Reserved" ;
VAL_ 716 HODTchZone1Sts_h8HSC8 0 "No hand detected" 1 "Hand detected" 2 "Reserved" 3 "Reserved" 4 "Reserved" 5 "Reserved" 6 "Reserved" 7 "Reserved" ;
VAL_ 716 HODSysSts_h8HSC8 0 "Available" 1 "Initial Status" 2 "Fault" 3 "Shutdown" 4 "No Calibration" 5 "Reserved" 6 "Reserved" 7 "Reserved" ;
VAL_ 716 HODdiagSts_h8HSC8 0 "No Error" 1 "EEPROM" 2 "ROM Error" 3 "Watchdog Error" 4 "CPU Error" 5 "Guard Error" 6 "Sense Error" 7 "CPU Defect or Mat shortage" 8 "Undervoltage" 9 "Overvoltage" 10 "Coding Error" 11 "System Error" 12 "Reserved" 13 "Reserved" 14 "Reserved" 15 "Other state" ;
VAL_ 716 HODTchZone3Sts_h8HSC8 0 "No hand detected" 1 "Hand detected" 2 "Reserved" 3 "Reserved" 4 "Reserved" 5 "Reserved" 6 "Reserved" 7 "Reserved" ;
VAL_ 716 HODDetnSts_h8HSC8 0 "Unknown" 1 "No valid contact detected" 2 "Valid contact detected" 3 "Reserved" 4 "Reserved" 5 "Reserved" 6 "Reserved" 7 "Reserved" 8 "Reserved" 9 "Reserved" 10 "Reserved" 11 "Reserved" 12 "Reserved" 13 "Reserved" 14 "Reserved" 15 "Reserved" ;
VAL_ 449 DADCSteerTqReqActive 0 "SteeringTorque req not active" 1 "HO SteeringTorque request active" 2 "HF SteeringTorque request active" ;
VAL_ 449 ADAS_RdWhlAgReqActive 0 "RdWhlAgReq not active" 1 "HO RdWhlAgReq active" 2 "HF RdWhl AgReq active" ;
VAL_ 1216 GF_NumberOfLanes 0 "wrong direction" 1 "1 lane" 2 "2 lanes" 3 "3 lanes" 4 "4 lanes" 5 "5 lanes" 6 "6 or more lanes" 7 "Unknown" ;
VAL_ 1216 GF_Region_outOfODD_offset 1023 "Not within horizon" ;
VAL_ 1216 GF_Country_outOfODD_offset 1023 "Not within horizon" ;
VAL_ 1216 GF_LaneTrans_outOfODD_offset 1023 "Not within horizon" ;
VAL_ 1216 GF_Curvature_outOfODD_offset 1023 "Not within horizon" ;
VAL_ 1216 GF_LaneType_outOfODD_offset 1023 "Not within horizon" ;
VAL_ 1216 GF_RoadSlope_outOfODD_offset 1023 "Not within horizon" ;
VAL_ 1216 GF_LaneWidth_outOfODD_offset 1023 "Not within horizon" ;
VAL_ 1216 GF_FormOfWay_outOfODD_offset 1023 "Not within horizon" ;
VAL_ 1216 GF_MapExpired 0 "0" 1 "1" ;
VAL_ 1216 GF_BlackListedSegment_offset 1023 "Not within horizon" ;
VAL_ 1216 GF_Intersection_offset 1023 "Not within horizon" ;
VAL_ 1216 GF_SideWind_offset 1023 "Not within horizon" ;
VAL_ 1216 GF_TollGate_offset 1023 "Not within ehorizon" ;
VAL_ 1216 GF_TrafficLight_offset 1023 "Not within ehorizon" ;
VAL_ 1216 GF_Tunnel_Offset 1023 "Not within ehorizon" ;
VAL_ 1216 GF_MapStatus 0 "Map Ready" 1 "Map not Ready" 2 "Traffic line missing" 4 "Local ECU not ready" 8 "Initialization" 16 "Map data expired" 32 "Hardware Error" 64 "Software Error" 128 "RTK not available" 256 "GNSS signal error" 512 "MapTimeSyncStatus" ;
VAL_ 1228 Ego_Lane_Map_Status 0 "INVALID" 1 "VALID" ;
VAL_ 1228 Ego_Lane_CurrentSpeedLimit_Type 0 "EFFECTIVE" 1 "IMPLICIT" 2 "UNKNOWN" 3 "RESERVED" ;
VAL_ 1228 Ego_Lane_NextSpeedLimit_Type_1 0 "EFFECTIVE" 1 "IMPLICIT" 2 "UNKNOWN" 3 "RESERVED" ;
VAL_ 1228 Ego_Lane_NextSpeedLimit_Type_2 0 "EFFECTIVE" 1 "IMPLICIT" 2 "UNKNOWN" 3 "RESERVED" ;
VAL_ 1228 Ego_Lane_NextSpeedLimit_Type_3 0 "EFFECTIVE" 1 "IMPLICIT" 2 "UNKNOWN" 3 "RESERVED" ;
VAL_ 1228 Ego_Lane_NextSpeedLimit_Type_4 0 "EFFECTIVE" 1 "IMPLICIT" 2 "UNKNOWN" 3 "RESERVED" ;
VAL_ 1228 Ego_Lane_NextTopoType_1 0 "UNKNOWN" 1 "OPENING" 2 "CLOSING" 3 "MERGING" 4 "SPLITTING" 5 "ROAD_MERGING" 6 "ROAD_SPLITTING" ;
VAL_ 1228 Ego_Lane_NextTopoSide_1 0 "LEFT" 1 "RIGHT" ;
VAL_ 1228 Ego_Lane_NextTopoType_2 0 "UNKNOWN" 1 "OPENING" 2 "CLOSING" 3 "MERGING" 4 "SPLITTING" 5 "ROAD_MERGING" 6 "ROAD_SPLITTING" ;
VAL_ 1228 Ego_Lane_NextTopoSide_2 0 "LEFT" 1 "RIGHT" ;
VAL_ 1228 Ego_Lane_NextTopoType_3 0 "UNKNOWN" 1 "OPENING" 2 "CLOSING" 3 "MERGING" 4 "SPLITTING" 5 "ROAD_MERGING" 6 "ROAD_SPLITTING" ;
VAL_ 1228 Ego_Lane_NextTopoSide_3 0 "LEFT" 1 "RIGHT" ;
VAL_ 1228 Ego_Lane_NextTopoType_4 0 "UNKNOWN" 1 "OPENING" 2 "CLOSING" 3 "MERGING" 4 "SPLITTING" 5 "ROAD_MERGING" 6 "ROAD_SPLITTING" ;
VAL_ 1228 Ego_Lane_NextTopoSide_4 0 "LEFT" 1 "RIGHT" ;
VAL_ 1228 Ego_Lane_CurrBoundary_Type_R 0 "TYPE_SOLID_LINE" 1 "TYPE_DASHED_LINE" 2 "TYPE_DOUBLE_DASHED_DASHED" 3 "TYPE_DOUBLE_DASHED_SOLID" 4 "TYPE_DOUBLE_SOLID_DASHED" 5 "TYPE_DOUBLE_SOLID_SOLID" 6 "TYPE_MULTIPLE" 7 "TYPE_MULTIPLE_WARNING" 8 "TYPE_CAR_POOL" 9 "TYPE_ASPHALT_JOIN" 10 "TYPE_BOTTS_DOTS" 11 "TYPE_ROAD_EDGE" 12 "TYPE_GUARDRAIL" 13 "TYPE_CURBSTONE" 14 "TYPE_WALL" 15 "TYPE_TRAFFIC_CONE" 16 "TYPE_DELINEATOR_POST" 17 "TYPE_PARKING_CAR" 18 "TYPE_UNKNOWN_RAISED" 19 "TYPE_UNKNOWN" ;
VAL_ 1228 Ego_Lane_NextBoundary_Type_R_1 0 "TYPE_SOLID_LINE" 1 "TYPE_DASHED_LINE" 2 "TYPE_DOUBLE_DASHED_DASHED" 3 "TYPE_DOUBLE_DASHED_SOLID" 4 "TYPE_DOUBLE_SOLID_DASHED" 5 "TYPE_DOUBLE_SOLID_SOLID" 6 "TYPE_MULTIPLE" 7 "TYPE_MULTIPLE_WARNING" 8 "TYPE_CAR_POOL" 9 "TYPE_ASPHALT_JOIN" 10 "TYPE_BOTTS_DOTS" 11 "TYPE_ROAD_EDGE" 12 "TYPE_GUARDRAIL" 13 "TYPE_CURBSTONE" 14 "TYPE_WALL" 15 "TYPE_TRAFFIC_CONE" 16 "TYPE_DELINEATOR_POST" 17 "TYPE_PARKING_CAR" 18 "TYPE_UNKNOWN_RAISED" 19 "TYPE_UNKNOWN" ;
VAL_ 1228 Ego_Lane_NextBoundary_Type_R_2 0 "TYPE_SOLID_LINE" 1 "TYPE_DASHED_LINE" 2 "TYPE_DOUBLE_DASHED_DASHED" 3 "TYPE_DOUBLE_DASHED_SOLID" 4 "TYPE_DOUBLE_SOLID_DASHED" 5 "TYPE_DOUBLE_SOLID_SOLID" 6 "TYPE_MULTIPLE" 7 "TYPE_MULTIPLE_WARNING" 8 "TYPE_CAR_POOL" 9 "TYPE_ASPHALT_JOIN" 10 "TYPE_BOTTS_DOTS" 11 "TYPE_ROAD_EDGE" 12 "TYPE_GUARDRAIL" 13 "TYPE_CURBSTONE" 14 "TYPE_WALL" 15 "TYPE_TRAFFIC_CONE" 16 "TYPE_DELINEATOR_POST" 17 "TYPE_PARKING_CAR" 18 "TYPE_UNKNOWN_RAISED" 19 "TYPE_UNKNOWN" ;
VAL_ 1228 Ego_Lane_NextBoundary_Type_R_3 0 "TYPE_SOLID_LINE" 1 "TYPE_DASHED_LINE" 2 "TYPE_DOUBLE_DASHED_DASHED" 3 "TYPE_DOUBLE_DASHED_SOLID" 4 "TYPE_DOUBLE_SOLID_DASHED" 5 "TYPE_DOUBLE_SOLID_SOLID" 6 "TYPE_MULTIPLE" 7 "TYPE_MULTIPLE_WARNING" 8 "TYPE_CAR_POOL" 9 "TYPE_ASPHALT_JOIN" 10 "TYPE_BOTTS_DOTS" 11 "TYPE_ROAD_EDGE" 12 "TYPE_GUARDRAIL" 13 "TYPE_CURBSTONE" 14 "TYPE_WALL" 15 "TYPE_TRAFFIC_CONE" 16 "TYPE_DELINEATOR_POST" 17 "TYPE_PARKING_CAR" 18 "TYPE_UNKNOWN_RAISED" 19 "TYPE_UNKNOWN" ;
VAL_ 1228 Ego_Lane_NextBoundary_Type_R_4 0 "TYPE_SOLID_LINE" 1 "TYPE_DASHED_LINE" 2 "TYPE_DOUBLE_DASHED_DASHED" 3 "TYPE_DOUBLE_DASHED_SOLID" 4 "TYPE_DOUBLE_SOLID_DASHED" 5 "TYPE_DOUBLE_SOLID_SOLID" 6 "TYPE_MULTIPLE" 7 "TYPE_MULTIPLE_WARNING" 8 "TYPE_CAR_POOL" 9 "TYPE_ASPHALT_JOIN" 10 "TYPE_BOTTS_DOTS" 11 "TYPE_ROAD_EDGE" 12 "TYPE_GUARDRAIL" 13 "TYPE_CURBSTONE" 14 "TYPE_WALL" 15 "TYPE_TRAFFIC_CONE" 16 "TYPE_DELINEATOR_POST" 17 "TYPE_PARKING_CAR" 18 "TYPE_UNKNOWN_RAISED" 19 "TYPE_UNKNOWN" ;
VAL_ 1228 Ego_Lane_CurrBoundary_Type_L 0 "TYPE_SOLID_LINE" 1 "TYPE_DASHED_LINE" 2 "TYPE_DOUBLE_DASHED_DASHED" 3 "TYPE_DOUBLE_DASHED_SOLID" 4 "TYPE_DOUBLE_SOLID_DASHED" 5 "TYPE_DOUBLE_SOLID_SOLID" 6 "TYPE_MULTIPLE" 7 "TYPE_MULTIPLE_WARNING" 8 "TYPE_CAR_POOL" 9 "TYPE_ASPHALT_JOIN" 10 "TYPE_BOTTS_DOTS" 11 "TYPE_ROAD_EDGE" 12 "TYPE_GUARDRAIL" 13 "TYPE_CURBSTONE" 14 "TYPE_WALL" 15 "TYPE_TRAFFIC_CONE" 16 "TYPE_DELINEATOR_POST" 17 "TYPE_PARKING_CAR" 18 "TYPE_UNKNOWN_RAISED" 19 "TYPE_UNKNOWN" ;
VAL_ 1228 Ego_Lane_NextBoundary_Type_L_1 0 "TYPE_SOLID_LINE" 1 "TYPE_DASHED_LINE" 2 "TYPE_DOUBLE_DASHED_DASHED" 3 "TYPE_DOUBLE_DASHED_SOLID" 4 "TYPE_DOUBLE_SOLID_DASHED" 5 "TYPE_DOUBLE_SOLID_SOLID" 6 "TYPE_MULTIPLE" 7 "TYPE_MULTIPLE_WARNING" 8 "TYPE_CAR_POOL" 9 "TYPE_ASPHALT_JOIN" 10 "TYPE_BOTTS_DOTS" 11 "TYPE_ROAD_EDGE" 12 "TYPE_GUARDRAIL" 13 "TYPE_CURBSTONE" 14 "TYPE_WALL" 15 "TYPE_TRAFFIC_CONE" 16 "TYPE_DELINEATOR_POST" 17 "TYPE_PARKING_CAR" 18 "TYPE_UNKNOWN_RAISED" 19 "TYPE_UNKNOWN" ;
VAL_ 1228 Ego_Lane_NextBoundary_Type_L_2 0 "TYPE_SOLID_LINE" 1 "TYPE_DASHED_LINE" 2 "TYPE_DOUBLE_DASHED_DASHED" 3 "TYPE_DOUBLE_DASHED_SOLID" 4 "TYPE_DOUBLE_SOLID_DASHED" 5 "TYPE_DOUBLE_SOLID_SOLID" 6 "TYPE_MULTIPLE" 7 "TYPE_MULTIPLE_WARNING" 8 "TYPE_CAR_POOL" 9 "TYPE_ASPHALT_JOIN" 10 "TYPE_BOTTS_DOTS" 11 "TYPE_ROAD_EDGE" 12 "TYPE_GUARDRAIL" 13 "TYPE_CURBSTONE" 14 "TYPE_WALL" 15 "TYPE_TRAFFIC_CONE" 16 "TYPE_DELINEATOR_POST" 17 "TYPE_PARKING_CAR" 18 "TYPE_UNKNOWN_RAISED" 19 "TYPE_UNKNOWN" ;
VAL_ 1228 Ego_Lane_NextBoundary_Type_L_3 0 "TYPE_SOLID_LINE" 1 "TYPE_DASHED_LINE" 2 "TYPE_DOUBLE_DASHED_DASHED" 3 "TYPE_DOUBLE_DASHED_SOLID" 4 "TYPE_DOUBLE_SOLID_DASHED" 5 "TYPE_DOUBLE_SOLID_SOLID" 6 "TYPE_MULTIPLE" 7 "TYPE_MULTIPLE_WARNING" 8 "TYPE_CAR_POOL" 9 "TYPE_ASPHALT_JOIN" 10 "TYPE_BOTTS_DOTS" 11 "TYPE_ROAD_EDGE" 12 "TYPE_GUARDRAIL" 13 "TYPE_CURBSTONE" 14 "TYPE_WALL" 15 "TYPE_TRAFFIC_CONE" 16 "TYPE_DELINEATOR_POST" 17 "TYPE_PARKING_CAR" 18 "TYPE_UNKNOWN_RAISED" 19 "TYPE_UNKNOWN" ;
VAL_ 1228 Ego_Lane_NextBoundary_Type_L_4 0 "TYPE_SOLID_LINE" 1 "TYPE_DASHED_LINE" 2 "TYPE_DOUBLE_DASHED_DASHED" 3 "TYPE_DOUBLE_DASHED_SOLID" 4 "TYPE_DOUBLE_SOLID_DASHED" 5 "TYPE_DOUBLE_SOLID_SOLID" 6 "TYPE_MULTIPLE" 7 "TYPE_MULTIPLE_WARNING" 8 "TYPE_CAR_POOL" 9 "TYPE_ASPHALT_JOIN" 10 "TYPE_BOTTS_DOTS" 11 "TYPE_ROAD_EDGE" 12 "TYPE_GUARDRAIL" 13 "TYPE_CURBSTONE" 14 "TYPE_WALL" 15 "TYPE_TRAFFIC_CONE" 16 "TYPE_DELINEATOR_POST" 17 "TYPE_PARKING_CAR" 18 "TYPE_UNKNOWN_RAISED" 19 "TYPE_UNKNOWN" ;
VAL_ 1229 Ego_Lane_NextHotspot_Type_1 0 "HOTSPOT_NONE" 1 "HOTSPOT_BRAKE" 2 "HOTSPOT_LC_IN" 3 "HOTSPOT_LC_OUT" 4 "HOTSPOT_STOP" 5 "RESERVED" 6 "RESERVED" 7 "RESERVED" ;
VAL_ 1229 Ego_Lane_NextHotspot_Side_1 0 "LEFT" 1 "RIGHT" ;
VAL_ 1229 Ego_Lane_NextHotspot_Type_2 0 "HOTSPOT_NONE" 1 "HOTSPOT_BRAKE" 2 "HOTSPOT_LC_IN" 3 "HOTSPOT_LC_OUT" 4 "HOTSPOT_STOP" 5 "RESERVED" 6 "RESERVED" 7 "RESERVED" ;
VAL_ 1229 Ego_Lane_NextHotspot_Side_2 0 "LEFT" 1 "RIGHT" ;
VAL_ 1229 Ego_Lane_NextHotspot_Type_3 0 "HOTSPOT_NONE" 1 "HOTSPOT_BRAKE" 2 "HOTSPOT_LC_IN" 3 "HOTSPOT_LC_OUT" 4 "HOTSPOT_STOP" 5 "RESERVED" 6 "RESERVED" 7 "RESERVED" ;
VAL_ 1229 Ego_Lane_NextHotspot_Side_3 0 "LEFT" 1 "RIGHT" ;
VAL_ 1229 Ego_Lane_NextHotspot_Type_4 0 "HOTSPOT_NONE" 1 "HOTSPOT_BRAKE" 2 "HOTSPOT_LC_IN" 3 "HOTSPOT_LC_OUT" 4 "HOTSPOT_STOP" 5 "RESERVED" 6 "RESERVED" 7 "RESERVED" ;
VAL_ 1229 Ego_Lane_NextHotspot_Side_4 0 "LEFT" 1 "RIGHT" ;
VAL_ 1230 Left_CurrentSpeedLimit_Type 0 "EFFECTIVE" 1 "IMPLICIT" 2 "UNKNOWN" 3 "RESERVED" ;
VAL_ 1230 Left_NextSpeedLimit_Type_1 0 "EFFECTIVE" 1 "IMPLICIT" 2 "UNKNOWN" 3 "RESERVED" ;
VAL_ 1230 Left_NextSpeedLimit_Type_2 0 "EFFECTIVE" 1 "IMPLICIT" 2 "UNKNOWN" 3 "RESERVED" ;
VAL_ 1230 Left_NextSpeedLimit_Type_3 0 "EFFECTIVE" 1 "IMPLICIT" 2 "UNKNOWN" 3 "RESERVED" ;
VAL_ 1230 Left_NextSpeedLimit_Type_4 0 "EFFECTIVE" 1 "IMPLICIT" 2 "UNKNOWN" 3 "RESERVED" ;
VAL_ 1230 Left_NextTopo_Type_1 0 "UNKNOWN" 1 "OPENING" 2 "CLOSING" 3 "MERGING" 4 "SPLITTING" 5 "ROAD_MERGING" 6 "ROAD_SPLITTING" ;
VAL_ 1230 Left_NextTopo_Side_1 0 "LEFT" 1 "RIGHT" ;
VAL_ 1230 Left_NextTopo_Type_2 0 "UNKNOWN" 1 "OPENING" 2 "CLOSING" 3 "MERGING" 4 "SPLITTING" 5 "ROAD_MERGING" 6 "ROAD_SPLITTING" ;
VAL_ 1230 Left_NextTopo_Side_2 0 "LEFT" 1 "RIGHT" ;
VAL_ 1230 Left_NextTopo_Type_3 0 "UNKNOWN" 1 "OPENING" 2 "CLOSING" 3 "MERGING" 4 "SPLITTING" 5 "ROAD_MERGING" 6 "ROAD_SPLITTING" ;
VAL_ 1230 Left_NextTopo_Side_3 0 "LEFT" 1 "RIGHT" ;
VAL_ 1230 Left_NextTopo_Type_4 0 "UNKNOWN" 1 "OPENING" 2 "CLOSING" 3 "MERGING" 4 "SPLITTING" 5 "ROAD_MERGING" 6 "ROAD_SPLITTING" ;
VAL_ 1230 Left_NextTopo_Side_4 0 "LEFT" 1 "RIGHT" ;
VAL_ 1231 Right_CurrentSpeedLimit_Type 0 "EFFECTIVE" 1 "IMPLICIT" 2 "UNKNOWN" 3 "RESERVED" ;
VAL_ 1231 Right_NextSpeedLimit_Type_1 0 "EFFECTIVE" 1 "IMPLICIT" 2 "UNKNOWN" 3 "RESERVED" ;
VAL_ 1231 Right_NextSpeedLimit_Type_2 0 "EFFECTIVE" 1 "IMPLICIT" 2 "UNKNOWN" 3 "RESERVED" ;
VAL_ 1231 Right_NextSpeedLimit_Type_3 0 "EFFECTIVE" 1 "IMPLICIT" 2 "UNKNOWN" 3 "RESERVED" ;
VAL_ 1231 Right_NextSpeedLimit_Type_4 0 "EFFECTIVE" 1 "IMPLICIT" 2 "UNKNOWN" 3 "RESERVED" ;
VAL_ 1231 Right_NextTopo_Type_1 0 "UNKNOWN" 1 "OPENING" 2 "CLOSING" 3 "MERGING" 4 "SPLITTING" 5 "ROAD_MERGING" 6 "ROAD_SPLITTING" ;
VAL_ 1231 Right_NextTopo_Side_1 0 "LEFT" 1 "RIGHT" ;
VAL_ 1231 Right_NextTopo_Type_2 0 "UNKNOWN" 1 "OPENING" 2 "CLOSING" 3 "MERGING" 4 "SPLITTING" 5 "ROAD_MERGING" 6 "ROAD_SPLITTING" ;
VAL_ 1231 Right_NextTopo_Side_2 0 "LEFT" 1 "RIGHT" ;
VAL_ 1231 Right_NextTopo_Type_3 0 "UNKNOWN" 1 "OPENING" 2 "CLOSING" 3 "MERGING" 4 "SPLITTING" 5 "ROAD_MERGING" 6 "ROAD_SPLITTING" ;
VAL_ 1231 Right_NextTopo_Side_3 0 "LEFT" 1 "RIGHT" ;
VAL_ 1231 Right_NextTopo_Type_4 0 "UNKNOWN" 1 "OPENING" 2 "CLOSING" 3 "MERGING" 4 "SPLITTING" 5 "ROAD_MERGING" 6 "ROAD_SPLITTING" ;
VAL_ 1231 Right_NextTopo_Side_4 0 "LEFT" 1 "RIGHT" ;
VAL_ 800 DMSAdoWrnngDspCmdHSC4 0 "Unavailable" 1 "Off" 2 "On" ;
VAL_ 800 DMSAudReqHSC4 0 "Unavailable" 1 "Off" 2 "On" ;
VAL_ 800 DMSDspCmdHSC4 0 "Unavailable" 1 "Off" 2 "On" ;
VAL_ 800 DMSHapticWrnngDspCmdHSC4 0 "Unavailable" 1 "Off" 2 "On" ;
VAL_ 800 DMSStsHSC4 0 "Off" 1 "Standby" 2 "Active" 3 "Fault" 4 "Camera Blocked" 5 "Initialization" ;
VAL_ 800 DMSVbnLvlReqHSC4 0 "Unavailable" 1 "Off" 2 "On" ;
VAL_ 800 DMSWrnngReqHSC4 0 "No request" 1 "Fatigue request" 2 "Distraction request" ;
VAL_ 800 DrvrAbnormBehvorHSC4 0 "Unknown" 1 "No abnormal behaviour" 2 "Telephone calls" 3 "Smoking" 4 "Drinking water" 5 "Eating" 6 "Reserved" 7 "Reserved" 8 "Reserved" 9 "Reserved" 10 "Reserved" 11 "Reserved" 12 "Reserved" 13 "Reserved" 14 "Reserved" 15 "Reserved" ;
VAL_ 800 DrvrDstcnStsHSC4 0 "Unknown" 1 "No distraction" 2 "Low level distraction" 3 "Middle level distraction" 4 "High level distraction" 5 "Reserve" 6 "Reserve" 7 "Reserve" ;
VAL_ 800 DrvrFtgLvlHSC4 0 "Unknown" 1 "No Drowsiness" 2 "Low level Drowsiness" 3 "Middle level Drowsiness" 4 "High level Drowsiness" 5 "Reserve" 6 "Reserve" 7 "Reserve" ;
VAL_ 800 DrvrGazeRgnHSC4 0 "Init/Unknown" 1 "Driver Side of Windscreen" 2 "Copilot Side of Windscreen" 3 "Left Rear View Mirror" 4 "Right Rear View Mirror" 5 "Left Side Window" 6 "Right Side Window" 7 "Central Rear View Mirror" 8 "Central driver's Instrument Cluster(speed gauge,etc.)" 9 "Head-up display" 10 "Navigation Display" 11 "Middle Instrument Cluster£¨A/C,radio,etc.£©" 12 "Steering Wheel(e.g.button area)" 13 "Left Seat Foot Area" 14 "Right Seat Foot Area &Workbench" 15 "Left Side door area" 16 "Right Side door area" 17 "reserved" 18 "reserved" 19 "reserved" 20 "reserved" 21 "reserved" 22 "reserved" 23 "reserved" 24 "reserved" 25 "reserved" 26 "reserved" 27 "reserved" 28 "reserved" 29 "reserved" 30 "reserved" 31 "reserved" ;
VAL_ 800 DrvrPrstHSC4 0 "Unknown" 1 "Driver Not Presence" 2 "Driver  Presence" ;
VAL_ 800 EyeOnRoadHSC4 0 "Unavailable" 1 "Eyes On Road" 2 "Eyes Off Road - driving task related region" 3 "Eyes Off Road - non-driving task related region" ;
VAL_ 800 SpfngDetHSC4 0 "Unknown" 1 "Not Detected" 2 "Detected" ;
VAL_ 453 EPS_LatDrvLvl12SrvAvl 0 "NotAvailable" 1 "FailureDetected" 2 "Available" 3 "Reserved" ;
VAL_ 453 EPS_LatMCHptcWrnSrvAvl 0 "NotAvailable" 1 "FailureDetected" 2 "Available" 3 "Reserved" ;
VAL_ 453 EPS_ActRoadWheelAngState 0 "NotAvailable" 1 "FailureDetected" 2 "Available" 3 "Reserved" ;
VAL_ 453 EPS_LatMCRoadWheelAngActive 0 "RdWhlAgReq not active" 1 "RdWhlAgReq active" ;
VAL_ 1210 DisplayedLaneMarking4Y 1 "0x00...0x7F: distance left from ego center" 2 "0x80...0xFF: distance right from ego center" ;
VAL_ 1210 DisplayedLaneMarking3Y 1 "0x00...0x7F: distance left from ego center" 2 "0x80...0xFF: distance right from ego center" ;
VAL_ 1210 DisplayedLaneMarking2Y 1 "0x00...0x7F: distance left from ego center" 2 "0x80...0xFF: distance right from ego center" ;
VAL_ 1210 DisplayedLaneMarking1Y 1 "0x00...0x7F: distance left from ego center" 2 "0x80...0xFF: distance right from ego center" ;
VAL_ 1210 DisplayedLaneMarking4Type 0 "0x00: dashed line" 1 "0x01: solid line" 2 "0x02: neighboring lane blocked" 3 "0x03: reserved" ;
VAL_ 1210 DisplayedLaneMarking3Type 0 "0x00: dashed line" 1 "0x01: solid line" 2 "0x02: neighboring lane blocked" 3 "0x03: reserved" ;
VAL_ 1210 DisplayedLaneMarking2Type 0 "0x00: dashed line" 1 "0x01: solid line" 2 "0x02: neighboring lane blocked" 3 "0x03: reserved" ;
VAL_ 1210 DisplayedLaneMarking1Type 0 "0x00: dashed line" 1 "0x01: solid line" 2 "0x02: neighboring lane blocked" 3 "0x03: reserved" ;
VAL_ 1210 DisplayedLaneMarking4Color 0 "0x00: no display" 1 "0x01: gray" 2 "0x02: white" 3 "0x03: green" 4 "0x04: yellow" 5 "0x05: red" 6 "0x06: blue" 7 "0x07: red flashing" ;
VAL_ 1210 DisplayedLaneMarking3Color 0 "0x00: no display" 1 "0x01: gray" 2 "0x02: white" 3 "0x03: green" 4 "0x04: yellow" 5 "0x05: red" 6 "0x06: blue" 7 "0x07: red flashing" ;
VAL_ 1210 DisplayedLaneMarking2Color 0 "0x00: no display" 1 "0x01: gray" 2 "0x02: white" 3 "0x03: green" 4 "0x04: yellow" 5 "0x05: red" 6 "0x06: blue" 7 "0x07: red flashing" ;
VAL_ 1210 DisplayedLaneMarking1Color 0 "0x00: no display" 1 "0x01: gray" 2 "0x02: white" 3 "0x03: green" 4 "0x04: yellow" 5 "0x05: red" 6 "0x06: blue" 7 "0x07: red flashing" ;
VAL_ 1210 Indicator16 0 "no display" 1 "display icon" ;
VAL_ 1210 Indicator15 0 "no display" 1 "display icon" ;
VAL_ 1210 Indicator14 0 "no display" 1 "display icon" ;
VAL_ 1210 Indicator13 0 "no display" 1 "display icon" ;
VAL_ 1210 Indicator12 0 "no display" 1 "display icon" ;
VAL_ 1210 Indicator11 0 "no display" 1 "display icon" ;
VAL_ 1210 Indicator10 0 "no display" 1 "display icon" ;
VAL_ 1210 Indicator09 0 "no display" 1 "display icon" ;
VAL_ 1210 Indicator08 0 "no display" 1 "display icon" ;
VAL_ 1210 Indicator07 0 "no display" 1 "display icon" ;
VAL_ 1210 Indicator06 0 "no display" 1 "display icon" ;
VAL_ 1210 Indicator05 0 "no display" 1 "display icon" ;
VAL_ 1210 Indicator04 0 "no display" 1 "display icon" ;
VAL_ 1210 Indicator03 0 "no display" 1 "display icon" ;
VAL_ 1210 Indicator02 0 "no display" 1 "display icon" ;
VAL_ 1210 Indicator01 0 "no display" 1 "display icon" ;
VAL_ 1210 ACC_ICON_LADI 0 "Not shown" 1 "Shown" 2 "Blinking" ;
VAL_ 1210 EgoDistanceToRightLaneMarking 1 "0x00...0x3F: distance positive" 2 "0x40...0x7F: distance negative" ;
VAL_ 1210 CurvatureInformation 1 "0x00...0x3F: distance positive" 2 "0x40...0x7F: distance negative" ;
VAL_ 1210 TrafficSignSpeedLimit 1 "0x00: no speed limit" 2 "0x01...0x1E: value of speed limit" ;
VAL_ 1210 SensorConeRearLeft 0 "0x00: no display" 1 "0x01: short cone gray" 2 "0x02: long cone gray" 3 "0x03: short cone red" ;
VAL_ 1210 SensorConeRearRight 0 "0x00: no display" 1 "0x01: short cone gray" 2 "0x02: long cone gray" 3 "0x03: short cone red" ;
VAL_ 1210 SensorConeFrontLeft 0 "0x00: no display" 1 "0x01: short cone gray" 2 "0x02: long cone gray" 3 "0x03: short cone red" ;
VAL_ 1210 SensorConeFrontRight 0 "0x00: no display" 1 "0x01: short cone gray" 2 "0x02: long cone gray" 3 "0x03: short cone red" ;
VAL_ 1210 SensorConeFrontCenter 0 "0x00: no display" 1 "0x01: short cone gray" 2 "0x02: long cone gray" 3 "0x03: short cone red" ;
VAL_ 1210 NeighboringVehicle1VehicleType 0 "0x00: vehicle not present" 1 "0x01: passenger car" 2 "0x02: truck" 3 "0x03: motorbike" 4 "0x04: other" 5 "0x05: reserved" 6 "0x06: reserved" 7 "0x07: error" ;
VAL_ 1210 NeighboringVehicle1X 1 "0x00...0xFF: distance (positive values are left, negative values right from ego center)" ;
VAL_ 1210 NeighboringVehicle1Y 1 "0x00...0x7F: distance left from ego center" 2 "0x80...0xFF: distance right from ego center" ;
VAL_ 1210 NeighboringVehicle1AugmentedData 0 "0x00: normalDriving" 1 "0x01: selected as lead vehicle" 2 "0x02: located in ego blind spot" 3 "0x03: close distance to ego" 4 "0x04: strong deceleration" 5 "0x05: strong acceleration" 6 "0x06: lane change to left" 7 "0x07: lane change to right" ;
VAL_ 1210 NeighboringVehicle2VehicleType 0 "0x00: vehicle not present" 1 "0x01: passenger car" 2 "0x02: truck" 3 "0x03: motorbike" 4 "0x04: other" 5 "0x05: reserved" 6 "0x06: reserved" 7 "0x07: error" ;
VAL_ 1210 NeighboringVehicle2X 1 "0x00...0xFF: distance (positive values are left, negative values right from ego center)" ;
VAL_ 1210 NeighboringVehicle2Y 1 "0x00...0x7F: distance left from ego center" 2 "0x80...0xFF: distance right from ego center" ;
VAL_ 1210 NeighboringVehicle2AugmentedData 0 "0x00: normalDriving" 1 "0x01: selected as lead vehicle" 2 "0x02: located in ego blind spot" 3 "0x03: close distance to ego" 4 "0x04: strong deceleration" 5 "0x05: strong acceleration" 6 "0x06: lane change to left" 7 "0x07: lane change to right" ;
VAL_ 1210 NeighboringVehicle3VehicleType 0 "0x00: vehicle not present" 1 "0x01: passenger car" 2 "0x02: truck" 3 "0x03: motorbike" 4 "0x04: other" 5 "0x05: reserved" 6 "0x06: reserved" 7 "0x07: error" ;
VAL_ 1210 NeighboringVehicle3X 1 "0x00...0xFF: distance (positive values are left, negative values right from ego center)" ;
VAL_ 1210 NeighboringVehicle3Y 1 "0x00...0x7F: distance left from ego center" 2 "0x80...0xFF: distance right from ego center" ;
VAL_ 1210 NeighboringVehicle3AugmentedData 0 "0x00: normalDriving" 1 "0x01: selected as lead vehicle" 2 "0x02: located in ego blind spot" 3 "0x03: close distance to ego" 4 "0x04: strong deceleration" 5 "0x05: strong acceleration" 6 "0x06: lane change to left" 7 "0x07: lane change to right" ;
VAL_ 1210 NeighboringVehicle4VehicleType 0 "0x00: vehicle not present" 1 "0x01: passenger car" 2 "0x02: truck" 3 "0x03: motorbike" 4 "0x04: other" 5 "0x05: reserved" 6 "0x06: reserved" 7 "0x07: error" ;
VAL_ 1210 NeighboringVehicle4X 1 "0x00...0xFF: distance (positive values are left, negative values right from ego center)" ;
VAL_ 1210 NeighboringVehicle4Y 1 "0x00...0x7F: distance left from ego center" 2 "0x80...0xFF: distance right from ego center" ;
VAL_ 1210 NeighboringVehicle4AugmentedData 0 "0x00: normalDriving" 1 "0x01: selected as lead vehicle" 2 "0x02: located in ego blind spot" 3 "0x03: close distance to ego" 4 "0x04: strong deceleration" 5 "0x05: strong acceleration" 6 "0x06: lane change to left" 7 "0x07: lane change to right" ;
VAL_ 1210 NeighboringVehicle5VehicleType 0 "0x00: vehicle not present" 1 "0x01: passenger car" 2 "0x02: truck" 3 "0x03: motorbike" 4 "0x04: other" 5 "0x05: reserved" 6 "0x06: reserved" 7 "0x07: error" ;
VAL_ 1210 NeighboringVehicle5X 1 "0x00...0xFF: distance (positive values are left, negative values right from ego center)" ;
VAL_ 1210 NeighboringVehicle5Y 1 "0x00...0x7F: distance left from ego center" 2 "0x80...0xFF: distance right from ego center" ;
VAL_ 1210 NeighboringVehicle5AugmentedData 0 "0x00: normalDriving" 1 "0x01: selected as lead vehicle" 2 "0x02: located in ego blind spot" 3 "0x03: close distance to ego" 4 "0x04: strong deceleration" 5 "0x05: strong acceleration" 6 "0x06: lane change to left" 7 "0x07: lane change to right" ;
VAL_ 1210 NeighboringVehicle6VehicleType 0 "0x00: vehicle not present" 1 "0x01: passenger car" 2 "0x02: truck" 3 "0x03: motorbike" 4 "0x04: other" 5 "0x05: reserved" 6 "0x06: reserved" 7 "0x07: error" ;
VAL_ 1210 NeighboringVehicle6X 1 "0x00...0xFF: distance (positive values are left, negative values right from ego center)" ;
VAL_ 1210 LedHadState 0 "offState" 1 "initState" 2 "passiveState" 3 "readyState" 4 "requestState" 5 "activeControlState" 6 "activePreWarningState" 7 "handsOnState" 8 "takeOverRequestState" 9 "takeOverRequestEmergencyState" 10 "minimalRiskManeuverState" 11 "reserved1" 12 "reserved2" 13 "reserved3" 14 "reserved4" 15 "reserved5" ;
VAL_ 1210 NeighboringVehicle6Y 1 "0x00...0x7F: distance left from ego center" 2 "0x80...0xFF: distance right from ego center" ;
VAL_ 1210 NeighboringVehicle6AugmentedData 0 "0x00: normalDriving" 1 "0x01: selected as lead vehicle" 2 "0x02: located in ego blind spot" 3 "0x03: close distance to ego" 4 "0x04: strong deceleration" 5 "0x05: strong acceleration" 6 "0x06: lane change to left" 7 "0x07: lane change to right" ;
VAL_ 1210 NeighboringVehicle7VehicleType 0 "0x00: vehicle not present" 1 "0x01: passenger car" 2 "0x02: truck" 3 "0x03: motorbike" 4 "0x04: other" 5 "0x05: reserved" 6 "0x06: reserved" 7 "0x07: error" ;
VAL_ 1210 NeighboringVehicle7X 1 "0x00...0xFF: distance (positive values are left, negative values right from ego center)" ;
VAL_ 1210 NeighboringVehicle7Y 1 "0x00...0x7F: distance left from ego center" 2 "0x80...0xFF: distance right from ego center" ;
VAL_ 1210 NeighboringVehicle7AugmentedData 0 "0x00: normalDriving" 1 "0x01: selected as lead vehicle" 2 "0x02: located in ego blind spot" 3 "0x03: close distance to ego" 4 "0x04: strong deceleration" 5 "0x05: strong acceleration" 6 "0x06: lane change to left" 7 "0x07: lane change to right" ;
VAL_ 1210 NeighboringVehicle8VehicleType 0 "0x00: vehicle not present" 1 "0x01: passenger car" 2 "0x02: truck" 3 "0x03: motorbike" 4 "0x04: other" 5 "0x05: reserved" 6 "0x06: reserved" 7 "0x07: error" ;
VAL_ 1210 HwaHfStatus 0 "0x00: no display" 1 "0x01: not availabe" 2 "0x02: available" 3 "0x03: active" 4 "0x04: longitudinal override" 5 "0x05: lateral override" 6 "0x06: error" 7 "0x07: reserved" ;
VAL_ 1210 NeighboringVehicle8X 1 "0x00...0xFF: distance (positive values are left, negative values right from ego center)" ;
VAL_ 1210 NeighboringVehicle8Y 1 "0x00...0x7F: distance left from ego center" 2 "0x80...0xFF: distance right from ego center" ;
VAL_ 1210 NeighboringVehicle8AugmentedData 0 "0x00: normalDriving" 1 "0x01: selected as lead vehicle" 2 "0x02: located in ego blind spot" 3 "0x03: close distance to ego" 4 "0x04: strong deceleration" 5 "0x05: strong acceleration" 6 "0x06: lane change to left" 7 "0x07: lane change to right" ;
VAL_ 1210 HwaHonStatus 0 "0x00: no display" 1 "0x01: not availabe" 2 "0x02: available" 3 "0x03: active" 4 "0x04: longitudinal override" 5 "0x05: lateral override" 6 "0x06: error" 7 "0x07: reserved" ;
VAL_ 1210 HwaAccStatus 0 "0x00: no display" 1 "0x01: not availabe" 2 "0x02: available" 3 "0x03: active" 4 "0x04: longitudinal override" 5 "0x05: lateral override" 6 "0x06: error" 7 "0x07: reserved" ;
VAL_ 1210 SetSpeed 1 "0...254: set speed" 2 "255: reserved" ;
VAL_ 1210 SetSpeedColor 0 "0x00: no display" 1 "0x01: gray" 2 "0x02: white" 3 "0x03: green" 4 "0x04: yellow" 5 "0x05: red" 6 "0x06: blue" 7 "0x07: reserved" ;
VAL_ 1210 DisplayedEgoSpeed 1 "0...254: set speed" 2 "255: reserved" ;
VAL_ 1210 DisplayedEgoSpeedColor 0 "0x00: no display" 1 "0x01: gray" 2 "0x02: white" 3 "0x03: green" 4 "0x04: yellow" 5 "0x05: red" 6 "0x06: blue" 7 "0x07: reserved" ;
VAL_ 1210 DisplayedLaneMarkingLeftType 0 "0x00: dashed line" 1 "0x01: solid line" 2 "0x02: neighboring lane blocked" 3 "0x03: reserved" ;
VAL_ 1210 DisplayedLaneMarkingLeftColor 0 "0x00: no display" 1 "0x01: gray" 2 "0x02: white" 3 "0x03: green" 4 "0x04: yellow" 5 "0x05: red" 6 "0x06: blue" 7 "0x07: red flashing" ;
VAL_ 1210 DisplayedLaneMarkingRightType 0 "0x00: dashed line" 1 "0x01: solid line" 2 "0x02: neighboring lane blocked" 3 "0x03: reserved" ;
VAL_ 1210 DisplayedLaneMarkingRightColor 0 "0x00: no display" 1 "0x01: gray" 2 "0x02: white" 3 "0x03: green" 4 "0x04: yellow" 5 "0x05: red" 6 "0x06: blue" 7 "0x07: red flashing" ;
VAL_ 1210 TimeGapSetValue 0 "0x00: time gap 0 (closest)" 1 "0x01: time gap 1" 2 "0x02: time gap 2" 3 "0x03: time gap 3" 4 "0x04: time gap 4" 5 "0x05: time gap 5 (farest)" 6 "0x06: reserved" 7 "0x07: reserved" ;
VAL_ 1210 TimeGapColor 0 "0x00: no display" 1 "0x01: gray" 2 "0x02: white" 3 "0x03: green" 4 "0x04: yellow" 5 "0x05: red" 6 "0x06: blue" 7 "0x07: red flashing" ;
VAL_ 1210 EgoLaneChange 0 "0x00: normal driving" 1 "0x01: lane change intention to the left" 2 "0x02: lane change to the left in progress" 3 "0x03: lane change to the left completed" 4 "0x04: lane change intention to the right" 5 "0x05: lane change to the right in progress" 6 "0x06: lane change to the right completed" 7 "0x07: reserved" ;
VAL_ 1210 DisplayedTextMessageId 0 "0x00: no display" 1 "0x01: HWA handsfree not available" 2 "0x02: Unreleased highway section" 3 "0x03: Road condition insufficient" 4 "0x04: Lane markings not present" 5 "0x05: ESP intervention" 6 "0x06: ESP not available" 7 "0x07: Camera unable to see face" 8 "0x08: Seatbelt unfastened" 9 "0x09: Outside speed range" 10 "0x0A: Neighbouring vehicle too close" 11 "0x0B: Front vehicle too close" 12 "0x0C: Driver not focused on the road" 13 "0x0D: Please take a break / Drowsiness detected" 14 "0x0E: Wrong gear selected" 15 "0x0F: Behave according to the intended system usage" 16 "0x10: Please focus on the road" 17 "0x11: Approaching unreleased highway section in 1000 m" 18 "0x...: tbd" ;
VAL_ 1210 PopupTextMessage 0 "0x00: normal text notification (e.g. top middle of the cockpit screen)" 1 "0x01: displayed as prominent pop-up message in a box in the center of the cockpit" 2 "0x02: pop-up on the right side" 3 "0x03: pop-up on the left side" ;
VAL_ 1210 AudioNotificationId 0 "0x00: no sound notification" 1 "0x01: notification" 2 "0x02: warning" 3 "0x03: minimal risk maneuver (safe-stop)" ;
VAL_ 1210 AuxiliarySymbol 0 "0x00: no display" 1 "0x01: coffee cup" 2 "0x02: collision warning" 3 "0x03: hands-on animation (take over request)" ;
VAL_ 1210 EgoLaneAssignment 0 "0x00: emergeny lane" 1 "0x01: 1st next to emergency lane" 2 "0x02: 2nd next to emergency lane" 3 "0x03: 3rd next to emergency lane" ;
VAL_ 1210 EgoDistanceToLeftLaneMarking 1 "0x00...0x3F: distance positive" 2 "0x40...0x7F: distance negative" ;
